VERSION "Version"

NS_ :

BS_:

BU_: ADC RLR SOC Tester

BO_ 530 RLR_Obj_17: 32 RLR
 SG_ SGU17_Msg_CheckSum : 7|8@0+ (1,0) [0|255] ""  ADC
 SG_ SGU17_Msg_AliveCounter : 11|4@0+ (1,0) [0|14] ""  ADC
 SG_ SGU17_BlockCounter : 15|4@0+ (1,0) [0|15] ""  ADC
 SG_ SGU17_Object_ID : 23|8@0+ (1,0) [0|255] ""  ADC
 SG_ SGU17_Object_wExist : 28|5@0+ (0.03125,0) [0|0.96875] ""  ADC
 SG_ SGU17_Object_Type : 31|3@0+ (1,0) [0|7] ""  ADC
 SG_ SGU17_Object_Motion_Pattern : 34|3@0+ (1,0) [0|7] ""  ADC
 SG_ SGU17_Object_wObstacle : 39|5@0+ (0.03125,0) [0|0.96875] ""  ADC
 SG_ SGU17_Object_dx : 43|12@0+ (0.0625,-128) [-128|127.9375] "m"  ADC
 SG_ SGU17_Object_dy : 59|12@0+ (0.125,-128) [-128|127.875] "m"  ADC
 SG_ SGU17_Object_DistLong_rms : 79|16@0+ (0.001953125,0) [0|127.998046875] "m"  ADC
 SG_ SGU17_Obj_DistLat_rms : 95|16@0+ (0.001953125,0) [0|127.998046875] "m"  ADC
 SG_ SGU17_Object_vx : 107|12@0+ (0.0625,-128) [-128|127.9375] "m/s"  ADC
 SG_ SGU17_Object_vy : 123|12@0+ (0.0625,-128) [-128|127.9375] "m/s"  ADC
 SG_ SGU17_Obj_VrelLong_rms : 143|16@0+ (0.001953125,0) [0|127.998046875] "m/s"  ADC
 SG_ SGU17_Obj_Vrelat_rms : 159|16@0+ (0.001953125,0) [0|127.998046875] "m/s"  ADC
 SG_ SGU17_Object_ax : 170|11@0+ (0.03125,-16) [-16|15.96875] "m/s^2"  ADC
 SG_ SGU17_Object_ay : 191|11@0+ (0.03125,-16) [-16|15.96875] "m/s^2"  ADC
 SG_ SGU17_Object_DetStatus : 173|3@0+ (1,0) [0|7] ""  ADC
 SG_ SGU17_LifeCycles_OBJ : 196|8@0+ (1,0) [0|255] ""  ADC
 SG_ SGU17_ObjRCS_17 : 204|10@0+ (0.125,-50) [-50|70] "dBm2"  ADC
 SG_ SGU17_Object_dx_Rear : 209|12@0+ (0.0625,-128) [-128|127.9375] "m"  ADC
 SG_ SGU17_Object_dy_Rear : 229|12@0+ (0.125,-128) [-128|127.875] "m"  ADC

BO_ 531 RLR_Obj_18: 32 RLR
 SG_ SGU18_Msg_CheckSum : 7|8@0+ (1,0) [0|255] ""  ADC
 SG_ SGU18_Msg_AliveCounter : 11|4@0+ (1,0) [0|14] ""  ADC
 SG_ SGU18_BlockCounter : 15|4@0+ (1,0) [0|15] ""  ADC
 SG_ SGU18_Object_ID : 23|8@0+ (1,0) [0|255] ""  ADC
 SG_ SGU18_Object_wExist : 28|5@0+ (0.03125,0) [0|0.96875] ""  ADC
 SG_ SGU18_Object_Type : 31|3@0+ (1,0) [0|7] ""  ADC
 SG_ SGU18_Object_Motion_Pattern : 34|3@0+ (1,0) [0|7] ""  ADC
 SG_ SGU18_Object_wObstacle : 39|5@0+ (0.03125,0) [0|0.96875] ""  ADC
 SG_ SGU18_Object_dx : 43|12@0+ (0.0625,-128) [-128|127.9375] "m"  ADC
 SG_ SGU18_Object_dy : 59|12@0+ (0.125,-128) [-128|127.875] "m"  ADC
 SG_ SGU18_Object_DistLong_rms : 79|16@0+ (0.001953125,0) [0|127.998046875] "m"  ADC
 SG_ SGU18_Obj_DistLat_rms : 95|16@0+ (0.001953125,0) [0|127.998046875] "m"  ADC
 SG_ SGU18_Object_vx : 107|12@0+ (0.0625,-128) [-128|127.9375] "m/s"  ADC
 SG_ SGU18_Object_vy : 123|12@0+ (0.0625,-128) [-128|127.9375] "m/s"  ADC
 SG_ SGU18_Obj_VrelLong_rms : 143|16@0+ (0.001953125,0) [0|127.998046875] "m/s"  ADC
 SG_ SGU18_Obj_Vrelat_rms : 159|16@0+ (0.001953125,0) [0|127.998046875] "m/s"  ADC
 SG_ SGU18_Object_ax : 170|11@0+ (0.03125,-16) [-16|15.96875] "m/s^2"  ADC
 SG_ SGU18_Object_ay : 191|11@0+ (0.03125,-16) [-16|15.96875] "m/s^2"  ADC
 SG_ SGU18_Object_DetStatus : 173|3@0+ (1,0) [0|7] ""  ADC
 SG_ SGU18_LifeCycles_OBJ : 196|8@0+ (1,0) [0|255] ""  ADC
 SG_ SGU18_ObjRCS_18 : 204|10@0+ (0.125,-50) [-50|70] "dBm2"  ADC
 SG_ SGU18_Object_dx_Rear : 209|12@0+ (0.0625,-128) [-128|127.9375] "m"  ADC
 SG_ SGU18_Object_dy_Rear : 229|12@0+ (0.125,-128) [-128|127.875] "m"  ADC

BO_ 532 RLR_Obj_19: 32 RLR
 SG_ SGU19_Msg_CheckSum : 7|8@0+ (1,0) [0|255] ""  ADC
 SG_ SGU19_Msg_AliveCounter : 11|4@0+ (1,0) [0|14] ""  ADC
 SG_ SGU19_BlockCounter : 15|4@0+ (1,0) [0|15] ""  ADC
 SG_ SGU19_Object_ID : 23|8@0+ (1,0) [0|255] ""  ADC
 SG_ SGU19_Object_wExist : 28|5@0+ (0.03125,0) [0|0.96875] ""  ADC
 SG_ SGU19_Object_Type : 31|3@0+ (1,0) [0|7] ""  ADC
 SG_ SGU19_Object_Motion_Pattern : 34|3@0+ (1,0) [0|7] ""  ADC
 SG_ SGU19_Object_wObstacle : 39|5@0+ (0.03125,0) [0|0.96875] ""  ADC
 SG_ SGU19_Object_dx : 43|12@0+ (0.0625,-128) [-128|127.9375] "m"  ADC
 SG_ SGU19_Object_dy : 59|12@0+ (0.125,-128) [-128|127.875] "m"  ADC
 SG_ SGU19_Object_DistLong_rms : 79|16@0+ (0.001953125,0) [0|127.998046875] "m"  ADC
 SG_ SGU19_Obj_DistLat_rms : 95|16@0+ (0.001953125,0) [0|127.998046875] "m"  ADC
 SG_ SGU19_Object_vx : 107|12@0+ (0.0625,-128) [-128|127.9375] "m/s"  ADC
 SG_ SGU19_Object_vy : 123|12@0+ (0.0625,-128) [-128|127.9375] "m/s"  ADC
 SG_ SGU19_Obj_VrelLong_rms : 143|16@0+ (0.001953125,0) [0|127.998046875] "m/s"  ADC
 SG_ SGU19_Obj_Vrelat_rms : 159|16@0+ (0.001953125,0) [0|127.998046875] "m/s"  ADC
 SG_ SGU19_Object_ax : 170|11@0+ (0.03125,-16) [-16|15.96875] "m/s^2"  ADC
 SG_ SGU19_Object_ay : 191|11@0+ (0.03125,-16) [-16|15.96875] "m/s^2"  ADC
 SG_ SGU19_Object_DetStatus : 173|3@0+ (1,0) [0|7] ""  ADC
 SG_ SGU19_LifeCycles_OBJ : 196|8@0+ (1,0) [0|255] ""  ADC
 SG_ SGU19_ObjRCS_19 : 204|10@0+ (0.125,-50) [-50|70] "dBm2"  ADC
 SG_ SGU19_Object_dx_Rear : 209|12@0+ (0.0625,-128) [-128|127.9375] "m"  ADC
 SG_ SGU19_Object_dy_Rear : 229|12@0+ (0.125,-128) [-128|127.875] "m"  ADC

BO_ 533 RLR_Obj_20: 32 RLR
 SG_ SGU20_Msg_CheckSum : 7|8@0+ (1,0) [0|255] ""  ADC
 SG_ SGU20_Msg_AliveCounter : 11|4@0+ (1,0) [0|14] ""  ADC
 SG_ SGU20_BlockCounter : 15|4@0+ (1,0) [0|15] ""  ADC
 SG_ SGU20_Object_ID : 23|8@0+ (1,0) [0|255] ""  ADC
 SG_ SGU20_Object_wExist : 28|5@0+ (0.03125,0) [0|0.96875] ""  ADC
 SG_ SGU20_Object_Type : 31|3@0+ (1,0) [0|7] ""  ADC
 SG_ SGU20_Object_Motion_Pattern : 34|3@0+ (1,0) [0|7] ""  ADC
 SG_ SGU20_Object_wObstacle : 39|5@0+ (0.03125,0) [0|0.96875] ""  ADC
 SG_ SGU20_Object_dx : 43|12@0+ (0.0625,-128) [-128|127.9375] "m"  ADC
 SG_ SGU20_Object_dy : 59|12@0+ (0.125,-128) [-128|127.875] "m"  ADC
 SG_ SGU20_Object_DistLong_rms : 79|16@0+ (0.001953125,0) [0|127.998046875] "m"  ADC
 SG_ SGU20_Obj_DistLat_rms : 95|16@0+ (0.001953125,0) [0|127.998046875] "m"  ADC
 SG_ SGU20_Object_vx : 107|12@0+ (0.0625,-128) [-128|127.9375] "m/s"  ADC
 SG_ SGU20_Object_vy : 123|12@0+ (0.0625,-128) [-128|127.9375] "m/s"  ADC
 SG_ SGU20_Obj_VrelLong_rms : 143|16@0+ (0.001953125,0) [0|127.998046875] "m/s"  ADC
 SG_ SGU20_Obj_Vrelat_rms : 159|16@0+ (0.001953125,0) [0|127.998046875] "m/s"  ADC
 SG_ SGU20_Object_ax : 170|11@0+ (0.03125,-16) [-16|15.96875] "m/s^2"  ADC
 SG_ SGU20_Object_ay : 191|11@0+ (0.03125,-16) [-16|15.96875] "m/s^2"  ADC
 SG_ SGU20_Object_DetStatus : 173|3@0+ (1,0) [0|7] ""  ADC
 SG_ SGU20_LifeCycles_OBJ : 196|8@0+ (1,0) [0|255] ""  ADC
 SG_ SGU20_ObjRCS_20 : 204|10@0+ (0.125,-50) [-50|70] "dBm2"  ADC
 SG_ SGU20_Object_dx_Rear : 209|12@0+ (0.0625,-128) [-128|127.9375] "m"  ADC
 SG_ SGU20_Object_dy_Rear : 229|12@0+ (0.125,-128) [-128|127.875] "m"  ADC

BO_ 534 RLR_Obj_21: 32 RLR
 SG_ SGU21_Msg_CheckSum : 7|8@0+ (1,0) [0|255] ""  ADC
 SG_ SGU21_Msg_AliveCounter : 11|4@0+ (1,0) [0|14] ""  ADC
 SG_ SGU21_BlockCounter : 15|4@0+ (1,0) [0|15] ""  ADC
 SG_ SGU21_Object_ID : 23|8@0+ (1,0) [0|255] ""  ADC
 SG_ SGU21_Object_wExist : 28|5@0+ (0.03125,0) [0|0.96875] ""  ADC
 SG_ SGU21_Object_Type : 31|3@0+ (1,0) [0|7] ""  ADC
 SG_ SGU21_Object_Motion_Pattern : 34|3@0+ (1,0) [0|7] ""  ADC
 SG_ SGU21_Object_wObstacle : 39|5@0+ (0.03125,0) [0|0.96875] ""  ADC
 SG_ SGU21_Object_dx : 43|12@0+ (0.0625,-128) [-128|127.9375] "m"  ADC
 SG_ SGU21_Object_dy : 59|12@0+ (0.125,-128) [-128|127.875] "m"  ADC
 SG_ SGU21_Object_DistLong_rms : 79|16@0+ (0.001953125,0) [0|127.998046875] "m"  ADC
 SG_ SGU21_Obj_DistLat_rms : 95|16@0+ (0.001953125,0) [0|127.998046875] "m"  ADC
 SG_ SGU21_Object_vx : 107|12@0+ (0.0625,-128) [-128|127.9375] "m/s"  ADC
 SG_ SGU21_Object_vy : 123|12@0+ (0.0625,-128) [-128|127.9375] "m/s"  ADC
 SG_ SGU21_Obj_VrelLong_rms : 143|16@0+ (0.001953125,0) [0|127.998046875] "m/s"  ADC
 SG_ SGU21_Obj_Vrelat_rms : 159|16@0+ (0.001953125,0) [0|127.998046875] "m/s"  ADC
 SG_ SGU21_Object_ax : 170|11@0+ (0.03125,-16) [-16|15.96875] "m/s^2"  ADC
 SG_ SGU21_Object_ay : 191|11@0+ (0.03125,-16) [-16|15.96875] "m/s^2"  ADC
 SG_ SGU21_Object_DetStatus : 173|3@0+ (1,0) [0|7] ""  ADC
 SG_ SGU21_LifeCycles_OBJ : 196|8@0+ (1,0) [0|255] ""  ADC
 SG_ SGU21_ObjRCS_21 : 204|10@0+ (0.125,-50) [-50|70] "dBm2"  ADC
 SG_ SGU21_Object_dx_Rear : 209|12@0+ (0.0625,-128) [-128|127.9375] "m"  ADC
 SG_ SGU21_Object_dy_Rear : 229|12@0+ (0.125,-128) [-128|127.875] "m"  ADC

BO_ 535 RLR_Obj_22: 32 RLR
 SG_ SGU22_Msg_CheckSum : 7|8@0+ (1,0) [0|255] ""  ADC
 SG_ SGU22_Msg_AliveCounter : 11|4@0+ (1,0) [0|14] ""  ADC
 SG_ SGU22_BlockCounter : 15|4@0+ (1,0) [0|15] ""  ADC
 SG_ SGU22_Object_ID : 23|8@0+ (1,0) [0|255] ""  ADC
 SG_ SGU22_Object_wExist : 28|5@0+ (0.03125,0) [0|0.96875] ""  ADC
 SG_ SGU22_Object_Type : 31|3@0+ (1,0) [0|7] ""  ADC
 SG_ SGU22_Object_Motion_Pattern : 34|3@0+ (1,0) [0|7] ""  ADC
 SG_ SGU22_Object_wObstacle : 39|5@0+ (0.03125,0) [0|0.96875] ""  ADC
 SG_ SGU22_Object_dx : 43|12@0+ (0.0625,-128) [-128|127.9375] "m"  ADC
 SG_ SGU22_Object_dy : 59|12@0+ (0.125,-128) [-128|127.875] "m"  ADC
 SG_ SGU22_Object_DistLong_rms : 79|16@0+ (0.001953125,0) [0|127.998046875] "m"  ADC
 SG_ SGU22_Obj_DistLat_rms : 95|16@0+ (0.001953125,0) [0|127.998046875] "m"  ADC
 SG_ SGU22_Object_vx : 107|12@0+ (0.0625,-128) [-128|127.9375] "m/s"  ADC
 SG_ SGU22_Object_vy : 123|12@0+ (0.0625,-128) [-128|127.9375] "m/s"  ADC
 SG_ SGU22_Obj_VrelLong_rms : 143|16@0+ (0.001953125,0) [0|127.998046875] "m/s"  ADC
 SG_ SGU22_Obj_Vrelat_rms : 159|16@0+ (0.001953125,0) [0|127.998046875] "m/s"  ADC
 SG_ SGU22_Object_ax : 170|11@0+ (0.03125,-16) [-16|15.96875] "m/s^2"  ADC
 SG_ SGU22_Object_ay : 191|11@0+ (0.03125,-16) [-16|15.96875] "m/s^2"  ADC
 SG_ SGU22_Object_DetStatus : 173|3@0+ (1,0) [0|7] ""  ADC
 SG_ SGU22_LifeCycles_OBJ : 196|8@0+ (1,0) [0|255] ""  ADC
 SG_ SGU22_ObjRCS_22 : 204|10@0+ (0.125,-50) [-50|70] "dBm2"  ADC
 SG_ SGU22_Object_dx_Rear : 209|12@0+ (0.0625,-128) [-128|127.9375] "m"  ADC
 SG_ SGU22_Object_dy_Rear : 229|12@0+ (0.125,-128) [-128|127.875] "m"  ADC

BO_ 536 RLR_Obj_23: 32 RLR
 SG_ SGU23_Msg_CheckSum : 7|8@0+ (1,0) [0|255] ""  ADC
 SG_ SGU23_Msg_AliveCounter : 11|4@0+ (1,0) [0|14] ""  ADC
 SG_ SGU23_BlockCounter : 15|4@0+ (1,0) [0|15] ""  ADC
 SG_ SGU23_Object_ID : 23|8@0+ (1,0) [0|255] ""  ADC
 SG_ SGU23_Object_wExist : 28|5@0+ (0.03125,0) [0|0.96875] ""  ADC
 SG_ SGU23_Object_Type : 31|3@0+ (1,0) [0|7] ""  ADC
 SG_ SGU23_Object_Motion_Pattern : 34|3@0+ (1,0) [0|7] ""  ADC
 SG_ SGU23_Object_wObstacle : 39|5@0+ (0.03125,0) [0|0.96875] ""  ADC
 SG_ SGU23_Object_dx : 43|12@0+ (0.0625,-128) [-128|127.9375] "m"  ADC
 SG_ SGU23_Object_dy : 59|12@0+ (0.125,-128) [-128|127.875] "m"  ADC
 SG_ SGU23_Object_DistLong_rms : 79|16@0+ (0.001953125,0) [0|127.998046875] "m"  ADC
 SG_ SGU23_Obj_DistLat_rms : 95|16@0+ (0.001953125,0) [0|127.998046875] "m"  ADC
 SG_ SGU23_Object_vx : 107|12@0+ (0.0625,-128) [-128|127.9375] "m/s"  ADC
 SG_ SGU23_Object_vy : 123|12@0+ (0.0625,-128) [-128|127.9375] "m/s"  ADC
 SG_ SGU23_Obj_VrelLong_rms : 143|16@0+ (0.001953125,0) [0|127.998046875] "m/s"  ADC
 SG_ SGU23_Obj_Vrelat_rms : 159|16@0+ (0.001953125,0) [0|127.998046875] "m/s"  ADC
 SG_ SGU23_Object_ax : 170|11@0+ (0.03125,-16) [-16|15.96875] "m/s^2"  ADC
 SG_ SGU23_Object_ay : 191|11@0+ (0.03125,-16) [-16|15.96875] "m/s^2"  ADC
 SG_ SGU23_Object_DetStatus : 173|3@0+ (1,0) [0|7] ""  ADC
 SG_ SGU23_LifeCycles_OBJ : 196|8@0+ (1,0) [0|255] ""  ADC
 SG_ SGU23_ObjRCS_23 : 204|10@0+ (0.125,-50) [-50|70] "dBm2"  ADC
 SG_ SGU23_Object_dx_Rear : 209|12@0+ (0.0625,-128) [-128|127.9375] "m"  ADC
 SG_ SGU23_Object_dy_Rear : 229|12@0+ (0.125,-128) [-128|127.875] "m"  ADC

BO_ 537 RLR_Obj_24: 32 RLR
 SG_ SGU24_Msg_CheckSum : 7|8@0+ (1,0) [0|255] ""  ADC
 SG_ SGU24_Msg_AliveCounter : 11|4@0+ (1,0) [0|14] ""  ADC
 SG_ SGU24_BlockCounter : 15|4@0+ (1,0) [0|15] ""  ADC
 SG_ SGU24_Object_ID : 23|8@0+ (1,0) [0|255] ""  ADC
 SG_ SGU24_Object_wExist : 28|5@0+ (0.03125,0) [0|0.96875] ""  ADC
 SG_ SGU24_Object_Type : 31|3@0+ (1,0) [0|7] ""  ADC
 SG_ SGU24_Object_Motion_Pattern : 34|3@0+ (1,0) [0|7] ""  ADC
 SG_ SGU24_Object_wObstacle : 39|5@0+ (0.03125,0) [0|0.96875] ""  ADC
 SG_ SGU24_Object_dx : 43|12@0+ (0.0625,-128) [-128|127.9375] "m"  ADC
 SG_ SGU24_Object_dy : 59|12@0+ (0.125,-128) [-128|127.875] "m"  ADC
 SG_ SGU24_Object_DistLong_rms : 79|16@0+ (0.001953125,0) [0|127.998046875] "m"  ADC
 SG_ SGU24_Obj_DistLat_rms : 95|16@0+ (0.001953125,0) [0|127.998046875] "m"  ADC
 SG_ SGU24_Object_vx : 107|12@0+ (0.0625,-128) [-128|127.9375] "m/s"  ADC
 SG_ SGU24_Object_vy : 123|12@0+ (0.0625,-128) [-128|127.9375] "m/s"  ADC
 SG_ SGU24_Obj_VrelLong_rms : 143|16@0+ (0.001953125,0) [0|127.998046875] "m/s"  ADC
 SG_ SGU24_Obj_Vrelat_rms : 159|16@0+ (0.001953125,0) [0|127.998046875] "m/s"  ADC
 SG_ SGU24_Object_ax : 170|11@0+ (0.03125,-16) [-16|15.96875] "m/s^2"  ADC
 SG_ SGU24_Object_ay : 191|11@0+ (0.03125,-16) [-16|15.96875] "m/s^2"  ADC
 SG_ SGU24_Object_DetStatus : 173|3@0+ (1,0) [0|7] ""  ADC
 SG_ SGU24_LifeCycles_OBJ : 196|8@0+ (1,0) [0|255] ""  ADC
 SG_ SGU24_ObjRCS_24 : 204|10@0+ (0.125,-50) [-50|70] "dBm2"  ADC
 SG_ SGU24_Object_dx_Rear : 209|12@0+ (0.0625,-128) [-128|127.9375] "m"  ADC
 SG_ SGU24_Object_dy_Rear : 229|12@0+ (0.125,-128) [-128|127.875] "m"  ADC

BO_ 538 RLR_Obj_25: 32 RLR
 SG_ SGU25_Msg_CheckSum : 7|8@0+ (1,0) [0|255] ""  ADC
 SG_ SGU25_Msg_AliveCounter : 11|4@0+ (1,0) [0|14] ""  ADC
 SG_ SGU25_BlockCounter : 15|4@0+ (1,0) [0|15] ""  ADC
 SG_ SGU25_Object_ID : 23|8@0+ (1,0) [0|255] ""  ADC
 SG_ SGU25_Object_wExist : 28|5@0+ (0.03125,0) [0|0.96875] ""  ADC
 SG_ SGU25_Object_Type : 31|3@0+ (1,0) [0|7] ""  ADC
 SG_ SGU25_Object_Motion_Pattern : 34|3@0+ (1,0) [0|7] ""  ADC
 SG_ SGU25_Object_wObstacle : 39|5@0+ (0.03125,0) [0|0.96875] ""  ADC
 SG_ SGU25_Object_dx : 43|12@0+ (0.0625,-128) [-128|127.9375] "m"  ADC
 SG_ SGU25_Object_dy : 59|12@0+ (0.125,-128) [-128|127.875] "m"  ADC
 SG_ SGU25_Object_DistLong_rms : 79|16@0+ (0.001953125,0) [0|127.998046875] "m"  ADC
 SG_ SGU25_Obj_DistLat_rms : 95|16@0+ (0.001953125,0) [0|127.998046875] "m"  ADC
 SG_ SGU25_Object_vx : 107|12@0+ (0.0625,-128) [-128|127.9375] "m/s"  ADC
 SG_ SGU25_Object_vy : 123|12@0+ (0.0625,-128) [-128|127.9375] "m/s"  ADC
 SG_ SGU25_Obj_VrelLong_rms : 143|16@0+ (0.001953125,0) [0|127.998046875] "m/s"  ADC
 SG_ SGU25_Obj_Vrelat_rms : 159|16@0+ (0.001953125,0) [0|127.998046875] "m/s"  ADC
 SG_ SGU25_Object_ax : 170|11@0+ (0.03125,-16) [-16|15.96875] "m/s^2"  ADC
 SG_ SGU25_Object_ay : 191|11@0+ (0.03125,-16) [-16|15.96875] "m/s^2"  ADC
 SG_ SGU25_Object_DetStatus : 173|3@0+ (1,0) [0|7] ""  ADC
 SG_ SGU25_LifeCycles_OBJ : 196|8@0+ (1,0) [0|255] ""  ADC
 SG_ SGU25_ObjRCS_25 : 204|10@0+ (0.125,-50) [-50|70] "dBm2"  ADC
 SG_ SGU25_Object_dx_Rear : 209|12@0+ (0.0625,-128) [-128|127.9375] "m"  ADC
 SG_ SGU25_Object_dy_Rear : 229|12@0+ (0.125,-128) [-128|127.875] "m"  ADC

BO_ 539 RLR_Obj_26: 32 RLR
 SG_ SGU26_Msg_CheckSum : 7|8@0+ (1,0) [0|255] ""  ADC
 SG_ SGU26_Msg_AliveCounter : 11|4@0+ (1,0) [0|14] ""  ADC
 SG_ SGU26_BlockCounter : 15|4@0+ (1,0) [0|15] ""  ADC
 SG_ SGU26_Object_ID : 23|8@0+ (1,0) [0|255] ""  ADC
 SG_ SGU26_Object_wExist : 28|5@0+ (0.03125,0) [0|0.96875] ""  ADC
 SG_ SGU26_Object_Type : 31|3@0+ (1,0) [0|7] ""  ADC
 SG_ SGU26_Object_Motion_Pattern : 34|3@0+ (1,0) [0|7] ""  ADC
 SG_ SGU26_Object_wObstacle : 39|5@0+ (0.03125,0) [0|0.96875] ""  ADC
 SG_ SGU26_Object_dx : 43|12@0+ (0.0625,-128) [-128|127.9375] "m"  ADC
 SG_ SGU26_Object_dy : 59|12@0+ (0.125,-128) [-128|127.875] "m"  ADC
 SG_ SGU26_Object_DistLong_rms : 79|16@0+ (0.001953125,0) [0|127.998046875] "m"  ADC
 SG_ SGU26_Obj_DistLat_rms : 95|16@0+ (0.001953125,0) [0|127.998046875] "m"  ADC
 SG_ SGU26_Object_vx : 107|12@0+ (0.0625,-128) [-128|127.9375] "m/s"  ADC
 SG_ SGU26_Object_vy : 123|12@0+ (0.0625,-128) [-128|127.9375] "m/s"  ADC
 SG_ SGU26_Obj_VrelLong_rms : 143|16@0+ (0.001953125,0) [0|127.998046875] "m/s"  ADC
 SG_ SGU26_Obj_Vrelat_rms : 159|16@0+ (0.001953125,0) [0|127.998046875] "m/s"  ADC
 SG_ SGU26_Object_ax : 170|11@0+ (0.03125,-16) [-16|15.96875] "m/s^2"  ADC
 SG_ SGU26_Object_ay : 191|11@0+ (0.03125,-16) [-16|15.96875] "m/s^2"  ADC
 SG_ SGU26_Object_DetStatus : 173|3@0+ (1,0) [0|7] ""  ADC
 SG_ SGU26_LifeCycles_OBJ : 196|8@0+ (1,0) [0|255] ""  ADC
 SG_ SGU26_ObjRCS_26 : 204|10@0+ (0.125,-50) [-50|70] "dBm2"  ADC
 SG_ SGU26_Object_dx_Rear : 209|12@0+ (0.0625,-128) [-128|127.9375] "m"  ADC
 SG_ SGU26_Object_dy_Rear : 229|12@0+ (0.125,-128) [-128|127.875] "m"  ADC

BO_ 540 RLR_Obj_27: 32 RLR
 SG_ SGU27_Msg_CheckSum : 7|8@0+ (1,0) [0|255] ""  ADC
 SG_ SGU27_Msg_AliveCounter : 11|4@0+ (1,0) [0|14] ""  ADC
 SG_ SGU27_BlockCounter : 15|4@0+ (1,0) [0|15] ""  ADC
 SG_ SGU27_Object_ID : 23|8@0+ (1,0) [0|255] ""  ADC
 SG_ SGU27_Object_wExist : 28|5@0+ (0.03125,0) [0|0.96875] ""  ADC
 SG_ SGU27_Object_Type : 31|3@0+ (1,0) [0|7] ""  ADC
 SG_ SGU27_Object_Motion_Pattern : 34|3@0+ (1,0) [0|7] ""  ADC
 SG_ SGU27_Object_wObstacle : 39|5@0+ (0.03125,0) [0|0.96875] ""  ADC
 SG_ SGU27_Object_dx : 43|12@0+ (0.0625,-128) [-128|127.9375] "m"  ADC
 SG_ SGU27_Object_dy : 59|12@0+ (0.125,-128) [-128|127.875] "m"  ADC
 SG_ SGU27_Object_DistLong_rms : 79|16@0+ (0.001953125,0) [0|127.998046875] "m"  ADC
 SG_ SGU27_Obj_DistLat_rms : 95|16@0+ (0.001953125,0) [0|127.998046875] "m"  ADC
 SG_ SGU27_Object_vx : 107|12@0+ (0.0625,-128) [-128|127.9375] "m/s"  ADC
 SG_ SGU27_Object_vy : 123|12@0+ (0.0625,-128) [-128|127.9375] "m/s"  ADC
 SG_ SGU27_Obj_VrelLong_rms : 143|16@0+ (0.001953125,0) [0|127.998046875] "m/s"  ADC
 SG_ SGU27_Obj_Vrelat_rms : 159|16@0+ (0.001953125,0) [0|127.998046875] "m/s"  ADC
 SG_ SGU27_Object_ax : 170|11@0+ (0.03125,-16) [-16|15.96875] "m/s^2"  ADC
 SG_ SGU27_Object_ay : 191|11@0+ (0.03125,-16) [-16|15.96875] "m/s^2"  ADC
 SG_ SGU27_Object_DetStatus : 173|3@0+ (1,0) [0|7] ""  ADC
 SG_ SGU27_LifeCycles_OBJ : 196|8@0+ (1,0) [0|255] ""  ADC
 SG_ SGU27_ObjRCS_27 : 204|10@0+ (0.125,-50) [-50|70] "dBm2"  ADC
 SG_ SGU27_Object_dx_Rear : 209|12@0+ (0.0625,-128) [-128|127.9375] "m"  ADC
 SG_ SGU27_Object_dy_Rear : 229|12@0+ (0.125,-128) [-128|127.875] "m"  ADC

BO_ 541 RLR_Obj_28: 32 RLR
 SG_ SGU28_Msg_CheckSum : 7|8@0+ (1,0) [0|255] ""  ADC
 SG_ SGU28_Msg_AliveCounter : 11|4@0+ (1,0) [0|14] ""  ADC
 SG_ SGU28_BlockCounter : 15|4@0+ (1,0) [0|15] ""  ADC
 SG_ SGU28_Object_ID : 23|8@0+ (1,0) [0|255] ""  ADC
 SG_ SGU28_Object_wExist : 28|5@0+ (0.03125,0) [0|0.96875] ""  ADC
 SG_ SGU28_Object_Type : 31|3@0+ (1,0) [0|7] ""  ADC
 SG_ SGU28_Object_Motion_Pattern : 34|3@0+ (1,0) [0|7] ""  ADC
 SG_ SGU28_Object_wObstacle : 39|5@0+ (0.03125,0) [0|0.96875] ""  ADC
 SG_ SGU28_Object_dx : 43|12@0+ (0.0625,-128) [-128|127.9375] "m"  ADC
 SG_ SGU28_Object_dy : 59|12@0+ (0.125,-128) [-128|127.875] "m"  ADC
 SG_ SGU28_Object_DistLong_rms : 79|16@0+ (0.001953125,0) [0|127.998046875] "m"  ADC
 SG_ SGU28_Obj_DistLat_rms : 95|16@0+ (0.001953125,0) [0|127.998046875] "m"  ADC
 SG_ SGU28_Object_vx : 107|12@0+ (0.0625,-128) [-128|127.9375] "m/s"  ADC
 SG_ SGU28_Object_vy : 123|12@0+ (0.0625,-128) [-128|127.9375] "m/s"  ADC
 SG_ SGU28_Obj_VrelLong_rms : 143|16@0+ (0.001953125,0) [0|127.998046875] "m/s"  ADC
 SG_ SGU28_Obj_Vrelat_rms : 159|16@0+ (0.001953125,0) [0|127.998046875] "m/s"  ADC
 SG_ SGU28_Object_ax : 170|11@0+ (0.03125,-16) [-16|15.96875] "m/s^2"  ADC
 SG_ SGU28_Object_ay : 191|11@0+ (0.03125,-16) [-16|15.96875] "m/s^2"  ADC
 SG_ SGU28_Object_DetStatus : 173|3@0+ (1,0) [0|7] ""  ADC
 SG_ SGU28_LifeCycles_OBJ : 196|8@0+ (1,0) [0|255] ""  ADC
 SG_ SGU28_ObjRCS_28 : 204|10@0+ (0.125,-50) [-50|70] "dBm2"  ADC
 SG_ SGU28_Object_dx_Rear : 209|12@0+ (0.0625,-128) [-128|127.9375] "m"  ADC
 SG_ SGU28_Object_dy_Rear : 229|12@0+ (0.125,-128) [-128|127.875] "m"  ADC

BO_ 542 RLR_Obj_29: 32 RLR
 SG_ SGU29_Msg_CheckSum : 7|8@0+ (1,0) [0|255] ""  ADC
 SG_ SGU29_Msg_AliveCounter : 11|4@0+ (1,0) [0|14] ""  ADC
 SG_ SGU29_BlockCounter : 15|4@0+ (1,0) [0|15] ""  ADC
 SG_ SGU29_Object_ID : 23|8@0+ (1,0) [0|255] ""  ADC
 SG_ SGU29_Object_wExist : 28|5@0+ (0.03125,0) [0|0.96875] ""  ADC
 SG_ SGU29_Object_Type : 31|3@0+ (1,0) [0|7] ""  ADC
 SG_ SGU29_Object_Motion_Pattern : 34|3@0+ (1,0) [0|7] ""  ADC
 SG_ SGU29_Object_wObstacle : 39|5@0+ (0.03125,0) [0|0.96875] ""  ADC
 SG_ SGU29_Object_dx : 43|12@0+ (0.0625,-128) [-128|127.9375] "m"  ADC
 SG_ SGU29_Object_dy : 59|12@0+ (0.125,-128) [-128|127.875] "m"  ADC
 SG_ SGU29_Object_DistLong_rms : 79|16@0+ (0.001953125,0) [0|127.998046875] "m"  ADC
 SG_ SGU29_Obj_DistLat_rms : 95|16@0+ (0.001953125,0) [0|127.998046875] "m"  ADC
 SG_ SGU29_Object_vx : 107|12@0+ (0.0625,-128) [-128|127.9375] "m/s"  ADC
 SG_ SGU29_Object_vy : 123|12@0+ (0.0625,-128) [-128|127.9375] "m/s"  ADC
 SG_ SGU29_Obj_VrelLong_rms : 143|16@0+ (0.001953125,0) [0|127.998046875] "m/s"  ADC
 SG_ SGU29_Obj_Vrelat_rms : 159|16@0+ (0.001953125,0) [0|127.998046875] "m/s"  ADC
 SG_ SGU29_Object_ax : 170|11@0+ (0.03125,-16) [-16|15.96875] "m/s^2"  ADC
 SG_ SGU29_Object_ay : 191|11@0+ (0.03125,-16) [-16|15.96875] "m/s^2"  ADC
 SG_ SGU29_Object_DetStatus : 173|3@0+ (1,0) [0|7] ""  ADC
 SG_ SGU29_LifeCycles_OBJ : 196|8@0+ (1,0) [0|255] ""  ADC
 SG_ SGU29_ObjRCS_29 : 204|10@0+ (0.125,-50) [-50|70] "dBm2"  ADC
 SG_ SGU29_Object_dx_Rear : 209|12@0+ (0.0625,-128) [-128|127.9375] "m"  ADC
 SG_ SGU29_Object_dy_Rear : 229|12@0+ (0.125,-128) [-128|127.875] "m"  ADC

BO_ 543 RLR_Obj_30: 32 RLR
 SG_ SGU30_Msg_CheckSum : 7|8@0+ (1,0) [0|255] ""  ADC
 SG_ SGU30_Msg_AliveCounter : 11|4@0+ (1,0) [0|14] ""  ADC
 SG_ SGU30_BlockCounter : 15|4@0+ (1,0) [0|15] ""  ADC
 SG_ SGU30_Object_ID : 23|8@0+ (1,0) [0|255] ""  ADC
 SG_ SGU30_Object_wExist : 28|5@0+ (0.03125,0) [0|0.96875] ""  ADC
 SG_ SGU30_Object_Type : 31|3@0+ (1,0) [0|7] ""  ADC
 SG_ SGU30_Object_Motion_Pattern : 34|3@0+ (1,0) [0|7] ""  ADC
 SG_ SGU30_Object_wObstacle : 39|5@0+ (0.03125,0) [0|0.96875] ""  ADC
 SG_ SGU30_Object_dx : 43|12@0+ (0.0625,-128) [-128|127.9375] "m"  ADC
 SG_ SGU30_Object_dy : 59|12@0+ (0.125,-128) [-128|127.875] "m"  ADC
 SG_ SGU30_Object_DistLong_rms : 79|16@0+ (0.001953125,0) [0|127.998046875] "m"  ADC
 SG_ SGU30_Obj_DistLat_rms : 95|16@0+ (0.001953125,0) [0|127.998046875] "m"  ADC
 SG_ SGU30_Object_vx : 107|12@0+ (0.0625,-128) [-128|127.9375] "m/s"  ADC
 SG_ SGU30_Object_vy : 123|12@0+ (0.0625,-128) [-128|127.9375] "m/s"  ADC
 SG_ SGU30_Obj_VrelLong_rms : 143|16@0+ (0.001953125,0) [0|127.998046875] "m/s"  ADC
 SG_ SGU30_Obj_Vrelat_rms : 159|16@0+ (0.001953125,0) [0|127.998046875] "m/s"  ADC
 SG_ SGU30_Object_ax : 170|11@0+ (0.03125,-16) [-16|15.96875] "m/s^2"  ADC
 SG_ SGU30_Object_ay : 191|11@0+ (0.03125,-16) [-16|15.96875] "m/s^2"  ADC
 SG_ SGU30_Object_DetStatus : 173|3@0+ (1,0) [0|7] ""  ADC
 SG_ SGU30_LifeCycles_OBJ : 196|8@0+ (1,0) [0|255] ""  ADC
 SG_ SGU30_ObjRCS_30 : 204|10@0+ (0.125,-50) [-50|70] "dBm2"  ADC
 SG_ SGU30_Object_dx_Rear : 209|12@0+ (0.0625,-128) [-128|127.9375] "m"  ADC
 SG_ SGU30_Object_dy_Rear : 229|12@0+ (0.125,-128) [-128|127.875] "m"  ADC

BO_ 544 RLR_Obj_31: 32 RLR
 SG_ SGU31_Msg_CheckSum : 7|8@0+ (1,0) [0|255] ""  ADC
 SG_ SGU31_Msg_AliveCounter : 11|4@0+ (1,0) [0|14] ""  ADC
 SG_ SGU31_BlockCounter : 15|4@0+ (1,0) [0|15] ""  ADC
 SG_ SGU31_Object_ID : 23|8@0+ (1,0) [0|255] ""  ADC
 SG_ SGU31_Object_wExist : 28|5@0+ (0.03125,0) [0|0.96875] ""  ADC
 SG_ SGU31_Object_Type : 31|3@0+ (1,0) [0|7] ""  ADC
 SG_ SGU31_Object_Motion_Pattern : 34|3@0+ (1,0) [0|7] ""  ADC
 SG_ SGU31_Object_wObstacle : 39|5@0+ (0.03125,0) [0|0.96875] ""  ADC
 SG_ SGU31_Object_dx : 43|12@0+ (0.0625,-128) [-128|127.9375] "m"  ADC
 SG_ SGU31_Object_dy : 59|12@0+ (0.125,-128) [-128|127.875] "m"  ADC
 SG_ SGU31_Object_DistLong_rms : 79|16@0+ (0.001953125,0) [0|127.998046875] "m"  ADC
 SG_ SGU31_Obj_DistLat_rms : 95|16@0+ (0.001953125,0) [0|127.998046875] "m"  ADC
 SG_ SGU31_Object_vx : 107|12@0+ (0.0625,-128) [-128|127.9375] "m/s"  ADC
 SG_ SGU31_Object_vy : 123|12@0+ (0.0625,-128) [-128|127.9375] "m/s"  ADC
 SG_ SGU31_Obj_VrelLong_rms : 143|16@0+ (0.001953125,0) [0|127.998046875] "m/s"  ADC
 SG_ SGU31_Obj_Vrelat_rms : 159|16@0+ (0.001953125,0) [0|127.998046875] "m/s"  ADC
 SG_ SGU31_Object_ax : 170|11@0+ (0.03125,-16) [-16|15.96875] "m/s^2"  ADC
 SG_ SGU31_Object_ay : 191|11@0+ (0.03125,-16) [-16|15.96875] "m/s^2"  ADC
 SG_ SGU31_Object_DetStatus : 173|3@0+ (1,0) [0|7] ""  ADC
 SG_ SGU31_LifeCycles_OBJ : 196|8@0+ (1,0) [0|255] ""  ADC
 SG_ SGU31_ObjRCS_31 : 204|10@0+ (0.125,-50) [-50|70] "dBm2"  ADC
 SG_ SGU31_Object_dx_Rear : 209|12@0+ (0.0625,-128) [-128|127.9375] "m"  ADC
 SG_ SGU31_Object_dy_Rear : 229|12@0+ (0.125,-128) [-128|127.875] "m"  ADC

BO_ 545 RLR_Obj_32: 32 RLR
 SG_ SGU32_Msg_CheckSum : 7|8@0+ (1,0) [0|255] ""  ADC
 SG_ SGU32_Msg_AliveCounter : 11|4@0+ (1,0) [0|14] ""  ADC
 SG_ SGU32_BlockCounter : 15|4@0+ (1,0) [0|15] ""  ADC
 SG_ SGU32_Object_ID : 23|8@0+ (1,0) [0|255] ""  ADC
 SG_ SGU32_Object_wExist : 28|5@0+ (0.03125,0) [0|0.96875] ""  ADC
 SG_ SGU32_Object_Type : 31|3@0+ (1,0) [0|7] ""  ADC
 SG_ SGU32_Object_Motion_Pattern : 34|3@0+ (1,0) [0|7] ""  ADC
 SG_ SGU32_Object_wObstacle : 39|5@0+ (0.03125,0) [0|0.96875] ""  ADC
 SG_ SGU32_Object_dx : 43|12@0+ (0.0625,-128) [-128|127.9375] "m"  ADC
 SG_ SGU32_Object_dy : 59|12@0+ (0.125,-128) [-128|127.875] "m"  ADC
 SG_ SGU32_Object_DistLong_rms : 79|16@0+ (0.001953125,0) [0|127.998046875] "m"  ADC
 SG_ SGU32_Obj_DistLat_rms : 95|16@0+ (0.001953125,0) [0|127.998046875] "m"  ADC
 SG_ SGU32_Object_vx : 107|12@0+ (0.0625,-128) [-128|127.9375] "m/s"  ADC
 SG_ SGU32_Object_vy : 123|12@0+ (0.0625,-128) [-128|127.9375] "m/s"  ADC
 SG_ SGU32_Obj_VrelLong_rms : 143|16@0+ (0.001953125,0) [0|127.998046875] "m/s"  ADC
 SG_ SGU32_Obj_Vrelat_rms : 159|16@0+ (0.001953125,0) [0|127.998046875] "m/s"  ADC
 SG_ SGU32_Object_ax : 170|11@0+ (0.03125,-16) [-16|15.96875] "m/s^2"  ADC
 SG_ SGU32_Object_ay : 191|11@0+ (0.03125,-16) [-16|15.96875] "m/s^2"  ADC
 SG_ SGU32_Object_DetStatus : 173|3@0+ (1,0) [0|7] ""  ADC
 SG_ SGU32_LifeCycles_OBJ : 196|8@0+ (1,0) [0|255] ""  ADC
 SG_ SGU32_ObjRCS_32 : 204|10@0+ (0.125,-50) [-50|70] "dBm2"  ADC
 SG_ SGU32_Object_dx_Rear : 209|12@0+ (0.0625,-128) [-128|127.9375] "m"  ADC
 SG_ SGU32_Object_dy_Rear : 229|12@0+ (0.125,-128) [-128|127.875] "m"  ADC

BO_ 546 RLR_RadarInfo: 32 RLR
 SG_ RLR_RadarInfor_Checksum : 7|8@0+ (1,0) [0|255] ""  ADC
 SG_ RLR_RadarInfor_AliveCounter : 11|4@0+ (1,0) [0|14] ""  ADC
 SG_ mountAngleIndicator_az : 31|9@0+ (0.05,-12.8) [-12.8|12.75] "degree"  ADC
 SG_ mountAngleCurrent_az : 38|9@0+ (0.05,-12.8) [-12.8|12.75] "degree"  ADC
 SG_ mountAngleIndicator_el : 45|9@0+ (0.05,-12.8) [-12.8|12.75] "degree"  ADC
 SG_ mountAngleCurrent_el : 52|9@0+ (0.05,-12.8) [-12.8|12.75] "degree"  ADC
 SG_ malStablePosAz : 59|9@0+ (0.05,-12.8) [-12.8|12.75] "degree"  ADC
 SG_ malStablePosEl : 66|9@0+ (0.05,-12.8) [-12.8|12.75] "degree"  ADC
 SG_ AngleEMEIndicatorAz : 73|9@0+ (0.05,-12.8) [-12.8|12.75] "degree"  ADC
 SG_ AngleEMEIndicatorEl : 95|9@0+ (0.05,-12.8) [-12.8|12.75] "degree"  ADC
 SG_ FilteredPhiSpread : 102|11@0+ (0.1,-102.4) [-102.4|102.3] "m"  ADC
 SG_ highSpreadIndicator_el : 107|9@0+ (0.05,-12.8) [-12.8|12.75] "degree"  ADC
 SG_ highSpreadIndicator_az : 114|9@0+ (0.05,-12.8) [-12.8|12.75] "degree"  ADC
 SG_ elOutOfSpecCause : 129|2@0+ (1,0) [0|3] ""  ADC
 SG_ azOutOfSpecCause : 131|2@0+ (1,0) [0|3] ""  ADC
 SG_ Fault_MAL_HOR_ABS_EVENT : 132|1@0+ (1,0) [0|1] ""  ADC
 SG_ Fault_MAL_HOR_REL_EVENT : 133|1@0+ (1,0) [0|1] ""  ADC
 SG_ Fault_MAL_VER_ABS_EVENT : 134|1@0+ (1,0) [0|1] ""  ADC
 SG_ Fault_MAL_VER_REL_EVENT : 135|1@0+ (1,0) [0|1] ""  ADC
 SG_ azOutOfProfileCause : 143|8@0+ (1,0) [0|255] ""  ADC
 SG_ elOutOfProfileCause : 151|8@0+ (1,0) [0|255] ""  ADC
 SG_ RLR_SW_Baseline : 155|4@0+ (1,0) [0|15] ""  ADC
 SG_ RLR_SW_ReleaseType : 159|4@0+ (1,0) [0|15] ""  ADC
 SG_ RLR_SW_MajorVersion : 163|4@0+ (1,0) [0|15] ""  ADC
 SG_ RLR_SW_MinorVersion : 167|4@0+ (1,0) [0|15] ""  ADC
 SG_ RLR_SDA_CalibrationSts : 175|8@0+ (1,0) [0|255] ""  ADC
 SG_ RLR_EOL_CalibrationSts : 183|8@0+ (1,0) [0|255] ""  ADC
 SG_ RLR_Blindness_FaultSts : 192|1@0+ (1,0) [0|1] ""  ADC
 SG_ RLR_ModulationSts : 193|1@0+ (1,0) [0|1] ""  ADC
 SG_ RLR_Misalignment_FaultSts : 194|1@0+ (1,0) [0|1] ""  ADC
 SG_ RLR_Radar_FaultSts : 207|8@0+ (1,0) [0|31] ""  ADC
 SG_ RLR_DTC_VBAT_HIGH : 208|1@0+ (1,0) [0|1] ""  ADC
 SG_ RLR_DTC_VBAT_LOW : 209|1@0+ (1,0) [0|1] ""  ADC
 SG_ RLR_DTC_HARDWARE_FAILURE : 210|1@0+ (1,0) [0|1] ""  ADC
 SG_ RLR_DTC_RADAR_OVER_TEMPERATURE : 211|1@0+ (1,0) [0|1] ""  ADC
 SG_ RLR_DTC_CORNER_RADAR_BLIND : 212|1@0+ (1,0) [0|1] ""  ADC
 SG_ RLR_DTC_CORNER_RADAR_MISALIGNED : 213|1@0+ (1,0) [0|1] ""  ADC
 SG_ RLR_DTC_DACORE_OOS : 214|1@0+ (1,0) [0|1] ""  ADC
 SG_ RLR_DTC_DSP_FAILURE : 215|1@0+ (1,0) [0|1] ""  ADC
 SG_ RLR_DTC_VARIANT_SELECTION_NOT_DONE : 216|1@0+ (1,0) [0|1] ""  ADC
 SG_ RLR_DTC_RADAR_SIDE_MISMATCH : 217|1@0+ (1,0) [0|1] ""  ADC
 SG_ RLR_DTC_ALIGNMENT_NOT_DONE : 218|1@0+ (1,0) [0|1] ""  ADC
 SG_ RLR_DTC_PUBLIC_CAN_BUSOFF : 219|1@0+ (1,0) [0|1] ""  ADC
 SG_ RLR_DTC_LOST_COMM_EPS : 222|1@0+ (1,0) [0|1] ""  ADC
 SG_ RLR_DTC_INVALID_DATA_EPS : 223|1@0+ (1,0) [0|1] ""  ADC
 SG_ RLR_DTC_LOST_COMM_BCS : 224|1@0+ (1,0) [0|1] ""  ADC
 SG_ RLR_DTC_INVALID_DATA_BCS : 225|1@0+ (1,0) [0|1] ""  ADC
 SG_ RLR_DTC_LOST_COMM_SOC : 230|1@0+ (1,0) [0|1] ""  ADC
 SG_ RLR_DTC_INVALID_DATA_SOC : 231|1@0+ (1,0) [0|1] ""  ADC
 SG_ RLR_DTC_SOC_Time_SYNC_FAIL : 232|1@0+ (1,0) [0|1] ""  ADC

BO_ 616 ADC_SOC_Time: 64 ADC
 SG_ UMM_UsageModeSt : 26|3@0+ (1,0) [0|7] ""  RLR
 SG_ VMM_OTAModeSt : 167|2@0+ (1,0) [0|3] ""  RLR
 SG_ Time_Year : 343|8@0+ (1,2000) [2000|2255] "y"  RLR
 SG_ Time_Month : 351|4@0+ (1,0) [1|12] "m"  RLR
 SG_ Time_Day : 347|5@0+ (1,0) [1|31] "d"  RLR
 SG_ Time_Hour : 358|5@0+ (1,0) [0|23] "h"  RLR
 SG_ Time_Min : 353|6@0+ (1,0) [0|59] "min"  RLR
 SG_ Time_Sec : 363|6@0+ (1,0) [0|59] "s"  RLR

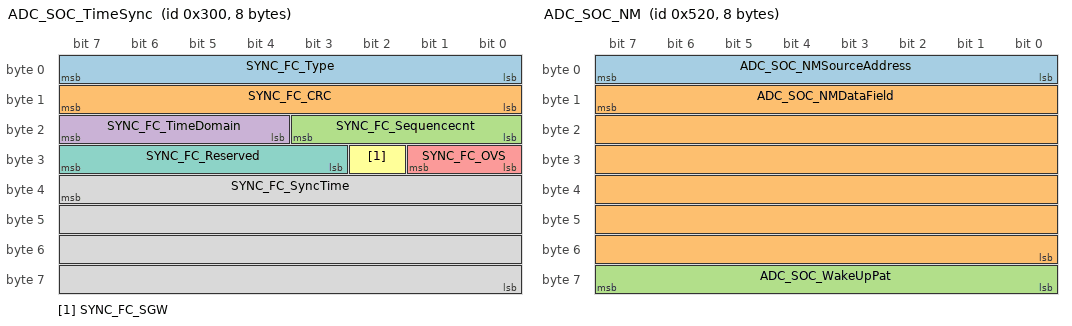
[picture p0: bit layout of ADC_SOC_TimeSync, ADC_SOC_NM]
BO_ 768 ADC_SOC_TimeSync: 8 ADC
 SG_ SYNC_FC_Type : 7|8@0+ (1,0) [0|255] ""  RLR
 SG_ SYNC_FC_CRC : 15|8@0+ (1,0) [0|255] ""  RLR
 SG_ SYNC_FC_Sequencecnt : 19|4@0+ (1,0) [0|15] ""  RLR
 SG_ SYNC_FC_TimeDomain : 23|4@0+ (1,0) [0|15] ""  RLR
 SG_ SYNC_FC_OVS : 25|2@0+ (1,0) [0|3] ""  RLR
 SG_ SYNC_FC_SGW : 26|1@0+ (1,0) [0|1] ""  RLR
 SG_ SYNC_FC_Reserved : 31|5@0+ (1,0) [0|31] ""  RLR
 SG_ SYNC_FC_SyncTime : 39|32@0+ (1,0) [0|4294967295] ""  RLR

BO_ 1234 RLR_DiagCode: 64 RLR
    SG_ RLR_DTCCode : 7|512@0+ (1,0) [0|0] "" ADC

BO_ 1312 ADC_SOC_NM: 8 ADC
 SG_ ADC_SOC_NMSourceAddress : 7|8@0+ (1,0) [0|255] ""  RLR
 SG_ ADC_SOC_NMDataField : 15|48@0+ (1,0) [0|65535] ""  RLR
 SG_ ADC_SOC_WakeUpPat : 63|8@0+ (1,0) [0|255] ""  RLR

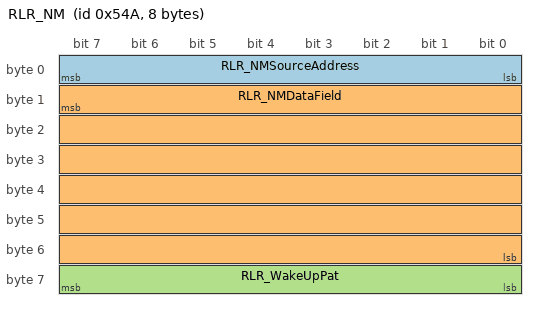
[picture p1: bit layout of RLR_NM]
BO_ 1354 RLR_NM: 8 RLR
 SG_ RLR_NMSourceAddress : 7|8@0+ (1,0) [0|255] ""  ADC
 SG_ RLR_NMDataField : 15|48@0+ (1,0) [0|65535] ""  ADC
 SG_ RLR_WakeUpPat : 63|8@0+ (1,0) [0|255] ""  ADC

BO_ 1866 RLR_Phys_Diag_Rx: 64 ADC
 SG_ RLR_Diag_Request : 7|512@0+ (1,0) [0|0] "" Vector__XXX

BO_ 1994 RLR_Diag_Tx: 64 RLR
 SG_ RLR_Diag_Response : 7|512@0+ (1,0) [0|0] "" ADC

BO_ 2015 Func_Diag_Rx: 64 ADC
 SG_ Func_Diag_Request : 7|512@0+ (1,0) [0|0] "" Vector__XXX

CM_ SG_ 530 SGU17_Msg_CheckSum "E2E Profile Variant 1A CRC";
CM_ SG_ 530 SGU17_Msg_AliveCounter "E2E Profile Variant 1A Counter";
CM_ SG_ 530 SGU17_BlockCounter "Block counter for every messages";
CM_ SG_ 530 SGU17_Object_ID "ID is an identifier number that allows for tracking of persistent objects over time";
CM_ SG_ 530 SGU17_Object_wExist "Existence probability of the object";
CM_ SG_ 530 SGU17_Object_Type "To indicate the estimated type of Object";
CM_ SG_ 530 SGU17_Object_Motion_Pattern "Motion type of object";
CM_ SG_ 530 SGU17_Object_wObstacle "The probability of an object being an obstacle";
CM_ SG_ 530 SGU17_Object_dx "Position of target object in x-direction [m]";
CM_ SG_ 530 SGU17_Object_dy "Position of target object in y-direction [m]";
CM_ SG_ 530 SGU17_Object_DistLong_rms "Standard deviation of longitudinal distance";
CM_ SG_ 530 SGU17_Obj_DistLat_rms "Standard deviation of lateral distance";
CM_ SG_ 530 SGU17_Object_vx "Relative target object velocity in x-direction [m/s]";
CM_ SG_ 530 SGU17_Object_vy "Relative target object velocity in y-direction [m/s]";
CM_ SG_ 530 SGU17_Obj_VrelLong_rms "Standard deviation of longitudinal relative velocity";
CM_ SG_ 530 SGU17_Obj_Vrelat_rms "Standard deviation of lateral relative velocity";
CM_ SG_ 530 SGU17_Object_ax "Relative target object acceleration in x-direction, in the vehicle coordinatesystem";
CM_ SG_ 530 SGU17_Object_ay "Relative target object acceleration in y-direction, in the vehicle coordinate system";
CM_ SG_ 530 SGU17_Object_DetStatus "Detection Staus Of Object";
CM_ SG_ 530 SGU17_LifeCycles_OBJ "-";
CM_ SG_ 530 SGU17_ObjRCS_17 "Radar Cross Section (RCS) estimation";
CM_ SG_ 530 SGU17_Object_dx_Rear "Position of target object in x-direction [m]";
CM_ SG_ 530 SGU17_Object_dy_Rear "Position of target object in y-direction [m]";
CM_ SG_ 531 SGU18_Msg_CheckSum "E2E Profile Variant 1A CRC";
CM_ SG_ 531 SGU18_Msg_AliveCounter "E2E Profile Variant 1A Counter";
CM_ SG_ 531 SGU18_BlockCounter "Block counter for every messages";
CM_ SG_ 531 SGU18_Object_ID "ID is an identifier number that allows for tracking of persistent objects over time";
CM_ SG_ 531 SGU18_Object_wExist "Existence probability of the object";
CM_ SG_ 531 SGU18_Object_Type "To indicate the estimated type of Object";
CM_ SG_ 531 SGU18_Object_Motion_Pattern "Motion type of object";
CM_ SG_ 531 SGU18_Object_wObstacle "The probability of an object being an obstacle";
CM_ SG_ 531 SGU18_Object_dx "Position of target object in x-direction [m]";
CM_ SG_ 531 SGU18_Object_dy "Position of target object in y-direction [m]";
CM_ SG_ 531 SGU18_Object_DistLong_rms "Standard deviation of longitudinal distance";
CM_ SG_ 531 SGU18_Obj_DistLat_rms "Standard deviation of lateral distance";
CM_ SG_ 531 SGU18_Object_vx "Relative target object velocity in x-direction [m/s]";
CM_ SG_ 531 SGU18_Object_vy "Relative target object velocity in y-direction [m/s]";
CM_ SG_ 531 SGU18_Obj_VrelLong_rms "Standard deviation of longitudinal relative velocity";
CM_ SG_ 531 SGU18_Obj_Vrelat_rms "Standard deviation of lateral relative velocity";
CM_ SG_ 531 SGU18_Object_ax "Relative target object acceleration in x-direction, in the vehicle coordinatesystem";
CM_ SG_ 531 SGU18_Object_ay "Relative target object acceleration in y-direction, in the vehicle coordinate system";
CM_ SG_ 531 SGU18_Object_DetStatus "Detection Staus Of Object";
CM_ SG_ 531 SGU18_LifeCycles_OBJ "-";
CM_ SG_ 531 SGU18_ObjRCS_18 "Radar Cross Section (RCS) estimation";
CM_ SG_ 531 SGU18_Object_dx_Rear "Position of target object in x-direction [m]";
CM_ SG_ 531 SGU18_Object_dy_Rear "Position of target object in y-direction [m]";
CM_ SG_ 532 SGU19_Msg_CheckSum "E2E Profile Variant 1A CRC";
CM_ SG_ 532 SGU19_Msg_AliveCounter "E2E Profile Variant 1A Counter";
CM_ SG_ 532 SGU19_BlockCounter "Block counter for every messages";
CM_ SG_ 532 SGU19_Object_ID "ID is an identifier number that allows for tracking of persistent objects over time";
CM_ SG_ 532 SGU19_Object_wExist "Existence probability of the object";
CM_ SG_ 532 SGU19_Object_Type "To indicate the estimated type of Object";
CM_ SG_ 532 SGU19_Object_Motion_Pattern "Motion type of object";
CM_ SG_ 532 SGU19_Object_wObstacle "The probability of an object being an obstacle";
CM_ SG_ 532 SGU19_Object_dx "Position of target object in x-direction [m]";
CM_ SG_ 532 SGU19_Object_dy "Position of target object in y-direction [m]";
CM_ SG_ 532 SGU19_Object_DistLong_rms "Standard deviation of longitudinal distance";
CM_ SG_ 532 SGU19_Obj_DistLat_rms "Standard deviation of lateral distance";
CM_ SG_ 532 SGU19_Object_vx "Relative target object velocity in x-direction [m/s]";
CM_ SG_ 532 SGU19_Object_vy "Relative target object velocity in y-direction [m/s]";
CM_ SG_ 532 SGU19_Obj_VrelLong_rms "Standard deviation of longitudinal relative velocity";
CM_ SG_ 532 SGU19_Obj_Vrelat_rms "Standard deviation of lateral relative velocity";
CM_ SG_ 532 SGU19_Object_ax "Relative target object acceleration in x-direction, in the vehicle coordinatesystem";
CM_ SG_ 532 SGU19_Object_ay "Relative target object acceleration in y-direction, in the vehicle coordinate system";
CM_ SG_ 532 SGU19_Object_DetStatus "Detection Staus Of Object";
CM_ SG_ 532 SGU19_LifeCycles_OBJ "-";
CM_ SG_ 532 SGU19_ObjRCS_19 "Radar Cross Section (RCS) estimation";
CM_ SG_ 532 SGU19_Object_dx_Rear "Position of target object in x-direction [m]";
CM_ SG_ 532 SGU19_Object_dy_Rear "Position of target object in y-direction [m]";
CM_ SG_ 533 SGU20_Msg_CheckSum "E2E Profile Variant 1A CRC";
CM_ SG_ 533 SGU20_Msg_AliveCounter "E2E Profile Variant 1A Counter";
CM_ SG_ 533 SGU20_BlockCounter "Block counter for every messages";
CM_ SG_ 533 SGU20_Object_ID "ID is an identifier number that allows for tracking of persistent objects over time";
CM_ SG_ 533 SGU20_Object_wExist "Existence probability of the object";
CM_ SG_ 533 SGU20_Object_Type "To indicate the estimated type of Object";
CM_ SG_ 533 SGU20_Object_Motion_Pattern "Motion type of object";
CM_ SG_ 533 SGU20_Object_wObstacle "The probability of an object being an obstacle";
CM_ SG_ 533 SGU20_Object_dx "Position of target object in x-direction [m]";
CM_ SG_ 533 SGU20_Object_dy "Position of target object in y-direction [m]";
CM_ SG_ 533 SGU20_Object_DistLong_rms "Standard deviation of longitudinal distance";
CM_ SG_ 533 SGU20_Obj_DistLat_rms "Standard deviation of lateral distance";
CM_ SG_ 533 SGU20_Object_vx "Relative target object velocity in x-direction [m/s]";
CM_ SG_ 533 SGU20_Object_vy "Relative target object velocity in y-direction [m/s]";
CM_ SG_ 533 SGU20_Obj_VrelLong_rms "Standard deviation of longitudinal relative velocity";
CM_ SG_ 533 SGU20_Obj_Vrelat_rms "Standard deviation of lateral relative velocity";
CM_ SG_ 533 SGU20_Object_ax "Relative target object acceleration in x-direction, in the vehicle coordinatesystem";
CM_ SG_ 533 SGU20_Object_ay "Relative target object acceleration in y-direction, in the vehicle coordinate system";
CM_ SG_ 533 SGU20_Object_DetStatus "Detection Staus Of Object";
CM_ SG_ 533 SGU20_LifeCycles_OBJ "-";
CM_ SG_ 533 SGU20_ObjRCS_20 "Radar Cross Section (RCS) estimation";
CM_ SG_ 533 SGU20_Object_dx_Rear "Position of target object in x-direction [m]";
CM_ SG_ 533 SGU20_Object_dy_Rear "Position of target object in y-direction [m]";
CM_ SG_ 534 SGU21_Msg_CheckSum "E2E Profile Variant 1A CRC";
CM_ SG_ 534 SGU21_Msg_AliveCounter "E2E Profile Variant 1A Counter";
CM_ SG_ 534 SGU21_BlockCounter "Block counter for every messages";
CM_ SG_ 534 SGU21_Object_ID "ID is an identifier number that allows for tracking of persistent objects over time";
CM_ SG_ 534 SGU21_Object_wExist "Existence probability of the object";
CM_ SG_ 534 SGU21_Object_Type "To indicate the estimated type of Object";
CM_ SG_ 534 SGU21_Object_Motion_Pattern "Motion type of object";
CM_ SG_ 534 SGU21_Object_wObstacle "The probability of an object being an obstacle";
CM_ SG_ 534 SGU21_Object_dx "Position of target object in x-direction [m]";
CM_ SG_ 534 SGU21_Object_dy "Position of target object in y-direction [m]";
CM_ SG_ 534 SGU21_Object_DistLong_rms "Standard deviation of longitudinal distance";
CM_ SG_ 534 SGU21_Obj_DistLat_rms "Standard deviation of lateral distance";
CM_ SG_ 534 SGU21_Object_vx "Relative target object velocity in x-direction [m/s]";
CM_ SG_ 534 SGU21_Object_vy "Relative target object velocity in y-direction [m/s]";
CM_ SG_ 534 SGU21_Obj_VrelLong_rms "Standard deviation of longitudinal relative velocity";
CM_ SG_ 534 SGU21_Obj_Vrelat_rms "Standard deviation of lateral relative velocity";
CM_ SG_ 534 SGU21_Object_ax "Relative target object acceleration in x-direction, in the vehicle coordinatesystem";
CM_ SG_ 534 SGU21_Object_ay "Relative target object acceleration in y-direction, in the vehicle coordinate system";
CM_ SG_ 534 SGU21_Object_DetStatus "Detection Staus Of Object";
CM_ SG_ 534 SGU21_LifeCycles_OBJ "-";
CM_ SG_ 534 SGU21_ObjRCS_21 "Radar Cross Section (RCS) estimation";
CM_ SG_ 534 SGU21_Object_dx_Rear "Position of target object in x-direction [m]";
CM_ SG_ 534 SGU21_Object_dy_Rear "Position of target object in y-direction [m]";
CM_ SG_ 535 SGU22_Msg_CheckSum "E2E Profile Variant 1A CRC";
CM_ SG_ 535 SGU22_Msg_AliveCounter "E2E Profile Variant 1A Counter";
CM_ SG_ 535 SGU22_BlockCounter "Block counter for every messages";
CM_ SG_ 535 SGU22_Object_ID "ID is an identifier number that allows for tracking of persistent objects over time";
CM_ SG_ 535 SGU22_Object_wExist "Existence probability of the object";
CM_ SG_ 535 SGU22_Object_Type "To indicate the estimated type of Object";
CM_ SG_ 535 SGU22_Object_Motion_Pattern "Motion type of object";
CM_ SG_ 535 SGU22_Object_wObstacle "The probability of an object being an obstacle";
CM_ SG_ 535 SGU22_Object_dx "Position of target object in x-direction [m]";
CM_ SG_ 535 SGU22_Object_dy "Position of target object in y-direction [m]";
CM_ SG_ 535 SGU22_Object_DistLong_rms "Standard deviation of longitudinal distance";
CM_ SG_ 535 SGU22_Obj_DistLat_rms "Standard deviation of lateral distance";
CM_ SG_ 535 SGU22_Object_vx "Relative target object velocity in x-direction [m/s]";
CM_ SG_ 535 SGU22_Object_vy "Relative target object velocity in y-direction [m/s]";
CM_ SG_ 535 SGU22_Obj_VrelLong_rms "Standard deviation of longitudinal relative velocity";
CM_ SG_ 535 SGU22_Obj_Vrelat_rms "Standard deviation of lateral relative velocity";
CM_ SG_ 535 SGU22_Object_ax "Relative target object acceleration in x-direction, in the vehicle coordinatesystem";
CM_ SG_ 535 SGU22_Object_ay "Relative target object acceleration in y-direction, in the vehicle coordinate system";
CM_ SG_ 535 SGU22_Object_DetStatus "Detection Staus Of Object";
CM_ SG_ 535 SGU22_LifeCycles_OBJ "-";
CM_ SG_ 535 SGU22_ObjRCS_22 "Radar Cross Section (RCS) estimation";
CM_ SG_ 535 SGU22_Object_dx_Rear "Position of target object in x-direction [m]";
CM_ SG_ 535 SGU22_Object_dy_Rear "Position of target object in y-direction [m]";
CM_ SG_ 536 SGU23_Msg_CheckSum "E2E Profile Variant 1A CRC";
CM_ SG_ 536 SGU23_Msg_AliveCounter "E2E Profile Variant 1A Counter";
CM_ SG_ 536 SGU23_BlockCounter "Block counter for every messages";
CM_ SG_ 536 SGU23_Object_ID "ID is an identifier number that allows for tracking of persistent objects over time";
CM_ SG_ 536 SGU23_Object_wExist "Existence probability of the object";
CM_ SG_ 536 SGU23_Object_Type "To indicate the estimated type of Object";
CM_ SG_ 536 SGU23_Object_Motion_Pattern "Motion type of object";
CM_ SG_ 536 SGU23_Object_wObstacle "The probability of an object being an obstacle";
CM_ SG_ 536 SGU23_Object_dx "Position of target object in x-direction [m]";
CM_ SG_ 536 SGU23_Object_dy "Position of target object in y-direction [m]";
CM_ SG_ 536 SGU23_Object_DistLong_rms "Standard deviation of longitudinal distance";
CM_ SG_ 536 SGU23_Obj_DistLat_rms "Standard deviation of lateral distance";
CM_ SG_ 536 SGU23_Object_vx "Relative target object velocity in x-direction [m/s]";
CM_ SG_ 536 SGU23_Object_vy "Relative target object velocity in y-direction [m/s]";
CM_ SG_ 536 SGU23_Obj_VrelLong_rms "Standard deviation of longitudinal relative velocity";
CM_ SG_ 536 SGU23_Obj_Vrelat_rms "Standard deviation of lateral relative velocity";
CM_ SG_ 536 SGU23_Object_ax "Relative target object acceleration in x-direction, in the vehicle coordinatesystem";
CM_ SG_ 536 SGU23_Object_ay "Relative target object acceleration in y-direction, in the vehicle coordinate system";
CM_ SG_ 536 SGU23_Object_DetStatus "Detection Staus Of Object";
CM_ SG_ 536 SGU23_LifeCycles_OBJ "-";
CM_ SG_ 536 SGU23_ObjRCS_23 "Radar Cross Section (RCS) estimation";
CM_ SG_ 536 SGU23_Object_dx_Rear "Position of target object in x-direction [m]";
CM_ SG_ 536 SGU23_Object_dy_Rear "Position of target object in y-direction [m]";
CM_ SG_ 537 SGU24_Msg_CheckSum "E2E Profile Variant 1A CRC";
CM_ SG_ 537 SGU24_Msg_AliveCounter "E2E Profile Variant 1A Counter";
CM_ SG_ 537 SGU24_BlockCounter "Block counter for every messages";
CM_ SG_ 537 SGU24_Object_ID "ID is an identifier number that allows for tracking of persistent objects over time";
CM_ SG_ 537 SGU24_Object_wExist "Existence probability of the object";
CM_ SG_ 537 SGU24_Object_Type "To indicate the estimated type of Object";
CM_ SG_ 537 SGU24_Object_Motion_Pattern "Motion type of object";
CM_ SG_ 537 SGU24_Object_wObstacle "The probability of an object being an obstacle";
CM_ SG_ 537 SGU24_Object_dx "Position of target object in x-direction [m]";
CM_ SG_ 537 SGU24_Object_dy "Position of target object in y-direction [m]";
CM_ SG_ 537 SGU24_Object_DistLong_rms "Standard deviation of longitudinal distance";
CM_ SG_ 537 SGU24_Obj_DistLat_rms "Standard deviation of lateral distance";
CM_ SG_ 537 SGU24_Object_vx "Relative target object velocity in x-direction [m/s]";
CM_ SG_ 537 SGU24_Object_vy "Relative target object velocity in y-direction [m/s]";
CM_ SG_ 537 SGU24_Obj_VrelLong_rms "Standard deviation of longitudinal relative velocity";
CM_ SG_ 537 SGU24_Obj_Vrelat_rms "Standard deviation of lateral relative velocity";
CM_ SG_ 537 SGU24_Object_ax "Relative target object acceleration in x-direction, in the vehicle coordinatesystem";
CM_ SG_ 537 SGU24_Object_ay "Relative target object acceleration in y-direction, in the vehicle coordinate system";
CM_ SG_ 537 SGU24_Object_DetStatus "Detection Staus Of Object";
CM_ SG_ 537 SGU24_LifeCycles_OBJ "-";
CM_ SG_ 537 SGU24_ObjRCS_24 "Radar Cross Section (RCS) estimation";
CM_ SG_ 537 SGU24_Object_dx_Rear "Position of target object in x-direction [m]";
CM_ SG_ 537 SGU24_Object_dy_Rear "Position of target object in y-direction [m]";
CM_ SG_ 538 SGU25_Msg_CheckSum "E2E Profile Variant 1A CRC";
CM_ SG_ 538 SGU25_Msg_AliveCounter "E2E Profile Variant 1A Counter";
CM_ SG_ 538 SGU25_BlockCounter "Block counter for every messages";
CM_ SG_ 538 SGU25_Object_ID "ID is an identifier number that allows for tracking of persistent objects over time";
CM_ SG_ 538 SGU25_Object_wExist "Existence probability of the object";
CM_ SG_ 538 SGU25_Object_Type "To indicate the estimated type of Object";
CM_ SG_ 538 SGU25_Object_Motion_Pattern "Motion type of object";
CM_ SG_ 538 SGU25_Object_wObstacle "The probability of an object being an obstacle";
CM_ SG_ 538 SGU25_Object_dx "Position of target object in x-direction [m]";
CM_ SG_ 538 SGU25_Object_dy "Position of target object in y-direction [m]";
CM_ SG_ 538 SGU25_Object_DistLong_rms "Standard deviation of longitudinal distance";
CM_ SG_ 538 SGU25_Obj_DistLat_rms "Standard deviation of lateral distance";
CM_ SG_ 538 SGU25_Object_vx "Relative target object velocity in x-direction [m/s]";
CM_ SG_ 538 SGU25_Object_vy "Relative target object velocity in y-direction [m/s]";
CM_ SG_ 538 SGU25_Obj_VrelLong_rms "Standard deviation of longitudinal relative velocity";
CM_ SG_ 538 SGU25_Obj_Vrelat_rms "Standard deviation of lateral relative velocity";
CM_ SG_ 538 SGU25_Object_ax "Relative target object acceleration in x-direction, in the vehicle coordinatesystem";
CM_ SG_ 538 SGU25_Object_ay "Relative target object acceleration in y-direction, in the vehicle coordinate system";
CM_ SG_ 538 SGU25_Object_DetStatus "Detection Staus Of Object";
CM_ SG_ 538 SGU25_LifeCycles_OBJ "-";
CM_ SG_ 538 SGU25_ObjRCS_25 "Radar Cross Section (RCS) estimation";
CM_ SG_ 538 SGU25_Object_dx_Rear "Position of target object in x-direction [m]";
CM_ SG_ 538 SGU25_Object_dy_Rear "Position of target object in y-direction [m]";
CM_ SG_ 539 SGU26_Msg_CheckSum "E2E Profile Variant 1A CRC";
CM_ SG_ 539 SGU26_Msg_AliveCounter "E2E Profile Variant 1A Counter";
CM_ SG_ 539 SGU26_BlockCounter "Block counter for every messages";
CM_ SG_ 539 SGU26_Object_ID "ID is an identifier number that allows for tracking of persistent objects over time";
CM_ SG_ 539 SGU26_Object_wExist "Existence probability of the object";
CM_ SG_ 539 SGU26_Object_Type "To indicate the estimated type of Object";
CM_ SG_ 539 SGU26_Object_Motion_Pattern "Motion type of object";
CM_ SG_ 539 SGU26_Object_wObstacle "The probability of an object being an obstacle";
CM_ SG_ 539 SGU26_Object_dx "Position of target object in x-direction [m]";
CM_ SG_ 539 SGU26_Object_dy "Position of target object in y-direction [m]";
CM_ SG_ 539 SGU26_Object_DistLong_rms "Standard deviation of longitudinal distance";
CM_ SG_ 539 SGU26_Obj_DistLat_rms "Standard deviation of lateral distance";
CM_ SG_ 539 SGU26_Object_vx "Relative target object velocity in x-direction [m/s]";
CM_ SG_ 539 SGU26_Object_vy "Relative target object velocity in y-direction [m/s]";
CM_ SG_ 539 SGU26_Obj_VrelLong_rms "Standard deviation of longitudinal relative velocity";
CM_ SG_ 539 SGU26_Obj_Vrelat_rms "Standard deviation of lateral relative velocity";
CM_ SG_ 539 SGU26_Object_ax "Relative target object acceleration in x-direction, in the vehicle coordinatesystem";
CM_ SG_ 539 SGU26_Object_ay "Relative target object acceleration in y-direction, in the vehicle coordinate system";
CM_ SG_ 539 SGU26_Object_DetStatus "Detection Staus Of Object";
CM_ SG_ 539 SGU26_LifeCycles_OBJ "-";
CM_ SG_ 539 SGU26_ObjRCS_26 "Radar Cross Section (RCS) estimation";
CM_ SG_ 539 SGU26_Object_dx_Rear "Position of target object in x-direction [m]";
CM_ SG_ 539 SGU26_Object_dy_Rear "Position of target object in y-direction [m]";
CM_ SG_ 540 SGU27_Msg_CheckSum "E2E Profile Variant 1A CRC";
CM_ SG_ 540 SGU27_Msg_AliveCounter "E2E Profile Variant 1A Counter";
CM_ SG_ 540 SGU27_BlockCounter "Block counter for every messages";
CM_ SG_ 540 SGU27_Object_ID "ID is an identifier number that allows for tracking of persistent objects over time";
CM_ SG_ 540 SGU27_Object_wExist "Existence probability of the object";
CM_ SG_ 540 SGU27_Object_Type "To indicate the estimated type of Object";
CM_ SG_ 540 SGU27_Object_Motion_Pattern "Motion type of object";
CM_ SG_ 540 SGU27_Object_wObstacle "The probability of an object being an obstacle";
CM_ SG_ 540 SGU27_Object_dx "Position of target object in x-direction [m]";
CM_ SG_ 540 SGU27_Object_dy "Position of target object in y-direction [m]";
CM_ SG_ 540 SGU27_Object_DistLong_rms "Standard deviation of longitudinal distance";
CM_ SG_ 540 SGU27_Obj_DistLat_rms "Standard deviation of lateral distance";
CM_ SG_ 540 SGU27_Object_vx "Relative target object velocity in x-direction [m/s]";
CM_ SG_ 540 SGU27_Object_vy "Relative target object velocity in y-direction [m/s]";
CM_ SG_ 540 SGU27_Obj_VrelLong_rms "Standard deviation of longitudinal relative velocity";
CM_ SG_ 540 SGU27_Obj_Vrelat_rms "Standard deviation of lateral relative velocity";
CM_ SG_ 540 SGU27_Object_ax "Relative target object acceleration in x-direction, in the vehicle coordinatesystem";
CM_ SG_ 540 SGU27_Object_ay "Relative target object acceleration in y-direction, in the vehicle coordinate system";
CM_ SG_ 540 SGU27_Object_DetStatus "Detection Staus Of Object";
CM_ SG_ 540 SGU27_LifeCycles_OBJ "-";
CM_ SG_ 540 SGU27_ObjRCS_27 "Radar Cross Section (RCS) estimation";
CM_ SG_ 540 SGU27_Object_dx_Rear "Position of target object in x-direction [m]";
CM_ SG_ 540 SGU27_Object_dy_Rear "Position of target object in y-direction [m]";
CM_ SG_ 541 SGU28_Msg_CheckSum "E2E Profile Variant 1A CRC";
CM_ SG_ 541 SGU28_Msg_AliveCounter "E2E Profile Variant 1A Counter";
CM_ SG_ 541 SGU28_BlockCounter "Block counter for every messages";
CM_ SG_ 541 SGU28_Object_ID "ID is an identifier number that allows for tracking of persistent objects over time";
CM_ SG_ 541 SGU28_Object_wExist "Existence probability of the object";
CM_ SG_ 541 SGU28_Object_Type "To indicate the estimated type of Object";
CM_ SG_ 541 SGU28_Object_Motion_Pattern "Motion type of object";
CM_ SG_ 541 SGU28_Object_wObstacle "The probability of an object being an obstacle";
CM_ SG_ 541 SGU28_Object_dx "Position of target object in x-direction [m]";
CM_ SG_ 541 SGU28_Object_dy "Position of target object in y-direction [m]";
CM_ SG_ 541 SGU28_Object_DistLong_rms "Standard deviation of longitudinal distance";
CM_ SG_ 541 SGU28_Obj_DistLat_rms "Standard deviation of lateral distance";
CM_ SG_ 541 SGU28_Object_vx "Relative target object velocity in x-direction [m/s]";
CM_ SG_ 541 SGU28_Object_vy "Relative target object velocity in y-direction [m/s]";
CM_ SG_ 541 SGU28_Obj_VrelLong_rms "Standard deviation of longitudinal relative velocity";
CM_ SG_ 541 SGU28_Obj_Vrelat_rms "Standard deviation of lateral relative velocity";
CM_ SG_ 541 SGU28_Object_ax "Relative target object acceleration in x-direction, in the vehicle coordinatesystem";
CM_ SG_ 541 SGU28_Object_ay "Relative target object acceleration in y-direction, in the vehicle coordinate system";
CM_ SG_ 541 SGU28_Object_DetStatus "Detection Staus Of Object";
CM_ SG_ 541 SGU28_LifeCycles_OBJ "-";
CM_ SG_ 541 SGU28_ObjRCS_28 "Radar Cross Section (RCS) estimation";
CM_ SG_ 541 SGU28_Object_dx_Rear "Position of target object in x-direction [m]";
CM_ SG_ 541 SGU28_Object_dy_Rear "Position of target object in y-direction [m]";
CM_ SG_ 542 SGU29_Msg_CheckSum "E2E Profile Variant 1A CRC";
CM_ SG_ 542 SGU29_Msg_AliveCounter "E2E Profile Variant 1A Counter";
CM_ SG_ 542 SGU29_BlockCounter "Block counter for every messages";
CM_ SG_ 542 SGU29_Object_ID "ID is an identifier number that allows for tracking of persistent objects over time";
CM_ SG_ 542 SGU29_Object_wExist "Existence probability of the object";
CM_ SG_ 542 SGU29_Object_Type "To indicate the estimated type of Object";
CM_ SG_ 542 SGU29_Object_Motion_Pattern "Motion type of object";
CM_ SG_ 542 SGU29_Object_wObstacle "The probability of an object being an obstacle";
CM_ SG_ 542 SGU29_Object_dx "Position of target object in x-direction [m]";
CM_ SG_ 542 SGU29_Object_dy "Position of target object in y-direction [m]";
CM_ SG_ 542 SGU29_Object_DistLong_rms "Standard deviation of longitudinal distance";
CM_ SG_ 542 SGU29_Obj_DistLat_rms "Standard deviation of lateral distance";
CM_ SG_ 542 SGU29_Object_vx "Relative target object velocity in x-direction [m/s]";
CM_ SG_ 542 SGU29_Object_vy "Relative target object velocity in y-direction [m/s]";
CM_ SG_ 542 SGU29_Obj_VrelLong_rms "Standard deviation of longitudinal relative velocity";
CM_ SG_ 542 SGU29_Obj_Vrelat_rms "Standard deviation of lateral relative velocity";
CM_ SG_ 542 SGU29_Object_ax "Relative target object acceleration in x-direction, in the vehicle coordinatesystem";
CM_ SG_ 542 SGU29_Object_ay "Relative target object acceleration in y-direction, in the vehicle coordinate system";
CM_ SG_ 542 SGU29_Object_DetStatus "Detection Staus Of Object";
CM_ SG_ 542 SGU29_LifeCycles_OBJ "-";
CM_ SG_ 542 SGU29_ObjRCS_29 "Radar Cross Section (RCS) estimation";
CM_ SG_ 542 SGU29_Object_dx_Rear "Position of target object in x-direction [m]";
CM_ SG_ 542 SGU29_Object_dy_Rear "Position of target object in y-direction [m]";
CM_ SG_ 543 SGU30_Msg_CheckSum "E2E Profile Variant 1A CRC";
CM_ SG_ 543 SGU30_Msg_AliveCounter "E2E Profile Variant 1A Counter";
CM_ SG_ 543 SGU30_BlockCounter "Block counter for every messages";
CM_ SG_ 543 SGU30_Object_ID "ID is an identifier number that allows for tracking of persistent objects over time";
CM_ SG_ 543 SGU30_Object_wExist "Existence probability of the object";
CM_ SG_ 543 SGU30_Object_Type "To indicate the estimated type of Object";
CM_ SG_ 543 SGU30_Object_Motion_Pattern "Motion type of object";
CM_ SG_ 543 SGU30_Object_wObstacle "The probability of an object being an obstacle";
CM_ SG_ 543 SGU30_Object_dx "Position of target object in x-direction [m]";
CM_ SG_ 543 SGU30_Object_dy "Position of target object in y-direction [m]";
CM_ SG_ 543 SGU30_Object_DistLong_rms "Standard deviation of longitudinal distance";
CM_ SG_ 543 SGU30_Obj_DistLat_rms "Standard deviation of lateral distance";
CM_ SG_ 543 SGU30_Object_vx "Relative target object velocity in x-direction [m/s]";
CM_ SG_ 543 SGU30_Object_vy "Relative target object velocity in y-direction [m/s]";
CM_ SG_ 543 SGU30_Obj_VrelLong_rms "Standard deviation of longitudinal relative velocity";
CM_ SG_ 543 SGU30_Obj_Vrelat_rms "Standard deviation of lateral relative velocity";
CM_ SG_ 543 SGU30_Object_ax "Relative target object acceleration in x-direction, in the vehicle coordinatesystem";
CM_ SG_ 543 SGU30_Object_ay "Relative target object acceleration in y-direction, in the vehicle coordinate system";
CM_ SG_ 543 SGU30_Object_DetStatus "Detection Staus Of Object";
CM_ SG_ 543 SGU30_LifeCycles_OBJ "-";
CM_ SG_ 543 SGU30_ObjRCS_30 "Radar Cross Section (RCS) estimation";
CM_ SG_ 543 SGU30_Object_dx_Rear "Position of target object in x-direction [m]";
CM_ SG_ 543 SGU30_Object_dy_Rear "Position of target object in y-direction [m]";
CM_ SG_ 544 SGU31_Msg_CheckSum "E2E Profile Variant 1A CRC";
CM_ SG_ 544 SGU31_Msg_AliveCounter "E2E Profile Variant 1A Counter";
CM_ SG_ 544 SGU31_BlockCounter "Block counter for every messages";
CM_ SG_ 544 SGU31_Object_ID "ID is an identifier number that allows for tracking of persistent objects over time";
CM_ SG_ 544 SGU31_Object_wExist "Existence probability of the object";
CM_ SG_ 544 SGU31_Object_Type "To indicate the estimated type of Object";
CM_ SG_ 544 SGU31_Object_Motion_Pattern "Motion type of object";
CM_ SG_ 544 SGU31_Object_wObstacle "The probability of an object being an obstacle";
CM_ SG_ 544 SGU31_Object_dx "Position of target object in x-direction [m]";
CM_ SG_ 544 SGU31_Object_dy "Position of target object in y-direction [m]";
CM_ SG_ 544 SGU31_Object_DistLong_rms "Standard deviation of longitudinal distance";
CM_ SG_ 544 SGU31_Obj_DistLat_rms "Standard deviation of lateral distance";
CM_ SG_ 544 SGU31_Object_vx "Relative target object velocity in x-direction [m/s]";
CM_ SG_ 544 SGU31_Object_vy "Relative target object velocity in y-direction [m/s]";
CM_ SG_ 544 SGU31_Obj_VrelLong_rms "Standard deviation of longitudinal relative velocity";
CM_ SG_ 544 SGU31_Obj_Vrelat_rms "Standard deviation of lateral relative velocity";
CM_ SG_ 544 SGU31_Object_ax "Relative target object acceleration in x-direction, in the vehicle coordinatesystem";
CM_ SG_ 544 SGU31_Object_ay "Relative target object acceleration in y-direction, in the vehicle coordinate system";
CM_ SG_ 544 SGU31_Object_DetStatus "Detection Staus Of Object";
CM_ SG_ 544 SGU31_LifeCycles_OBJ "-";
CM_ SG_ 544 SGU31_ObjRCS_31 "Radar Cross Section (RCS) estimation";
CM_ SG_ 544 SGU31_Object_dx_Rear "Position of target object in x-direction [m]";
CM_ SG_ 544 SGU31_Object_dy_Rear "Position of target object in y-direction [m]";
CM_ SG_ 545 SGU32_Msg_CheckSum "E2E Profile Variant 1A CRC";
CM_ SG_ 545 SGU32_Msg_AliveCounter "E2E Profile Variant 1A Counter";
CM_ SG_ 545 SGU32_BlockCounter "Block counter for every messages";
CM_ SG_ 545 SGU32_Object_ID "ID is an identifier number that allows for tracking of persistent objects over time";
CM_ SG_ 545 SGU32_Object_wExist "Existence probability of the object";
CM_ SG_ 545 SGU32_Object_Type "To indicate the estimated type of Object";
CM_ SG_ 545 SGU32_Object_Motion_Pattern "Motion type of object";
CM_ SG_ 545 SGU32_Object_wObstacle "The probability of an object being an obstacle";
CM_ SG_ 545 SGU32_Object_dx "Position of target object in x-direction [m]";
CM_ SG_ 545 SGU32_Object_dy "Position of target object in y-direction [m]";
CM_ SG_ 545 SGU32_Object_DistLong_rms "Standard deviation of longitudinal distance";
CM_ SG_ 545 SGU32_Obj_DistLat_rms "Standard deviation of lateral distance";
CM_ SG_ 545 SGU32_Object_vx "Relative target object velocity in x-direction [m/s]";
CM_ SG_ 545 SGU32_Object_vy "Relative target object velocity in y-direction [m/s]";
CM_ SG_ 545 SGU32_Obj_VrelLong_rms "Standard deviation of longitudinal relative velocity";
CM_ SG_ 545 SGU32_Obj_Vrelat_rms "Standard deviation of lateral relative velocity";
CM_ SG_ 545 SGU32_Object_ax "Relative target object acceleration in x-direction, in the vehicle coordinatesystem";
CM_ SG_ 545 SGU32_Object_ay "Relative target object acceleration in y-direction, in the vehicle coordinate system";
CM_ SG_ 545 SGU32_Object_DetStatus "Detection Staus Of Object";
CM_ SG_ 545 SGU32_LifeCycles_OBJ "-";
CM_ SG_ 545 SGU32_ObjRCS_32 "Radar Cross Section (RCS) estimation";
CM_ SG_ 545 SGU32_Object_dx_Rear "Position of target object in x-direction [m]";
CM_ SG_ 545 SGU32_Object_dy_Rear "Position of target object in y-direction [m]";
CM_ SG_ 546 RLR_RadarInfor_Checksum "E2E Profile Variant 1A CRC";
CM_ SG_ 546 RLR_RadarInfor_AliveCounter "E2E Profile Variant 1A Counter";
CM_ SG_ 546 mountAngleIndicator_az "mountAngleIndicator_az";
CM_ SG_ 546 mountAngleCurrent_az "mountAngleCurrent_az";
CM_ SG_ 546 mountAngleIndicator_el "mountAngleIndicator_el";
CM_ SG_ 546 mountAngleCurrent_el "mountAngleCurrent_el";
CM_ SG_ 546 malStablePosAz "malStablePosAz";
CM_ SG_ 546 malStablePosEl "malStablePosEl";
CM_ SG_ 546 AngleEMEIndicatorAz "AngleEMEIndicatorAz";
CM_ SG_ 546 AngleEMEIndicatorEl "AngleEMEIndicatorEl";
CM_ SG_ 546 FilteredPhiSpread "FilteredPhiSpread";
CM_ SG_ 546 highSpreadIndicator_el "highSpreadIndicator_el";
CM_ SG_ 546 highSpreadIndicator_az "highSpreadIndicator_az";
CM_ SG_ 546 elOutOfSpecCause "elOutOfSpecCause";
CM_ SG_ 546 azOutOfSpecCause "azOutOfSpecCause";
CM_ SG_ 546 Fault_MAL_HOR_ABS_EVENT "Fault_MAL_HOR_ABS_EVENT";
CM_ SG_ 546 Fault_MAL_HOR_REL_EVENT "Fault_MAL_HOR_REL_EVENT";
CM_ SG_ 546 Fault_MAL_VER_ABS_EVENT "Fault_MAL_VER_ABS_EVENT";
CM_ SG_ 546 Fault_MAL_VER_REL_EVENT "Fault_MAL_VER_REL_EVENT";
CM_ SG_ 546 azOutOfProfileCause "azOutOfProfileCause";
CM_ SG_ 546 elOutOfProfileCause "elOutOfProfileCause";
CM_ SG_ 546 RLR_SW_Baseline "Baseline of SWExample:BL09 V1.2,FR_SW_Baseline_Can03 = 9";
CM_ SG_ 546 RLR_SW_ReleaseType "ReleaseType of SWExample:BL09 V1.2,FR_SW_ReleaseType_Can03 = 0";
CM_ SG_ 546 RLR_SW_MajorVersion "Major Version of SWExample: V1.2, FR_SW_MajorVersion_Can03 = 1";
CM_ SG_ 546 RLR_SW_MinorVersion "Minor Version of SWExample:BL09 V1.2, FR_SW_MinorVersion_Can03 = 2";
CM_ SG_ 546 RLR_SDA_CalibrationSts "SDA Calibration Status";
CM_ SG_ 546 RLR_EOL_CalibrationSts "EOL Calibration Status";
CM_ SG_ 546 RLR_Blindness_FaultSts "Blindness Fault Status";
CM_ SG_ 546 RLR_ModulationSts "Modulation Status";
CM_ SG_ 546 RLR_Misalignment_FaultSts "Misalignment Fault Status";
CM_ SG_ 546 RLR_Radar_FaultSts "Radar Fault Status";
CM_ SG_ 546 RLR_DTC_VBAT_HIGH "DTC_VBAT_HIGH";
CM_ SG_ 546 RLR_DTC_VBAT_LOW "DTC_VBAT_LOW";
CM_ SG_ 546 RLR_DTC_HARDWARE_FAILURE "DTC_HARDWARE_FAILURE";
CM_ SG_ 546 RLR_DTC_RADAR_OVER_TEMPERATURE "DTC_RADAR_OVER_TEMPERATURE";
CM_ SG_ 546 RLR_DTC_CORNER_RADAR_BLIND "DTC_CORNER_RADAR_BLIND";
CM_ SG_ 546 RLR_DTC_CORNER_RADAR_MISALIGNED "DTC_CORNER_RADAR_MISALIGNED";
CM_ SG_ 546 RLR_DTC_DACORE_OOS "DTC_DACORE_OOS";
CM_ SG_ 546 RLR_DTC_DSP_FAILURE "DTC_DSP_FAILURE";
CM_ SG_ 546 RLR_DTC_VARIANT_SELECTION_NOT_DONE "DTC_VARIANT_SELECTION_NOT_DONE";
CM_ SG_ 546 RLR_DTC_RADAR_SIDE_MISMATCH "DTC_RADAR_SIDE_MISMATCH";
CM_ SG_ 546 RLR_DTC_ALIGNMENT_NOT_DONE "DTC_ALIGNMENT_NOT_DONE";
CM_ SG_ 546 RLR_DTC_PUBLIC_CAN_BUSOFF "DTC_PUBLIC_CAN_BUSOFF";
CM_ SG_ 546 RLR_DTC_LOST_COMM_EPS "DTC_LOST_COMM_EPS";
CM_ SG_ 546 RLR_DTC_INVALID_DATA_EPS "DTC_INVALID_DATA_EPS";
CM_ SG_ 546 RLR_DTC_LOST_COMM_BCS "DTC_LOST_COMM_BCS";
CM_ SG_ 546 RLR_DTC_INVALID_DATA_BCS "DTC_INVALID_DATA_BCS";
CM_ SG_ 546 RLR_DTC_LOST_COMM_SOC "DTC_LOST_COMM_SOC";
CM_ SG_ 546 RLR_DTC_INVALID_DATA_SOC "DTC_INVALID_DATA_SOC";
CM_ SG_ 546 RLR_DTC_SOC_Time_SYNC_FAIL "DTC_SOC_Time_SYNC_FAIL";
CM_ SG_ 1994 RLR_Diag_Response "RLR diagnostic response";
CM_ SG_ 1354 RLR_NMSourceAddress "NM source address ";
CM_ SG_ 1354 RLR_NMDataField "NM data field ";
CM_ SG_ 1354 RLR_WakeUpPat "Wake-up pattern wake-up ";
CM_ SG_ 768 SYNC_FC_Type "Type=0x20:TsyncType=0x28:Tsync FUP";
CM_ SG_ 768 SYNC_FC_CRC "CRC";
CM_ SG_ 768 SYNC_FC_Sequencecnt "Sequence counter";
CM_ SG_ 768 SYNC_FC_TimeDomain "Time Domain";
CM_ SG_ 768 SYNC_FC_OVS "In FUP PDUOVS=Overflow of seconds";
CM_ SG_ 768 SYNC_FC_SGW "In FUP PDUSyncToGTM=0SyncToSubDomain=1";
CM_ SG_ 768 SYNC_FC_Reserved "In FUP PDUReserved default=0";
CM_ SG_ 768 SYNC_FC_SyncTime "Tsync:SyncTimeSec=32bit LSB of the 48 bits seconds part timeTsync FUP:Sync TimeNSec=32 bit value in nanosconds";
CM_ SG_ 1312 ADC_SOC_NMSourceAddress "NM source address ";
CM_ SG_ 1312 ADC_SOC_NMDataField "NM data field ";
CM_ SG_ 1312 ADC_SOC_WakeUpPat "Wake-up pattern wake-up ";
CM_ SG_ 616 UMM_UsageModeSt "Usage mode state";
CM_ SG_ 616 VMM_OTAModeSt "OTA Mode state";
CM_ SG_ 616 Time_Year "Year number";
CM_ SG_ 616 Time_Month "Month number";
CM_ SG_ 616 Time_Day "Day number";
CM_ SG_ 616 Time_Hour "Hour number";
CM_ SG_ 616 Time_Min "Minute number";
CM_ SG_ 616 Time_Sec "Second number";
CM_ SG_ 2015 Func_Diag_Request "Diagnostic functional request";
CM_ SG_ 1866 RLR_Diag_Request "Diagnostic physical request";
BA_DEF_ BO_  "GenMsgCycleTime" INT 0 65535;
BA_DEF_ BO_  "GenMsgCycleTimeFast" INT 0 65535;
BA_DEF_ BO_  "GenMsgILSupport" ENUM  "No","Yes";
BA_DEF_ BO_  "GenMsgSendType" ENUM  "Cyclic","Event","CE","NotUsed","NotUsed","NotUsed","NotUsed","NotUsed","NoMsgSendType","IfActive","IfActiveWithRepetition","CyclicAndSpontanX";
BA_DEF_ BO_  "MsgType" ENUM  "Normal","NM","Diag","vector_leerstring";
BA_DEF_ BO_  "NmAsrMessage" ENUM  "No","Yes";
BA_DEF_ BO_  "VFrameFormat" ENUM  "StandardCAN","ExtendedCAN","reserved","reserved","reserved","reserved","reserved","reserved","reserved","reserved","reserved","reserved","reserved","reserved","StandardCAN_FD","ExtendedCAN_FD";
BA_DEF_ SG_  "GenSigInactiveValue" INT 0 2147483647;
BA_DEF_ SG_  "GenSigSendType" ENUM  "Cyclic","OnWrite","OnWriteWithRepetition","OnChange","OnChangeWithRepetition","IfActive","IfActiveWithRepetition","NoSigSendType","CyclicAndSpontanX","NotUsed","Event","CE";
BA_DEF_ SG_  "GenSigStartValue" INT 0 2147483647;
BA_DEF_ SG_  "Internal_type" ENUM  "*","UB","UW","UL","SB","SW","SL";
BA_DEF_ SG_  "IsCrcSignal" ENUM  "No","Yes";
BA_DEF_ SG_  "IsMonitor" ENUM  "*","Monitor";
BA_DEF_ SG_  "Remark" STRING ;
BA_DEF_ SG_  "SigInvalidSetFlag" ENUM  "*","Yes";
BA_DEF_ SG_  "UnitConversionFactor" FLOAT -100 100;
BA_DEF_ BO_  "CANFD_BRS" ENUM  "0","1";
BA_DEF_ SG_  "EventCommandSignal" ENUM  "No","Yes";
BA_DEF_ SG_  "GatewayedSignals" ENUM  "No","Yes";
BA_DEF_ SG_  "GenSigInvalidValue" HEX 0 0;
BA_DEF_ SG_  "GenSigTimeoutValue" HEX 0 0;
BA_DEF_DEF_  "GenMsgCycleTime" 0;
BA_DEF_DEF_  "GenMsgCycleTimeFast" 0;
BA_DEF_DEF_  "GenMsgILSupport" "Yes";
BA_DEF_DEF_  "GenMsgSendType" "Cyclic";
BA_DEF_DEF_  "GenSigInactiveValue" 0;
BA_DEF_DEF_  "GenSigSendType" "Cyclic";
BA_DEF_DEF_  "GenSigStartValue" 0;
BA_DEF_DEF_  "Internal_type" "*";
BA_DEF_DEF_  "IsCrcSignal" "No";
BA_DEF_DEF_  "IsMonitor" "*";
BA_DEF_DEF_  "MsgType" "";
BA_DEF_DEF_  "NmAsrMessage" "No";
BA_DEF_DEF_  "Remark" "";
BA_DEF_DEF_  "SigInvalidSetFlag" "*";
BA_DEF_DEF_  "UnitConversionFactor" 1;
BA_DEF_DEF_  "VFrameFormat" "StandardCAN";
BA_ "CANFD_BRS" BO_ 1312 1;
BA_ "CANFD_BRS" BO_ 1354 1;
BA_ "CANFD_BRS" BO_ 1866 1;
BA_ "CANFD_BRS" BO_ 1994 1;
BA_ "CANFD_BRS" BO_ 2015 1;
BA_ "CANFD_BRS" BO_ 530 1;
BA_ "CANFD_BRS" BO_ 531 1;
BA_ "CANFD_BRS" BO_ 532 1;
BA_ "CANFD_BRS" BO_ 533 1;
BA_ "CANFD_BRS" BO_ 534 1;
BA_ "CANFD_BRS" BO_ 535 1;
BA_ "CANFD_BRS" BO_ 536 1;
BA_ "CANFD_BRS" BO_ 537 1;
BA_ "CANFD_BRS" BO_ 538 1;
BA_ "CANFD_BRS" BO_ 539 1;
BA_ "CANFD_BRS" BO_ 540 1;
BA_ "CANFD_BRS" BO_ 541 1;
BA_ "CANFD_BRS" BO_ 542 1;
BA_ "CANFD_BRS" BO_ 543 1;
BA_ "CANFD_BRS" BO_ 544 1;
BA_ "CANFD_BRS" BO_ 545 1;
BA_ "CANFD_BRS" BO_ 546 1;
BA_ "CANFD_BRS" BO_ 616 1;
BA_ "CANFD_BRS" BO_ 768 1;
BA_ "GenMsgCycleTime" BO_ 1312 200;
BA_ "GenMsgCycleTime" BO_ 1354 200;
BA_ "GenMsgCycleTime" BO_ 546 50;
BA_ "GenMsgCycleTime" BO_ 616 20;
BA_ "GenMsgCycleTime" BO_ 768 500;
BA_ "GenMsgILSupport" BO_ 1234 0;
BA_ "GenMsgILSupport" BO_ 1354 0;
BA_ "GenMsgILSupport" BO_ 1866 0;
BA_ "GenMsgILSupport" BO_ 1994 0;
BA_ "GenMsgILSupport" BO_ 2015 0;
BA_ "GenMsgILSupport" BO_ 768 0;
BA_ "GenMsgSendType" BO_ 1234 8;
BA_ "GenMsgSendType" BO_ 1866 1;
BA_ "GenMsgSendType" BO_ 1994 1;
BA_ "GenMsgSendType" BO_ 2015 1;
BA_ "GenMsgSendType" BO_ 530 1;
BA_ "GenMsgSendType" BO_ 531 1;
BA_ "GenMsgSendType" BO_ 532 1;
BA_ "GenMsgSendType" BO_ 533 1;
BA_ "GenMsgSendType" BO_ 534 1;
BA_ "GenMsgSendType" BO_ 535 1;
BA_ "GenMsgSendType" BO_ 536 1;
BA_ "GenMsgSendType" BO_ 537 1;
BA_ "GenMsgSendType" BO_ 538 1;
BA_ "GenMsgSendType" BO_ 539 1;
BA_ "GenMsgSendType" BO_ 540 1;
BA_ "GenMsgSendType" BO_ 541 1;
BA_ "GenMsgSendType" BO_ 542 1;
BA_ "GenMsgSendType" BO_ 543 1;
BA_ "GenMsgSendType" BO_ 544 1;
BA_ "GenMsgSendType" BO_ 545 1;
BA_ "MsgType" BO_ 1234 0;
BA_ "MsgType" BO_ 1312 0;
BA_ "MsgType" BO_ 1354 0;
BA_ "MsgType" BO_ 1866 0;
BA_ "MsgType" BO_ 1994 0;
BA_ "MsgType" BO_ 2015 0;
BA_ "MsgType" BO_ 530 0;
BA_ "MsgType" BO_ 531 0;
BA_ "MsgType" BO_ 532 0;
BA_ "MsgType" BO_ 533 0;
BA_ "MsgType" BO_ 534 0;
BA_ "MsgType" BO_ 535 0;
BA_ "MsgType" BO_ 536 0;
BA_ "MsgType" BO_ 537 0;
BA_ "MsgType" BO_ 538 0;
BA_ "MsgType" BO_ 539 0;
BA_ "MsgType" BO_ 540 0;
BA_ "MsgType" BO_ 541 0;
BA_ "MsgType" BO_ 542 0;
BA_ "MsgType" BO_ 543 0;
BA_ "MsgType" BO_ 544 0;
BA_ "MsgType" BO_ 545 0;
BA_ "MsgType" BO_ 546 0;
BA_ "MsgType" BO_ 616 0;
BA_ "MsgType" BO_ 768 0;
BA_ "NmAsrMessage" BO_ 1312 1;
BA_ "NmAsrMessage" BO_ 1354 1;
BA_ "EventCommandSignal" SG_ 1312 ADC_SOC_NMDataField 0;
BA_ "GatewayedSignals" SG_ 1312 ADC_SOC_NMDataField 0;
BA_ "GenSigInvalidValue" SG_ 1312 ADC_SOC_NMDataField 0;
BA_ "GenSigSendType" SG_ 1312 ADC_SOC_NMDataField 1;
BA_ "GenSigTimeoutValue" SG_ 1312 ADC_SOC_NMDataField 0;
BA_ "EventCommandSignal" SG_ 1312 ADC_SOC_NMSourceAddress 0;
BA_ "GatewayedSignals" SG_ 1312 ADC_SOC_NMSourceAddress 0;
BA_ "GenSigInvalidValue" SG_ 1312 ADC_SOC_NMSourceAddress 0;
BA_ "GenSigSendType" SG_ 1312 ADC_SOC_NMSourceAddress 1;
BA_ "GenSigStartValue" SG_ 1312 ADC_SOC_NMSourceAddress 32;
BA_ "GenSigTimeoutValue" SG_ 1312 ADC_SOC_NMSourceAddress 0;
BA_ "EventCommandSignal" SG_ 1312 ADC_SOC_WakeUpPat 0;
BA_ "GatewayedSignals" SG_ 1312 ADC_SOC_WakeUpPat 0;
BA_ "GenSigInvalidValue" SG_ 1312 ADC_SOC_WakeUpPat 0;
BA_ "GenSigSendType" SG_ 1312 ADC_SOC_WakeUpPat 1;
BA_ "GenSigStartValue" SG_ 1312 ADC_SOC_WakeUpPat 76;
BA_ "GenSigTimeoutValue" SG_ 1312 ADC_SOC_WakeUpPat 0;
BA_ "EventCommandSignal" SG_ 1354 RLR_NMDataField 0;
BA_ "GatewayedSignals" SG_ 1354 RLR_NMDataField 0;
BA_ "GenSigInvalidValue" SG_ 1354 RLR_NMDataField 0;
BA_ "GenSigTimeoutValue" SG_ 1354 RLR_NMDataField 0;
BA_ "EventCommandSignal" SG_ 1354 RLR_NMSourceAddress 0;
BA_ "GatewayedSignals" SG_ 1354 RLR_NMSourceAddress 0;
BA_ "GenSigInvalidValue" SG_ 1354 RLR_NMSourceAddress 0;
BA_ "GenSigStartValue" SG_ 1354 RLR_NMSourceAddress 74;
BA_ "GenSigTimeoutValue" SG_ 1354 RLR_NMSourceAddress 0;
BA_ "EventCommandSignal" SG_ 1354 RLR_WakeUpPat 0;
BA_ "GatewayedSignals" SG_ 1354 RLR_WakeUpPat 0;
BA_ "GenSigInvalidValue" SG_ 1354 RLR_WakeUpPat 0;
BA_ "GenSigStartValue" SG_ 1354 RLR_WakeUpPat 76;
BA_ "GenSigTimeoutValue" SG_ 1354 RLR_WakeUpPat 0;
BA_ "EventCommandSignal" SG_ 1866 RLR_Diag_Request 0;
BA_ "GatewayedSignals" SG_ 1866 RLR_Diag_Request 0;
BA_ "GenSigInvalidValue" SG_ 1866 RLR_Diag_Request 0;
BA_ "GenSigSendType" SG_ 1866 RLR_Diag_Request 1;
BA_ "GenSigTimeoutValue" SG_ 1866 RLR_Diag_Request 0;
BA_ "EventCommandSignal" SG_ 1994 RLR_Diag_Response 0;
BA_ "GatewayedSignals" SG_ 1994 RLR_Diag_Response 0;
BA_ "GenSigInvalidValue" SG_ 1994 RLR_Diag_Response 0;
BA_ "GenSigSendType" SG_ 1994 RLR_Diag_Response 1;
BA_ "GenSigTimeoutValue" SG_ 1994 RLR_Diag_Response 0;
BA_ "EventCommandSignal" SG_ 2015 Func_Diag_Request 0;
BA_ "GatewayedSignals" SG_ 2015 Func_Diag_Request 0;
BA_ "GenSigInvalidValue" SG_ 2015 Func_Diag_Request 0;
BA_ "GenSigSendType" SG_ 2015 Func_Diag_Request 1;
BA_ "GenSigTimeoutValue" SG_ 2015 Func_Diag_Request 0;
BA_ "EventCommandSignal" SG_ 530 SGU17_BlockCounter 0;
BA_ "GatewayedSignals" SG_ 530 SGU17_BlockCounter 0;
BA_ "GenSigInvalidValue" SG_ 530 SGU17_BlockCounter 0;
BA_ "GenSigTimeoutValue" SG_ 530 SGU17_BlockCounter 0;
BA_ "EventCommandSignal" SG_ 530 SGU17_LifeCycles_OBJ 0;
BA_ "GatewayedSignals" SG_ 530 SGU17_LifeCycles_OBJ 0;
BA_ "GenSigInvalidValue" SG_ 530 SGU17_LifeCycles_OBJ 0;
BA_ "GenSigTimeoutValue" SG_ 530 SGU17_LifeCycles_OBJ 0;
BA_ "EventCommandSignal" SG_ 530 SGU17_Msg_AliveCounter 0;
BA_ "GatewayedSignals" SG_ 530 SGU17_Msg_AliveCounter 0;
BA_ "GenSigInvalidValue" SG_ 530 SGU17_Msg_AliveCounter 0;
BA_ "GenSigTimeoutValue" SG_ 530 SGU17_Msg_AliveCounter 0;
BA_ "EventCommandSignal" SG_ 530 SGU17_Msg_CheckSum 0;
BA_ "GatewayedSignals" SG_ 530 SGU17_Msg_CheckSum 0;
BA_ "GenSigInvalidValue" SG_ 530 SGU17_Msg_CheckSum 0;
BA_ "GenSigTimeoutValue" SG_ 530 SGU17_Msg_CheckSum 0;
BA_ "IsCrcSignal" SG_ 530 SGU17_Msg_CheckSum 1;
BA_ "EventCommandSignal" SG_ 530 SGU17_ObjRCS_17 0;
BA_ "GatewayedSignals" SG_ 530 SGU17_ObjRCS_17 0;
BA_ "GenSigInvalidValue" SG_ 530 SGU17_ObjRCS_17 0;
BA_ "GenSigTimeoutValue" SG_ 530 SGU17_ObjRCS_17 0;
BA_ "EventCommandSignal" SG_ 530 SGU17_Obj_DistLat_rms 0;
BA_ "GatewayedSignals" SG_ 530 SGU17_Obj_DistLat_rms 0;
BA_ "GenSigInvalidValue" SG_ 530 SGU17_Obj_DistLat_rms 0;
BA_ "GenSigTimeoutValue" SG_ 530 SGU17_Obj_DistLat_rms 0;
BA_ "EventCommandSignal" SG_ 530 SGU17_Obj_VrelLong_rms 0;
BA_ "GatewayedSignals" SG_ 530 SGU17_Obj_VrelLong_rms 0;
BA_ "GenSigInvalidValue" SG_ 530 SGU17_Obj_VrelLong_rms 0;
BA_ "GenSigTimeoutValue" SG_ 530 SGU17_Obj_VrelLong_rms 0;
BA_ "EventCommandSignal" SG_ 530 SGU17_Obj_Vrelat_rms 0;
BA_ "GatewayedSignals" SG_ 530 SGU17_Obj_Vrelat_rms 0;
BA_ "GenSigInvalidValue" SG_ 530 SGU17_Obj_Vrelat_rms 0;
BA_ "GenSigTimeoutValue" SG_ 530 SGU17_Obj_Vrelat_rms 0;
BA_ "EventCommandSignal" SG_ 530 SGU17_Object_DetStatus 0;
BA_ "GatewayedSignals" SG_ 530 SGU17_Object_DetStatus 0;
BA_ "GenSigInvalidValue" SG_ 530 SGU17_Object_DetStatus 0;
BA_ "GenSigTimeoutValue" SG_ 530 SGU17_Object_DetStatus 0;
BA_ "EventCommandSignal" SG_ 530 SGU17_Object_DistLong_rms 0;
BA_ "GatewayedSignals" SG_ 530 SGU17_Object_DistLong_rms 0;
BA_ "GenSigInvalidValue" SG_ 530 SGU17_Object_DistLong_rms 0;
BA_ "GenSigTimeoutValue" SG_ 530 SGU17_Object_DistLong_rms 0;
BA_ "EventCommandSignal" SG_ 530 SGU17_Object_ID 0;
BA_ "GatewayedSignals" SG_ 530 SGU17_Object_ID 0;
BA_ "GenSigInvalidValue" SG_ 530 SGU17_Object_ID 0;
BA_ "GenSigTimeoutValue" SG_ 530 SGU17_Object_ID 0;
BA_ "EventCommandSignal" SG_ 530 SGU17_Object_Motion_Pattern 0;
BA_ "GatewayedSignals" SG_ 530 SGU17_Object_Motion_Pattern 0;
BA_ "GenSigInvalidValue" SG_ 530 SGU17_Object_Motion_Pattern 0;
BA_ "GenSigTimeoutValue" SG_ 530 SGU17_Object_Motion_Pattern 0;
BA_ "EventCommandSignal" SG_ 530 SGU17_Object_Type 0;
BA_ "GatewayedSignals" SG_ 530 SGU17_Object_Type 0;
BA_ "GenSigInvalidValue" SG_ 530 SGU17_Object_Type 0;
BA_ "GenSigTimeoutValue" SG_ 530 SGU17_Object_Type 0;
BA_ "EventCommandSignal" SG_ 530 SGU17_Object_ax 0;
BA_ "GatewayedSignals" SG_ 530 SGU17_Object_ax 0;
BA_ "GenSigInvalidValue" SG_ 530 SGU17_Object_ax 0;
BA_ "GenSigTimeoutValue" SG_ 530 SGU17_Object_ax 0;
BA_ "EventCommandSignal" SG_ 530 SGU17_Object_ay 0;
BA_ "GatewayedSignals" SG_ 530 SGU17_Object_ay 0;
BA_ "GenSigInvalidValue" SG_ 530 SGU17_Object_ay 0;
BA_ "GenSigTimeoutValue" SG_ 530 SGU17_Object_ay 0;
BA_ "EventCommandSignal" SG_ 530 SGU17_Object_dx 0;
BA_ "GatewayedSignals" SG_ 530 SGU17_Object_dx 0;
BA_ "GenSigInvalidValue" SG_ 530 SGU17_Object_dx 0;
BA_ "GenSigTimeoutValue" SG_ 530 SGU17_Object_dx 0;
BA_ "EventCommandSignal" SG_ 530 SGU17_Object_dx_Rear 0;
BA_ "GatewayedSignals" SG_ 530 SGU17_Object_dx_Rear 0;
BA_ "GenSigInvalidValue" SG_ 530 SGU17_Object_dx_Rear 0;
BA_ "GenSigTimeoutValue" SG_ 530 SGU17_Object_dx_Rear 0;
BA_ "EventCommandSignal" SG_ 530 SGU17_Object_dy 0;
BA_ "GatewayedSignals" SG_ 530 SGU17_Object_dy 0;
BA_ "GenSigInvalidValue" SG_ 530 SGU17_Object_dy 0;
BA_ "GenSigTimeoutValue" SG_ 530 SGU17_Object_dy 0;
BA_ "EventCommandSignal" SG_ 530 SGU17_Object_dy_Rear 0;
BA_ "GatewayedSignals" SG_ 530 SGU17_Object_dy_Rear 0;
BA_ "GenSigInvalidValue" SG_ 530 SGU17_Object_dy_Rear 0;
BA_ "GenSigTimeoutValue" SG_ 530 SGU17_Object_dy_Rear 0;
BA_ "EventCommandSignal" SG_ 530 SGU17_Object_vx 0;
BA_ "GatewayedSignals" SG_ 530 SGU17_Object_vx 0;
BA_ "GenSigInvalidValue" SG_ 530 SGU17_Object_vx 0;
BA_ "GenSigTimeoutValue" SG_ 530 SGU17_Object_vx 0;
BA_ "EventCommandSignal" SG_ 530 SGU17_Object_vy 0;
BA_ "GatewayedSignals" SG_ 530 SGU17_Object_vy 0;
BA_ "GenSigInvalidValue" SG_ 530 SGU17_Object_vy 0;
BA_ "GenSigTimeoutValue" SG_ 530 SGU17_Object_vy 0;
BA_ "EventCommandSignal" SG_ 530 SGU17_Object_wExist 0;
BA_ "GatewayedSignals" SG_ 530 SGU17_Object_wExist 0;
BA_ "GenSigInvalidValue" SG_ 530 SGU17_Object_wExist 0;
BA_ "GenSigTimeoutValue" SG_ 530 SGU17_Object_wExist 0;
BA_ "EventCommandSignal" SG_ 530 SGU17_Object_wObstacle 0;
BA_ "GatewayedSignals" SG_ 530 SGU17_Object_wObstacle 0;
BA_ "GenSigInvalidValue" SG_ 530 SGU17_Object_wObstacle 0;
BA_ "GenSigTimeoutValue" SG_ 530 SGU17_Object_wObstacle 0;
BA_ "EventCommandSignal" SG_ 531 SGU18_BlockCounter 0;
BA_ "GatewayedSignals" SG_ 531 SGU18_BlockCounter 0;
BA_ "GenSigInvalidValue" SG_ 531 SGU18_BlockCounter 0;
BA_ "GenSigTimeoutValue" SG_ 531 SGU18_BlockCounter 0;
BA_ "EventCommandSignal" SG_ 531 SGU18_LifeCycles_OBJ 0;
BA_ "GatewayedSignals" SG_ 531 SGU18_LifeCycles_OBJ 0;
BA_ "GenSigInvalidValue" SG_ 531 SGU18_LifeCycles_OBJ 0;
BA_ "GenSigTimeoutValue" SG_ 531 SGU18_LifeCycles_OBJ 0;
BA_ "EventCommandSignal" SG_ 531 SGU18_Msg_AliveCounter 0;
BA_ "GatewayedSignals" SG_ 531 SGU18_Msg_AliveCounter 0;
BA_ "GenSigInvalidValue" SG_ 531 SGU18_Msg_AliveCounter 0;
BA_ "GenSigTimeoutValue" SG_ 531 SGU18_Msg_AliveCounter 0;
BA_ "EventCommandSignal" SG_ 531 SGU18_Msg_CheckSum 0;
BA_ "GatewayedSignals" SG_ 531 SGU18_Msg_CheckSum 0;
BA_ "GenSigInvalidValue" SG_ 531 SGU18_Msg_CheckSum 0;
BA_ "GenSigTimeoutValue" SG_ 531 SGU18_Msg_CheckSum 0;
BA_ "IsCrcSignal" SG_ 531 SGU18_Msg_CheckSum 1;
BA_ "EventCommandSignal" SG_ 531 SGU18_ObjRCS_18 0;
BA_ "GatewayedSignals" SG_ 531 SGU18_ObjRCS_18 0;
BA_ "GenSigInvalidValue" SG_ 531 SGU18_ObjRCS_18 0;
BA_ "GenSigTimeoutValue" SG_ 531 SGU18_ObjRCS_18 0;
BA_ "EventCommandSignal" SG_ 531 SGU18_Obj_DistLat_rms 0;
BA_ "GatewayedSignals" SG_ 531 SGU18_Obj_DistLat_rms 0;
BA_ "GenSigInvalidValue" SG_ 531 SGU18_Obj_DistLat_rms 0;
BA_ "GenSigTimeoutValue" SG_ 531 SGU18_Obj_DistLat_rms 0;
BA_ "EventCommandSignal" SG_ 531 SGU18_Obj_VrelLong_rms 0;
BA_ "GatewayedSignals" SG_ 531 SGU18_Obj_VrelLong_rms 0;
BA_ "GenSigInvalidValue" SG_ 531 SGU18_Obj_VrelLong_rms 0;
BA_ "GenSigTimeoutValue" SG_ 531 SGU18_Obj_VrelLong_rms 0;
BA_ "EventCommandSignal" SG_ 531 SGU18_Obj_Vrelat_rms 0;
BA_ "GatewayedSignals" SG_ 531 SGU18_Obj_Vrelat_rms 0;
BA_ "GenSigInvalidValue" SG_ 531 SGU18_Obj_Vrelat_rms 0;
BA_ "GenSigTimeoutValue" SG_ 531 SGU18_Obj_Vrelat_rms 0;
BA_ "EventCommandSignal" SG_ 531 SGU18_Object_DetStatus 0;
BA_ "GatewayedSignals" SG_ 531 SGU18_Object_DetStatus 0;
BA_ "GenSigInvalidValue" SG_ 531 SGU18_Object_DetStatus 0;
BA_ "GenSigTimeoutValue" SG_ 531 SGU18_Object_DetStatus 0;
BA_ "EventCommandSignal" SG_ 531 SGU18_Object_DistLong_rms 0;
BA_ "GatewayedSignals" SG_ 531 SGU18_Object_DistLong_rms 0;
BA_ "GenSigInvalidValue" SG_ 531 SGU18_Object_DistLong_rms 0;
BA_ "GenSigTimeoutValue" SG_ 531 SGU18_Object_DistLong_rms 0;
BA_ "EventCommandSignal" SG_ 531 SGU18_Object_ID 0;
BA_ "GatewayedSignals" SG_ 531 SGU18_Object_ID 0;
BA_ "GenSigInvalidValue" SG_ 531 SGU18_Object_ID 0;
BA_ "GenSigTimeoutValue" SG_ 531 SGU18_Object_ID 0;
BA_ "EventCommandSignal" SG_ 531 SGU18_Object_Motion_Pattern 0;
BA_ "GatewayedSignals" SG_ 531 SGU18_Object_Motion_Pattern 0;
BA_ "GenSigInvalidValue" SG_ 531 SGU18_Object_Motion_Pattern 0;
BA_ "GenSigTimeoutValue" SG_ 531 SGU18_Object_Motion_Pattern 0;
BA_ "EventCommandSignal" SG_ 531 SGU18_Object_Type 0;
BA_ "GatewayedSignals" SG_ 531 SGU18_Object_Type 0;
BA_ "GenSigInvalidValue" SG_ 531 SGU18_Object_Type 0;
BA_ "GenSigTimeoutValue" SG_ 531 SGU18_Object_Type 0;
BA_ "EventCommandSignal" SG_ 531 SGU18_Object_ax 0;
BA_ "GatewayedSignals" SG_ 531 SGU18_Object_ax 0;
BA_ "GenSigInvalidValue" SG_ 531 SGU18_Object_ax 0;
BA_ "GenSigTimeoutValue" SG_ 531 SGU18_Object_ax 0;
BA_ "EventCommandSignal" SG_ 531 SGU18_Object_ay 0;
BA_ "GatewayedSignals" SG_ 531 SGU18_Object_ay 0;
BA_ "GenSigInvalidValue" SG_ 531 SGU18_Object_ay 0;
BA_ "GenSigTimeoutValue" SG_ 531 SGU18_Object_ay 0;
BA_ "EventCommandSignal" SG_ 531 SGU18_Object_dx 0;
BA_ "GatewayedSignals" SG_ 531 SGU18_Object_dx 0;
BA_ "GenSigInvalidValue" SG_ 531 SGU18_Object_dx 0;
BA_ "GenSigTimeoutValue" SG_ 531 SGU18_Object_dx 0;
BA_ "EventCommandSignal" SG_ 531 SGU18_Object_dx_Rear 0;
BA_ "GatewayedSignals" SG_ 531 SGU18_Object_dx_Rear 0;
BA_ "GenSigInvalidValue" SG_ 531 SGU18_Object_dx_Rear 0;
BA_ "GenSigTimeoutValue" SG_ 531 SGU18_Object_dx_Rear 0;
BA_ "EventCommandSignal" SG_ 531 SGU18_Object_dy 0;
BA_ "GatewayedSignals" SG_ 531 SGU18_Object_dy 0;
BA_ "GenSigInvalidValue" SG_ 531 SGU18_Object_dy 0;
BA_ "GenSigTimeoutValue" SG_ 531 SGU18_Object_dy 0;
BA_ "EventCommandSignal" SG_ 531 SGU18_Object_dy_Rear 0;
BA_ "GatewayedSignals" SG_ 531 SGU18_Object_dy_Rear 0;
BA_ "GenSigInvalidValue" SG_ 531 SGU18_Object_dy_Rear 0;
BA_ "GenSigTimeoutValue" SG_ 531 SGU18_Object_dy_Rear 0;
BA_ "EventCommandSignal" SG_ 531 SGU18_Object_vx 0;
BA_ "GatewayedSignals" SG_ 531 SGU18_Object_vx 0;
BA_ "GenSigInvalidValue" SG_ 531 SGU18_Object_vx 0;
BA_ "GenSigTimeoutValue" SG_ 531 SGU18_Object_vx 0;
BA_ "EventCommandSignal" SG_ 531 SGU18_Object_vy 0;
BA_ "GatewayedSignals" SG_ 531 SGU18_Object_vy 0;
BA_ "GenSigInvalidValue" SG_ 531 SGU18_Object_vy 0;
BA_ "GenSigTimeoutValue" SG_ 531 SGU18_Object_vy 0;
BA_ "EventCommandSignal" SG_ 531 SGU18_Object_wExist 0;
BA_ "GatewayedSignals" SG_ 531 SGU18_Object_wExist 0;
BA_ "GenSigInvalidValue" SG_ 531 SGU18_Object_wExist 0;
BA_ "GenSigTimeoutValue" SG_ 531 SGU18_Object_wExist 0;
BA_ "EventCommandSignal" SG_ 531 SGU18_Object_wObstacle 0;
BA_ "GatewayedSignals" SG_ 531 SGU18_Object_wObstacle 0;
BA_ "GenSigInvalidValue" SG_ 531 SGU18_Object_wObstacle 0;
BA_ "GenSigTimeoutValue" SG_ 531 SGU18_Object_wObstacle 0;
BA_ "EventCommandSignal" SG_ 532 SGU19_BlockCounter 0;
BA_ "GatewayedSignals" SG_ 532 SGU19_BlockCounter 0;
BA_ "GenSigInvalidValue" SG_ 532 SGU19_BlockCounter 0;
BA_ "GenSigTimeoutValue" SG_ 532 SGU19_BlockCounter 0;
BA_ "EventCommandSignal" SG_ 532 SGU19_LifeCycles_OBJ 0;
BA_ "GatewayedSignals" SG_ 532 SGU19_LifeCycles_OBJ 0;
BA_ "GenSigInvalidValue" SG_ 532 SGU19_LifeCycles_OBJ 0;
BA_ "GenSigTimeoutValue" SG_ 532 SGU19_LifeCycles_OBJ 0;
BA_ "EventCommandSignal" SG_ 532 SGU19_Msg_AliveCounter 0;
BA_ "GatewayedSignals" SG_ 532 SGU19_Msg_AliveCounter 0;
BA_ "GenSigInvalidValue" SG_ 532 SGU19_Msg_AliveCounter 0;
BA_ "GenSigTimeoutValue" SG_ 532 SGU19_Msg_AliveCounter 0;
BA_ "EventCommandSignal" SG_ 532 SGU19_Msg_CheckSum 0;
BA_ "GatewayedSignals" SG_ 532 SGU19_Msg_CheckSum 0;
BA_ "GenSigInvalidValue" SG_ 532 SGU19_Msg_CheckSum 0;
BA_ "GenSigTimeoutValue" SG_ 532 SGU19_Msg_CheckSum 0;
BA_ "IsCrcSignal" SG_ 532 SGU19_Msg_CheckSum 1;
BA_ "EventCommandSignal" SG_ 532 SGU19_ObjRCS_19 0;
BA_ "GatewayedSignals" SG_ 532 SGU19_ObjRCS_19 0;
BA_ "GenSigInvalidValue" SG_ 532 SGU19_ObjRCS_19 0;
BA_ "GenSigTimeoutValue" SG_ 532 SGU19_ObjRCS_19 0;
BA_ "EventCommandSignal" SG_ 532 SGU19_Obj_DistLat_rms 0;
BA_ "GatewayedSignals" SG_ 532 SGU19_Obj_DistLat_rms 0;
BA_ "GenSigInvalidValue" SG_ 532 SGU19_Obj_DistLat_rms 0;
BA_ "GenSigTimeoutValue" SG_ 532 SGU19_Obj_DistLat_rms 0;
BA_ "EventCommandSignal" SG_ 532 SGU19_Obj_VrelLong_rms 0;
BA_ "GatewayedSignals" SG_ 532 SGU19_Obj_VrelLong_rms 0;
BA_ "GenSigInvalidValue" SG_ 532 SGU19_Obj_VrelLong_rms 0;
BA_ "GenSigTimeoutValue" SG_ 532 SGU19_Obj_VrelLong_rms 0;
BA_ "EventCommandSignal" SG_ 532 SGU19_Obj_Vrelat_rms 0;
BA_ "GatewayedSignals" SG_ 532 SGU19_Obj_Vrelat_rms 0;
BA_ "GenSigInvalidValue" SG_ 532 SGU19_Obj_Vrelat_rms 0;
BA_ "GenSigTimeoutValue" SG_ 532 SGU19_Obj_Vrelat_rms 0;
BA_ "EventCommandSignal" SG_ 532 SGU19_Object_DetStatus 0;
BA_ "GatewayedSignals" SG_ 532 SGU19_Object_DetStatus 0;
BA_ "GenSigInvalidValue" SG_ 532 SGU19_Object_DetStatus 0;
BA_ "GenSigTimeoutValue" SG_ 532 SGU19_Object_DetStatus 0;
BA_ "EventCommandSignal" SG_ 532 SGU19_Object_DistLong_rms 0;
BA_ "GatewayedSignals" SG_ 532 SGU19_Object_DistLong_rms 0;
BA_ "GenSigInvalidValue" SG_ 532 SGU19_Object_DistLong_rms 0;
BA_ "GenSigTimeoutValue" SG_ 532 SGU19_Object_DistLong_rms 0;
BA_ "EventCommandSignal" SG_ 532 SGU19_Object_ID 0;
BA_ "GatewayedSignals" SG_ 532 SGU19_Object_ID 0;
BA_ "GenSigInvalidValue" SG_ 532 SGU19_Object_ID 0;
BA_ "GenSigTimeoutValue" SG_ 532 SGU19_Object_ID 0;
BA_ "EventCommandSignal" SG_ 532 SGU19_Object_Motion_Pattern 0;
BA_ "GatewayedSignals" SG_ 532 SGU19_Object_Motion_Pattern 0;
BA_ "GenSigInvalidValue" SG_ 532 SGU19_Object_Motion_Pattern 0;
BA_ "GenSigTimeoutValue" SG_ 532 SGU19_Object_Motion_Pattern 0;
BA_ "EventCommandSignal" SG_ 532 SGU19_Object_Type 0;
BA_ "GatewayedSignals" SG_ 532 SGU19_Object_Type 0;
BA_ "GenSigInvalidValue" SG_ 532 SGU19_Object_Type 0;
BA_ "GenSigTimeoutValue" SG_ 532 SGU19_Object_Type 0;
BA_ "EventCommandSignal" SG_ 532 SGU19_Object_ax 0;
BA_ "GatewayedSignals" SG_ 532 SGU19_Object_ax 0;
BA_ "GenSigInvalidValue" SG_ 532 SGU19_Object_ax 0;
BA_ "GenSigTimeoutValue" SG_ 532 SGU19_Object_ax 0;
BA_ "EventCommandSignal" SG_ 532 SGU19_Object_ay 0;
BA_ "GatewayedSignals" SG_ 532 SGU19_Object_ay 0;
BA_ "GenSigInvalidValue" SG_ 532 SGU19_Object_ay 0;
BA_ "GenSigTimeoutValue" SG_ 532 SGU19_Object_ay 0;
BA_ "EventCommandSignal" SG_ 532 SGU19_Object_dx 0;
BA_ "GatewayedSignals" SG_ 532 SGU19_Object_dx 0;
BA_ "GenSigInvalidValue" SG_ 532 SGU19_Object_dx 0;
BA_ "GenSigTimeoutValue" SG_ 532 SGU19_Object_dx 0;
BA_ "EventCommandSignal" SG_ 532 SGU19_Object_dx_Rear 0;
BA_ "GatewayedSignals" SG_ 532 SGU19_Object_dx_Rear 0;
BA_ "GenSigInvalidValue" SG_ 532 SGU19_Object_dx_Rear 0;
BA_ "GenSigTimeoutValue" SG_ 532 SGU19_Object_dx_Rear 0;
BA_ "EventCommandSignal" SG_ 532 SGU19_Object_dy 0;
BA_ "GatewayedSignals" SG_ 532 SGU19_Object_dy 0;
BA_ "GenSigInvalidValue" SG_ 532 SGU19_Object_dy 0;
BA_ "GenSigTimeoutValue" SG_ 532 SGU19_Object_dy 0;
BA_ "EventCommandSignal" SG_ 532 SGU19_Object_dy_Rear 0;
BA_ "GatewayedSignals" SG_ 532 SGU19_Object_dy_Rear 0;
BA_ "GenSigInvalidValue" SG_ 532 SGU19_Object_dy_Rear 0;
BA_ "GenSigTimeoutValue" SG_ 532 SGU19_Object_dy_Rear 0;
BA_ "EventCommandSignal" SG_ 532 SGU19_Object_vx 0;
BA_ "GatewayedSignals" SG_ 532 SGU19_Object_vx 0;
BA_ "GenSigInvalidValue" SG_ 532 SGU19_Object_vx 0;
BA_ "GenSigTimeoutValue" SG_ 532 SGU19_Object_vx 0;
BA_ "EventCommandSignal" SG_ 532 SGU19_Object_vy 0;
BA_ "GatewayedSignals" SG_ 532 SGU19_Object_vy 0;
BA_ "GenSigInvalidValue" SG_ 532 SGU19_Object_vy 0;
BA_ "GenSigTimeoutValue" SG_ 532 SGU19_Object_vy 0;
BA_ "EventCommandSignal" SG_ 532 SGU19_Object_wExist 0;
BA_ "GatewayedSignals" SG_ 532 SGU19_Object_wExist 0;
BA_ "GenSigInvalidValue" SG_ 532 SGU19_Object_wExist 0;
BA_ "GenSigTimeoutValue" SG_ 532 SGU19_Object_wExist 0;
BA_ "EventCommandSignal" SG_ 532 SGU19_Object_wObstacle 0;
BA_ "GatewayedSignals" SG_ 532 SGU19_Object_wObstacle 0;
BA_ "GenSigInvalidValue" SG_ 532 SGU19_Object_wObstacle 0;
BA_ "GenSigTimeoutValue" SG_ 532 SGU19_Object_wObstacle 0;
BA_ "EventCommandSignal" SG_ 533 SGU20_BlockCounter 0;
BA_ "GatewayedSignals" SG_ 533 SGU20_BlockCounter 0;
BA_ "GenSigInvalidValue" SG_ 533 SGU20_BlockCounter 0;
BA_ "GenSigTimeoutValue" SG_ 533 SGU20_BlockCounter 0;
BA_ "EventCommandSignal" SG_ 533 SGU20_LifeCycles_OBJ 0;
BA_ "GatewayedSignals" SG_ 533 SGU20_LifeCycles_OBJ 0;
BA_ "GenSigInvalidValue" SG_ 533 SGU20_LifeCycles_OBJ 0;
BA_ "GenSigTimeoutValue" SG_ 533 SGU20_LifeCycles_OBJ 0;
BA_ "EventCommandSignal" SG_ 533 SGU20_Msg_AliveCounter 0;
BA_ "GatewayedSignals" SG_ 533 SGU20_Msg_AliveCounter 0;
BA_ "GenSigInvalidValue" SG_ 533 SGU20_Msg_AliveCounter 0;
BA_ "GenSigTimeoutValue" SG_ 533 SGU20_Msg_AliveCounter 0;
BA_ "EventCommandSignal" SG_ 533 SGU20_Msg_CheckSum 0;
BA_ "GatewayedSignals" SG_ 533 SGU20_Msg_CheckSum 0;
BA_ "GenSigInvalidValue" SG_ 533 SGU20_Msg_CheckSum 0;
BA_ "GenSigTimeoutValue" SG_ 533 SGU20_Msg_CheckSum 0;
BA_ "IsCrcSignal" SG_ 533 SGU20_Msg_CheckSum 1;
BA_ "EventCommandSignal" SG_ 533 SGU20_ObjRCS_20 0;
BA_ "GatewayedSignals" SG_ 533 SGU20_ObjRCS_20 0;
BA_ "GenSigInvalidValue" SG_ 533 SGU20_ObjRCS_20 0;
BA_ "GenSigTimeoutValue" SG_ 533 SGU20_ObjRCS_20 0;
BA_ "EventCommandSignal" SG_ 533 SGU20_Obj_DistLat_rms 0;
BA_ "GatewayedSignals" SG_ 533 SGU20_Obj_DistLat_rms 0;
BA_ "GenSigInvalidValue" SG_ 533 SGU20_Obj_DistLat_rms 0;
BA_ "GenSigTimeoutValue" SG_ 533 SGU20_Obj_DistLat_rms 0;
BA_ "EventCommandSignal" SG_ 533 SGU20_Obj_VrelLong_rms 0;
BA_ "GatewayedSignals" SG_ 533 SGU20_Obj_VrelLong_rms 0;
BA_ "GenSigInvalidValue" SG_ 533 SGU20_Obj_VrelLong_rms 0;
BA_ "GenSigTimeoutValue" SG_ 533 SGU20_Obj_VrelLong_rms 0;
BA_ "EventCommandSignal" SG_ 533 SGU20_Obj_Vrelat_rms 0;
BA_ "GatewayedSignals" SG_ 533 SGU20_Obj_Vrelat_rms 0;
BA_ "GenSigInvalidValue" SG_ 533 SGU20_Obj_Vrelat_rms 0;
BA_ "GenSigTimeoutValue" SG_ 533 SGU20_Obj_Vrelat_rms 0;
BA_ "EventCommandSignal" SG_ 533 SGU20_Object_DetStatus 0;
BA_ "GatewayedSignals" SG_ 533 SGU20_Object_DetStatus 0;
BA_ "GenSigInvalidValue" SG_ 533 SGU20_Object_DetStatus 0;
BA_ "GenSigTimeoutValue" SG_ 533 SGU20_Object_DetStatus 0;
BA_ "EventCommandSignal" SG_ 533 SGU20_Object_DistLong_rms 0;
BA_ "GatewayedSignals" SG_ 533 SGU20_Object_DistLong_rms 0;
BA_ "GenSigInvalidValue" SG_ 533 SGU20_Object_DistLong_rms 0;
BA_ "GenSigTimeoutValue" SG_ 533 SGU20_Object_DistLong_rms 0;
BA_ "EventCommandSignal" SG_ 533 SGU20_Object_ID 0;
BA_ "GatewayedSignals" SG_ 533 SGU20_Object_ID 0;
BA_ "GenSigInvalidValue" SG_ 533 SGU20_Object_ID 0;
BA_ "GenSigTimeoutValue" SG_ 533 SGU20_Object_ID 0;
BA_ "EventCommandSignal" SG_ 533 SGU20_Object_Motion_Pattern 0;
BA_ "GatewayedSignals" SG_ 533 SGU20_Object_Motion_Pattern 0;
BA_ "GenSigInvalidValue" SG_ 533 SGU20_Object_Motion_Pattern 0;
BA_ "GenSigTimeoutValue" SG_ 533 SGU20_Object_Motion_Pattern 0;
BA_ "EventCommandSignal" SG_ 533 SGU20_Object_Type 0;
BA_ "GatewayedSignals" SG_ 533 SGU20_Object_Type 0;
BA_ "GenSigInvalidValue" SG_ 533 SGU20_Object_Type 0;
BA_ "GenSigTimeoutValue" SG_ 533 SGU20_Object_Type 0;
BA_ "EventCommandSignal" SG_ 533 SGU20_Object_ax 0;
BA_ "GatewayedSignals" SG_ 533 SGU20_Object_ax 0;
BA_ "GenSigInvalidValue" SG_ 533 SGU20_Object_ax 0;
BA_ "GenSigTimeoutValue" SG_ 533 SGU20_Object_ax 0;
BA_ "EventCommandSignal" SG_ 533 SGU20_Object_ay 0;
BA_ "GatewayedSignals" SG_ 533 SGU20_Object_ay 0;
BA_ "GenSigInvalidValue" SG_ 533 SGU20_Object_ay 0;
BA_ "GenSigTimeoutValue" SG_ 533 SGU20_Object_ay 0;
BA_ "EventCommandSignal" SG_ 533 SGU20_Object_dx 0;
BA_ "GatewayedSignals" SG_ 533 SGU20_Object_dx 0;
BA_ "GenSigInvalidValue" SG_ 533 SGU20_Object_dx 0;
BA_ "GenSigTimeoutValue" SG_ 533 SGU20_Object_dx 0;
BA_ "EventCommandSignal" SG_ 533 SGU20_Object_dx_Rear 0;
BA_ "GatewayedSignals" SG_ 533 SGU20_Object_dx_Rear 0;
BA_ "GenSigInvalidValue" SG_ 533 SGU20_Object_dx_Rear 0;
BA_ "GenSigTimeoutValue" SG_ 533 SGU20_Object_dx_Rear 0;
BA_ "EventCommandSignal" SG_ 533 SGU20_Object_dy 0;
BA_ "GatewayedSignals" SG_ 533 SGU20_Object_dy 0;
BA_ "GenSigInvalidValue" SG_ 533 SGU20_Object_dy 0;
BA_ "GenSigTimeoutValue" SG_ 533 SGU20_Object_dy 0;
BA_ "EventCommandSignal" SG_ 533 SGU20_Object_dy_Rear 0;
BA_ "GatewayedSignals" SG_ 533 SGU20_Object_dy_Rear 0;
BA_ "GenSigInvalidValue" SG_ 533 SGU20_Object_dy_Rear 0;
BA_ "GenSigTimeoutValue" SG_ 533 SGU20_Object_dy_Rear 0;
BA_ "EventCommandSignal" SG_ 533 SGU20_Object_vx 0;
BA_ "GatewayedSignals" SG_ 533 SGU20_Object_vx 0;
BA_ "GenSigInvalidValue" SG_ 533 SGU20_Object_vx 0;
BA_ "GenSigTimeoutValue" SG_ 533 SGU20_Object_vx 0;
BA_ "EventCommandSignal" SG_ 533 SGU20_Object_vy 0;
BA_ "GatewayedSignals" SG_ 533 SGU20_Object_vy 0;
BA_ "GenSigInvalidValue" SG_ 533 SGU20_Object_vy 0;
BA_ "GenSigTimeoutValue" SG_ 533 SGU20_Object_vy 0;
BA_ "EventCommandSignal" SG_ 533 SGU20_Object_wExist 0;
BA_ "GatewayedSignals" SG_ 533 SGU20_Object_wExist 0;
BA_ "GenSigInvalidValue" SG_ 533 SGU20_Object_wExist 0;
BA_ "GenSigTimeoutValue" SG_ 533 SGU20_Object_wExist 0;
BA_ "EventCommandSignal" SG_ 533 SGU20_Object_wObstacle 0;
BA_ "GatewayedSignals" SG_ 533 SGU20_Object_wObstacle 0;
BA_ "GenSigInvalidValue" SG_ 533 SGU20_Object_wObstacle 0;
BA_ "GenSigTimeoutValue" SG_ 533 SGU20_Object_wObstacle 0;
BA_ "EventCommandSignal" SG_ 534 SGU21_BlockCounter 0;
BA_ "GatewayedSignals" SG_ 534 SGU21_BlockCounter 0;
BA_ "GenSigInvalidValue" SG_ 534 SGU21_BlockCounter 0;
BA_ "GenSigTimeoutValue" SG_ 534 SGU21_BlockCounter 0;
BA_ "EventCommandSignal" SG_ 534 SGU21_LifeCycles_OBJ 0;
BA_ "GatewayedSignals" SG_ 534 SGU21_LifeCycles_OBJ 0;
BA_ "GenSigInvalidValue" SG_ 534 SGU21_LifeCycles_OBJ 0;
BA_ "GenSigTimeoutValue" SG_ 534 SGU21_LifeCycles_OBJ 0;
BA_ "EventCommandSignal" SG_ 534 SGU21_Msg_AliveCounter 0;
BA_ "GatewayedSignals" SG_ 534 SGU21_Msg_AliveCounter 0;
BA_ "GenSigInvalidValue" SG_ 534 SGU21_Msg_AliveCounter 0;
BA_ "GenSigTimeoutValue" SG_ 534 SGU21_Msg_AliveCounter 0;
BA_ "EventCommandSignal" SG_ 534 SGU21_Msg_CheckSum 0;
BA_ "GatewayedSignals" SG_ 534 SGU21_Msg_CheckSum 0;
BA_ "GenSigInvalidValue" SG_ 534 SGU21_Msg_CheckSum 0;
BA_ "GenSigTimeoutValue" SG_ 534 SGU21_Msg_CheckSum 0;
BA_ "IsCrcSignal" SG_ 534 SGU21_Msg_CheckSum 1;
BA_ "EventCommandSignal" SG_ 534 SGU21_ObjRCS_21 0;
BA_ "GatewayedSignals" SG_ 534 SGU21_ObjRCS_21 0;
BA_ "GenSigInvalidValue" SG_ 534 SGU21_ObjRCS_21 0;
BA_ "GenSigTimeoutValue" SG_ 534 SGU21_ObjRCS_21 0;
BA_ "EventCommandSignal" SG_ 534 SGU21_Obj_DistLat_rms 0;
BA_ "GatewayedSignals" SG_ 534 SGU21_Obj_DistLat_rms 0;
BA_ "GenSigInvalidValue" SG_ 534 SGU21_Obj_DistLat_rms 0;
BA_ "GenSigTimeoutValue" SG_ 534 SGU21_Obj_DistLat_rms 0;
BA_ "EventCommandSignal" SG_ 534 SGU21_Obj_VrelLong_rms 0;
BA_ "GatewayedSignals" SG_ 534 SGU21_Obj_VrelLong_rms 0;
BA_ "GenSigInvalidValue" SG_ 534 SGU21_Obj_VrelLong_rms 0;
BA_ "GenSigTimeoutValue" SG_ 534 SGU21_Obj_VrelLong_rms 0;
BA_ "EventCommandSignal" SG_ 534 SGU21_Obj_Vrelat_rms 0;
BA_ "GatewayedSignals" SG_ 534 SGU21_Obj_Vrelat_rms 0;
BA_ "GenSigInvalidValue" SG_ 534 SGU21_Obj_Vrelat_rms 0;
BA_ "GenSigTimeoutValue" SG_ 534 SGU21_Obj_Vrelat_rms 0;
BA_ "EventCommandSignal" SG_ 534 SGU21_Object_DetStatus 0;
BA_ "GatewayedSignals" SG_ 534 SGU21_Object_DetStatus 0;
BA_ "GenSigInvalidValue" SG_ 534 SGU21_Object_DetStatus 0;
BA_ "GenSigTimeoutValue" SG_ 534 SGU21_Object_DetStatus 0;
BA_ "EventCommandSignal" SG_ 534 SGU21_Object_DistLong_rms 0;
BA_ "GatewayedSignals" SG_ 534 SGU21_Object_DistLong_rms 0;
BA_ "GenSigInvalidValue" SG_ 534 SGU21_Object_DistLong_rms 0;
BA_ "GenSigTimeoutValue" SG_ 534 SGU21_Object_DistLong_rms 0;
BA_ "EventCommandSignal" SG_ 534 SGU21_Object_ID 0;
BA_ "GatewayedSignals" SG_ 534 SGU21_Object_ID 0;
BA_ "GenSigInvalidValue" SG_ 534 SGU21_Object_ID 0;
BA_ "GenSigTimeoutValue" SG_ 534 SGU21_Object_ID 0;
BA_ "EventCommandSignal" SG_ 534 SGU21_Object_Motion_Pattern 0;
BA_ "GatewayedSignals" SG_ 534 SGU21_Object_Motion_Pattern 0;
BA_ "GenSigInvalidValue" SG_ 534 SGU21_Object_Motion_Pattern 0;
BA_ "GenSigTimeoutValue" SG_ 534 SGU21_Object_Motion_Pattern 0;
BA_ "EventCommandSignal" SG_ 534 SGU21_Object_Type 0;
BA_ "GatewayedSignals" SG_ 534 SGU21_Object_Type 0;
BA_ "GenSigInvalidValue" SG_ 534 SGU21_Object_Type 0;
BA_ "GenSigTimeoutValue" SG_ 534 SGU21_Object_Type 0;
BA_ "EventCommandSignal" SG_ 534 SGU21_Object_ax 0;
BA_ "GatewayedSignals" SG_ 534 SGU21_Object_ax 0;
BA_ "GenSigInvalidValue" SG_ 534 SGU21_Object_ax 0;
BA_ "GenSigTimeoutValue" SG_ 534 SGU21_Object_ax 0;
BA_ "EventCommandSignal" SG_ 534 SGU21_Object_ay 0;
BA_ "GatewayedSignals" SG_ 534 SGU21_Object_ay 0;
BA_ "GenSigInvalidValue" SG_ 534 SGU21_Object_ay 0;
BA_ "GenSigTimeoutValue" SG_ 534 SGU21_Object_ay 0;
BA_ "EventCommandSignal" SG_ 534 SGU21_Object_dx 0;
BA_ "GatewayedSignals" SG_ 534 SGU21_Object_dx 0;
BA_ "GenSigInvalidValue" SG_ 534 SGU21_Object_dx 0;
BA_ "GenSigTimeoutValue" SG_ 534 SGU21_Object_dx 0;
BA_ "EventCommandSignal" SG_ 534 SGU21_Object_dx_Rear 0;
BA_ "GatewayedSignals" SG_ 534 SGU21_Object_dx_Rear 0;
BA_ "GenSigInvalidValue" SG_ 534 SGU21_Object_dx_Rear 0;
BA_ "GenSigTimeoutValue" SG_ 534 SGU21_Object_dx_Rear 0;
BA_ "EventCommandSignal" SG_ 534 SGU21_Object_dy 0;
BA_ "GatewayedSignals" SG_ 534 SGU21_Object_dy 0;
BA_ "GenSigInvalidValue" SG_ 534 SGU21_Object_dy 0;
BA_ "GenSigTimeoutValue" SG_ 534 SGU21_Object_dy 0;
BA_ "EventCommandSignal" SG_ 534 SGU21_Object_dy_Rear 0;
BA_ "GatewayedSignals" SG_ 534 SGU21_Object_dy_Rear 0;
BA_ "GenSigInvalidValue" SG_ 534 SGU21_Object_dy_Rear 0;
BA_ "GenSigTimeoutValue" SG_ 534 SGU21_Object_dy_Rear 0;
BA_ "EventCommandSignal" SG_ 534 SGU21_Object_vx 0;
BA_ "GatewayedSignals" SG_ 534 SGU21_Object_vx 0;
BA_ "GenSigInvalidValue" SG_ 534 SGU21_Object_vx 0;
BA_ "GenSigTimeoutValue" SG_ 534 SGU21_Object_vx 0;
BA_ "EventCommandSignal" SG_ 534 SGU21_Object_vy 0;
BA_ "GatewayedSignals" SG_ 534 SGU21_Object_vy 0;
BA_ "GenSigInvalidValue" SG_ 534 SGU21_Object_vy 0;
BA_ "GenSigTimeoutValue" SG_ 534 SGU21_Object_vy 0;
BA_ "EventCommandSignal" SG_ 534 SGU21_Object_wExist 0;
BA_ "GatewayedSignals" SG_ 534 SGU21_Object_wExist 0;
BA_ "GenSigInvalidValue" SG_ 534 SGU21_Object_wExist 0;
BA_ "GenSigTimeoutValue" SG_ 534 SGU21_Object_wExist 0;
BA_ "EventCommandSignal" SG_ 534 SGU21_Object_wObstacle 0;
BA_ "GatewayedSignals" SG_ 534 SGU21_Object_wObstacle 0;
BA_ "GenSigInvalidValue" SG_ 534 SGU21_Object_wObstacle 0;
BA_ "GenSigTimeoutValue" SG_ 534 SGU21_Object_wObstacle 0;
BA_ "EventCommandSignal" SG_ 535 SGU22_BlockCounter 0;
BA_ "GatewayedSignals" SG_ 535 SGU22_BlockCounter 0;
BA_ "GenSigInvalidValue" SG_ 535 SGU22_BlockCounter 0;
BA_ "GenSigTimeoutValue" SG_ 535 SGU22_BlockCounter 0;
BA_ "EventCommandSignal" SG_ 535 SGU22_LifeCycles_OBJ 0;
BA_ "GatewayedSignals" SG_ 535 SGU22_LifeCycles_OBJ 0;
BA_ "GenSigInvalidValue" SG_ 535 SGU22_LifeCycles_OBJ 0;
BA_ "GenSigTimeoutValue" SG_ 535 SGU22_LifeCycles_OBJ 0;
BA_ "EventCommandSignal" SG_ 535 SGU22_Msg_AliveCounter 0;
BA_ "GatewayedSignals" SG_ 535 SGU22_Msg_AliveCounter 0;
BA_ "GenSigInvalidValue" SG_ 535 SGU22_Msg_AliveCounter 0;
BA_ "GenSigTimeoutValue" SG_ 535 SGU22_Msg_AliveCounter 0;
BA_ "EventCommandSignal" SG_ 535 SGU22_Msg_CheckSum 0;
BA_ "GatewayedSignals" SG_ 535 SGU22_Msg_CheckSum 0;
BA_ "GenSigInvalidValue" SG_ 535 SGU22_Msg_CheckSum 0;
BA_ "GenSigTimeoutValue" SG_ 535 SGU22_Msg_CheckSum 0;
BA_ "IsCrcSignal" SG_ 535 SGU22_Msg_CheckSum 1;
BA_ "EventCommandSignal" SG_ 535 SGU22_ObjRCS_22 0;
BA_ "GatewayedSignals" SG_ 535 SGU22_ObjRCS_22 0;
BA_ "GenSigInvalidValue" SG_ 535 SGU22_ObjRCS_22 0;
BA_ "GenSigTimeoutValue" SG_ 535 SGU22_ObjRCS_22 0;
BA_ "EventCommandSignal" SG_ 535 SGU22_Obj_DistLat_rms 0;
BA_ "GatewayedSignals" SG_ 535 SGU22_Obj_DistLat_rms 0;
BA_ "GenSigInvalidValue" SG_ 535 SGU22_Obj_DistLat_rms 0;
BA_ "GenSigTimeoutValue" SG_ 535 SGU22_Obj_DistLat_rms 0;
BA_ "EventCommandSignal" SG_ 535 SGU22_Obj_VrelLong_rms 0;
BA_ "GatewayedSignals" SG_ 535 SGU22_Obj_VrelLong_rms 0;
BA_ "GenSigInvalidValue" SG_ 535 SGU22_Obj_VrelLong_rms 0;
BA_ "GenSigTimeoutValue" SG_ 535 SGU22_Obj_VrelLong_rms 0;
BA_ "EventCommandSignal" SG_ 535 SGU22_Obj_Vrelat_rms 0;
BA_ "GatewayedSignals" SG_ 535 SGU22_Obj_Vrelat_rms 0;
BA_ "GenSigInvalidValue" SG_ 535 SGU22_Obj_Vrelat_rms 0;
BA_ "GenSigTimeoutValue" SG_ 535 SGU22_Obj_Vrelat_rms 0;
BA_ "EventCommandSignal" SG_ 535 SGU22_Object_DetStatus 0;
BA_ "GatewayedSignals" SG_ 535 SGU22_Object_DetStatus 0;
BA_ "GenSigInvalidValue" SG_ 535 SGU22_Object_DetStatus 0;
BA_ "GenSigTimeoutValue" SG_ 535 SGU22_Object_DetStatus 0;
BA_ "EventCommandSignal" SG_ 535 SGU22_Object_DistLong_rms 0;
BA_ "GatewayedSignals" SG_ 535 SGU22_Object_DistLong_rms 0;
BA_ "GenSigInvalidValue" SG_ 535 SGU22_Object_DistLong_rms 0;
BA_ "GenSigTimeoutValue" SG_ 535 SGU22_Object_DistLong_rms 0;
BA_ "EventCommandSignal" SG_ 535 SGU22_Object_ID 0;
BA_ "GatewayedSignals" SG_ 535 SGU22_Object_ID 0;
BA_ "GenSigInvalidValue" SG_ 535 SGU22_Object_ID 0;
BA_ "GenSigTimeoutValue" SG_ 535 SGU22_Object_ID 0;
BA_ "EventCommandSignal" SG_ 535 SGU22_Object_Motion_Pattern 0;
BA_ "GatewayedSignals" SG_ 535 SGU22_Object_Motion_Pattern 0;
BA_ "GenSigInvalidValue" SG_ 535 SGU22_Object_Motion_Pattern 0;
BA_ "GenSigTimeoutValue" SG_ 535 SGU22_Object_Motion_Pattern 0;
BA_ "EventCommandSignal" SG_ 535 SGU22_Object_Type 0;
BA_ "GatewayedSignals" SG_ 535 SGU22_Object_Type 0;
BA_ "GenSigInvalidValue" SG_ 535 SGU22_Object_Type 0;
BA_ "GenSigTimeoutValue" SG_ 535 SGU22_Object_Type 0;
BA_ "EventCommandSignal" SG_ 535 SGU22_Object_ax 0;
BA_ "GatewayedSignals" SG_ 535 SGU22_Object_ax 0;
BA_ "GenSigInvalidValue" SG_ 535 SGU22_Object_ax 0;
BA_ "GenSigTimeoutValue" SG_ 535 SGU22_Object_ax 0;
BA_ "EventCommandSignal" SG_ 535 SGU22_Object_ay 0;
BA_ "GatewayedSignals" SG_ 535 SGU22_Object_ay 0;
BA_ "GenSigInvalidValue" SG_ 535 SGU22_Object_ay 0;
BA_ "GenSigTimeoutValue" SG_ 535 SGU22_Object_ay 0;
BA_ "EventCommandSignal" SG_ 535 SGU22_Object_dx 0;
BA_ "GatewayedSignals" SG_ 535 SGU22_Object_dx 0;
BA_ "GenSigInvalidValue" SG_ 535 SGU22_Object_dx 0;
BA_ "GenSigTimeoutValue" SG_ 535 SGU22_Object_dx 0;
BA_ "EventCommandSignal" SG_ 535 SGU22_Object_dx_Rear 0;
BA_ "GatewayedSignals" SG_ 535 SGU22_Object_dx_Rear 0;
BA_ "GenSigInvalidValue" SG_ 535 SGU22_Object_dx_Rear 0;
BA_ "GenSigTimeoutValue" SG_ 535 SGU22_Object_dx_Rear 0;
BA_ "EventCommandSignal" SG_ 535 SGU22_Object_dy 0;
BA_ "GatewayedSignals" SG_ 535 SGU22_Object_dy 0;
BA_ "GenSigInvalidValue" SG_ 535 SGU22_Object_dy 0;
BA_ "GenSigTimeoutValue" SG_ 535 SGU22_Object_dy 0;
BA_ "EventCommandSignal" SG_ 535 SGU22_Object_dy_Rear 0;
BA_ "GatewayedSignals" SG_ 535 SGU22_Object_dy_Rear 0;
BA_ "GenSigInvalidValue" SG_ 535 SGU22_Object_dy_Rear 0;
BA_ "GenSigTimeoutValue" SG_ 535 SGU22_Object_dy_Rear 0;
BA_ "EventCommandSignal" SG_ 535 SGU22_Object_vx 0;
BA_ "GatewayedSignals" SG_ 535 SGU22_Object_vx 0;
BA_ "GenSigInvalidValue" SG_ 535 SGU22_Object_vx 0;
BA_ "GenSigTimeoutValue" SG_ 535 SGU22_Object_vx 0;
BA_ "EventCommandSignal" SG_ 535 SGU22_Object_vy 0;
BA_ "GatewayedSignals" SG_ 535 SGU22_Object_vy 0;
BA_ "GenSigInvalidValue" SG_ 535 SGU22_Object_vy 0;
BA_ "GenSigTimeoutValue" SG_ 535 SGU22_Object_vy 0;
BA_ "EventCommandSignal" SG_ 535 SGU22_Object_wExist 0;
BA_ "GatewayedSignals" SG_ 535 SGU22_Object_wExist 0;
BA_ "GenSigInvalidValue" SG_ 535 SGU22_Object_wExist 0;
BA_ "GenSigTimeoutValue" SG_ 535 SGU22_Object_wExist 0;
BA_ "EventCommandSignal" SG_ 535 SGU22_Object_wObstacle 0;
BA_ "GatewayedSignals" SG_ 535 SGU22_Object_wObstacle 0;
BA_ "GenSigInvalidValue" SG_ 535 SGU22_Object_wObstacle 0;
BA_ "GenSigTimeoutValue" SG_ 535 SGU22_Object_wObstacle 0;
BA_ "EventCommandSignal" SG_ 536 SGU23_BlockCounter 0;
BA_ "GatewayedSignals" SG_ 536 SGU23_BlockCounter 0;
BA_ "GenSigInvalidValue" SG_ 536 SGU23_BlockCounter 0;
BA_ "GenSigTimeoutValue" SG_ 536 SGU23_BlockCounter 0;
BA_ "EventCommandSignal" SG_ 536 SGU23_LifeCycles_OBJ 0;
BA_ "GatewayedSignals" SG_ 536 SGU23_LifeCycles_OBJ 0;
BA_ "GenSigInvalidValue" SG_ 536 SGU23_LifeCycles_OBJ 0;
BA_ "GenSigTimeoutValue" SG_ 536 SGU23_LifeCycles_OBJ 0;
BA_ "EventCommandSignal" SG_ 536 SGU23_Msg_AliveCounter 0;
BA_ "GatewayedSignals" SG_ 536 SGU23_Msg_AliveCounter 0;
BA_ "GenSigInvalidValue" SG_ 536 SGU23_Msg_AliveCounter 0;
BA_ "GenSigTimeoutValue" SG_ 536 SGU23_Msg_AliveCounter 0;
BA_ "EventCommandSignal" SG_ 536 SGU23_Msg_CheckSum 0;
BA_ "GatewayedSignals" SG_ 536 SGU23_Msg_CheckSum 0;
BA_ "GenSigInvalidValue" SG_ 536 SGU23_Msg_CheckSum 0;
BA_ "GenSigTimeoutValue" SG_ 536 SGU23_Msg_CheckSum 0;
BA_ "IsCrcSignal" SG_ 536 SGU23_Msg_CheckSum 1;
BA_ "EventCommandSignal" SG_ 536 SGU23_ObjRCS_23 0;
BA_ "GatewayedSignals" SG_ 536 SGU23_ObjRCS_23 0;
BA_ "GenSigInvalidValue" SG_ 536 SGU23_ObjRCS_23 0;
BA_ "GenSigTimeoutValue" SG_ 536 SGU23_ObjRCS_23 0;
BA_ "EventCommandSignal" SG_ 536 SGU23_Obj_DistLat_rms 0;
BA_ "GatewayedSignals" SG_ 536 SGU23_Obj_DistLat_rms 0;
BA_ "GenSigInvalidValue" SG_ 536 SGU23_Obj_DistLat_rms 0;
BA_ "GenSigTimeoutValue" SG_ 536 SGU23_Obj_DistLat_rms 0;
BA_ "EventCommandSignal" SG_ 536 SGU23_Obj_VrelLong_rms 0;
BA_ "GatewayedSignals" SG_ 536 SGU23_Obj_VrelLong_rms 0;
BA_ "GenSigInvalidValue" SG_ 536 SGU23_Obj_VrelLong_rms 0;
BA_ "GenSigTimeoutValue" SG_ 536 SGU23_Obj_VrelLong_rms 0;
BA_ "EventCommandSignal" SG_ 536 SGU23_Obj_Vrelat_rms 0;
BA_ "GatewayedSignals" SG_ 536 SGU23_Obj_Vrelat_rms 0;
BA_ "GenSigInvalidValue" SG_ 536 SGU23_Obj_Vrelat_rms 0;
BA_ "GenSigTimeoutValue" SG_ 536 SGU23_Obj_Vrelat_rms 0;
BA_ "EventCommandSignal" SG_ 536 SGU23_Object_DetStatus 0;
BA_ "GatewayedSignals" SG_ 536 SGU23_Object_DetStatus 0;
BA_ "GenSigInvalidValue" SG_ 536 SGU23_Object_DetStatus 0;
BA_ "GenSigTimeoutValue" SG_ 536 SGU23_Object_DetStatus 0;
BA_ "EventCommandSignal" SG_ 536 SGU23_Object_DistLong_rms 0;
BA_ "GatewayedSignals" SG_ 536 SGU23_Object_DistLong_rms 0;
BA_ "GenSigInvalidValue" SG_ 536 SGU23_Object_DistLong_rms 0;
BA_ "GenSigTimeoutValue" SG_ 536 SGU23_Object_DistLong_rms 0;
BA_ "EventCommandSignal" SG_ 536 SGU23_Object_ID 0;
BA_ "GatewayedSignals" SG_ 536 SGU23_Object_ID 0;
BA_ "GenSigInvalidValue" SG_ 536 SGU23_Object_ID 0;
BA_ "GenSigTimeoutValue" SG_ 536 SGU23_Object_ID 0;
BA_ "EventCommandSignal" SG_ 536 SGU23_Object_Motion_Pattern 0;
BA_ "GatewayedSignals" SG_ 536 SGU23_Object_Motion_Pattern 0;
BA_ "GenSigInvalidValue" SG_ 536 SGU23_Object_Motion_Pattern 0;
BA_ "GenSigTimeoutValue" SG_ 536 SGU23_Object_Motion_Pattern 0;
BA_ "EventCommandSignal" SG_ 536 SGU23_Object_Type 0;
BA_ "GatewayedSignals" SG_ 536 SGU23_Object_Type 0;
BA_ "GenSigInvalidValue" SG_ 536 SGU23_Object_Type 0;
BA_ "GenSigTimeoutValue" SG_ 536 SGU23_Object_Type 0;
BA_ "EventCommandSignal" SG_ 536 SGU23_Object_ax 0;
BA_ "GatewayedSignals" SG_ 536 SGU23_Object_ax 0;
BA_ "GenSigInvalidValue" SG_ 536 SGU23_Object_ax 0;
BA_ "GenSigTimeoutValue" SG_ 536 SGU23_Object_ax 0;
BA_ "EventCommandSignal" SG_ 536 SGU23_Object_ay 0;
BA_ "GatewayedSignals" SG_ 536 SGU23_Object_ay 0;
BA_ "GenSigInvalidValue" SG_ 536 SGU23_Object_ay 0;
BA_ "GenSigTimeoutValue" SG_ 536 SGU23_Object_ay 0;
BA_ "EventCommandSignal" SG_ 536 SGU23_Object_dx 0;
BA_ "GatewayedSignals" SG_ 536 SGU23_Object_dx 0;
BA_ "GenSigInvalidValue" SG_ 536 SGU23_Object_dx 0;
BA_ "GenSigTimeoutValue" SG_ 536 SGU23_Object_dx 0;
BA_ "EventCommandSignal" SG_ 536 SGU23_Object_dx_Rear 0;
BA_ "GatewayedSignals" SG_ 536 SGU23_Object_dx_Rear 0;
BA_ "GenSigInvalidValue" SG_ 536 SGU23_Object_dx_Rear 0;
BA_ "GenSigTimeoutValue" SG_ 536 SGU23_Object_dx_Rear 0;
BA_ "EventCommandSignal" SG_ 536 SGU23_Object_dy 0;
BA_ "GatewayedSignals" SG_ 536 SGU23_Object_dy 0;
BA_ "GenSigInvalidValue" SG_ 536 SGU23_Object_dy 0;
BA_ "GenSigTimeoutValue" SG_ 536 SGU23_Object_dy 0;
BA_ "EventCommandSignal" SG_ 536 SGU23_Object_dy_Rear 0;
BA_ "GatewayedSignals" SG_ 536 SGU23_Object_dy_Rear 0;
BA_ "GenSigInvalidValue" SG_ 536 SGU23_Object_dy_Rear 0;
BA_ "GenSigTimeoutValue" SG_ 536 SGU23_Object_dy_Rear 0;
BA_ "EventCommandSignal" SG_ 536 SGU23_Object_vx 0;
BA_ "GatewayedSignals" SG_ 536 SGU23_Object_vx 0;
BA_ "GenSigInvalidValue" SG_ 536 SGU23_Object_vx 0;
BA_ "GenSigTimeoutValue" SG_ 536 SGU23_Object_vx 0;
BA_ "EventCommandSignal" SG_ 536 SGU23_Object_vy 0;
BA_ "GatewayedSignals" SG_ 536 SGU23_Object_vy 0;
BA_ "GenSigInvalidValue" SG_ 536 SGU23_Object_vy 0;
BA_ "GenSigTimeoutValue" SG_ 536 SGU23_Object_vy 0;
BA_ "EventCommandSignal" SG_ 536 SGU23_Object_wExist 0;
BA_ "GatewayedSignals" SG_ 536 SGU23_Object_wExist 0;
BA_ "GenSigInvalidValue" SG_ 536 SGU23_Object_wExist 0;
BA_ "GenSigTimeoutValue" SG_ 536 SGU23_Object_wExist 0;
BA_ "EventCommandSignal" SG_ 536 SGU23_Object_wObstacle 0;
BA_ "GatewayedSignals" SG_ 536 SGU23_Object_wObstacle 0;
BA_ "GenSigInvalidValue" SG_ 536 SGU23_Object_wObstacle 0;
BA_ "GenSigTimeoutValue" SG_ 536 SGU23_Object_wObstacle 0;
BA_ "EventCommandSignal" SG_ 537 SGU24_BlockCounter 0;
BA_ "GatewayedSignals" SG_ 537 SGU24_BlockCounter 0;
BA_ "GenSigInvalidValue" SG_ 537 SGU24_BlockCounter 0;
BA_ "GenSigTimeoutValue" SG_ 537 SGU24_BlockCounter 0;
BA_ "EventCommandSignal" SG_ 537 SGU24_LifeCycles_OBJ 0;
BA_ "GatewayedSignals" SG_ 537 SGU24_LifeCycles_OBJ 0;
BA_ "GenSigInvalidValue" SG_ 537 SGU24_LifeCycles_OBJ 0;
BA_ "GenSigTimeoutValue" SG_ 537 SGU24_LifeCycles_OBJ 0;
BA_ "EventCommandSignal" SG_ 537 SGU24_Msg_AliveCounter 0;
BA_ "GatewayedSignals" SG_ 537 SGU24_Msg_AliveCounter 0;
BA_ "GenSigInvalidValue" SG_ 537 SGU24_Msg_AliveCounter 0;
BA_ "GenSigTimeoutValue" SG_ 537 SGU24_Msg_AliveCounter 0;
BA_ "EventCommandSignal" SG_ 537 SGU24_Msg_CheckSum 0;
BA_ "GatewayedSignals" SG_ 537 SGU24_Msg_CheckSum 0;
BA_ "GenSigInvalidValue" SG_ 537 SGU24_Msg_CheckSum 0;
BA_ "GenSigTimeoutValue" SG_ 537 SGU24_Msg_CheckSum 0;
BA_ "IsCrcSignal" SG_ 537 SGU24_Msg_CheckSum 1;
BA_ "EventCommandSignal" SG_ 537 SGU24_ObjRCS_24 0;
BA_ "GatewayedSignals" SG_ 537 SGU24_ObjRCS_24 0;
BA_ "GenSigInvalidValue" SG_ 537 SGU24_ObjRCS_24 0;
BA_ "GenSigTimeoutValue" SG_ 537 SGU24_ObjRCS_24 0;
BA_ "EventCommandSignal" SG_ 537 SGU24_Obj_DistLat_rms 0;
BA_ "GatewayedSignals" SG_ 537 SGU24_Obj_DistLat_rms 0;
BA_ "GenSigInvalidValue" SG_ 537 SGU24_Obj_DistLat_rms 0;
BA_ "GenSigTimeoutValue" SG_ 537 SGU24_Obj_DistLat_rms 0;
BA_ "EventCommandSignal" SG_ 537 SGU24_Obj_VrelLong_rms 0;
BA_ "GatewayedSignals" SG_ 537 SGU24_Obj_VrelLong_rms 0;
BA_ "GenSigInvalidValue" SG_ 537 SGU24_Obj_VrelLong_rms 0;
BA_ "GenSigTimeoutValue" SG_ 537 SGU24_Obj_VrelLong_rms 0;
BA_ "EventCommandSignal" SG_ 537 SGU24_Obj_Vrelat_rms 0;
BA_ "GatewayedSignals" SG_ 537 SGU24_Obj_Vrelat_rms 0;
BA_ "GenSigInvalidValue" SG_ 537 SGU24_Obj_Vrelat_rms 0;
BA_ "GenSigTimeoutValue" SG_ 537 SGU24_Obj_Vrelat_rms 0;
BA_ "EventCommandSignal" SG_ 537 SGU24_Object_DetStatus 0;
BA_ "GatewayedSignals" SG_ 537 SGU24_Object_DetStatus 0;
BA_ "GenSigInvalidValue" SG_ 537 SGU24_Object_DetStatus 0;
BA_ "GenSigTimeoutValue" SG_ 537 SGU24_Object_DetStatus 0;
BA_ "EventCommandSignal" SG_ 537 SGU24_Object_DistLong_rms 0;
BA_ "GatewayedSignals" SG_ 537 SGU24_Object_DistLong_rms 0;
BA_ "GenSigInvalidValue" SG_ 537 SGU24_Object_DistLong_rms 0;
BA_ "GenSigTimeoutValue" SG_ 537 SGU24_Object_DistLong_rms 0;
BA_ "EventCommandSignal" SG_ 537 SGU24_Object_ID 0;
BA_ "GatewayedSignals" SG_ 537 SGU24_Object_ID 0;
BA_ "GenSigInvalidValue" SG_ 537 SGU24_Object_ID 0;
BA_ "GenSigTimeoutValue" SG_ 537 SGU24_Object_ID 0;
BA_ "EventCommandSignal" SG_ 537 SGU24_Object_Motion_Pattern 0;
BA_ "GatewayedSignals" SG_ 537 SGU24_Object_Motion_Pattern 0;
BA_ "GenSigInvalidValue" SG_ 537 SGU24_Object_Motion_Pattern 0;
BA_ "GenSigTimeoutValue" SG_ 537 SGU24_Object_Motion_Pattern 0;
BA_ "EventCommandSignal" SG_ 537 SGU24_Object_Type 0;
BA_ "GatewayedSignals" SG_ 537 SGU24_Object_Type 0;
BA_ "GenSigInvalidValue" SG_ 537 SGU24_Object_Type 0;
BA_ "GenSigTimeoutValue" SG_ 537 SGU24_Object_Type 0;
BA_ "EventCommandSignal" SG_ 537 SGU24_Object_ax 0;
BA_ "GatewayedSignals" SG_ 537 SGU24_Object_ax 0;
BA_ "GenSigInvalidValue" SG_ 537 SGU24_Object_ax 0;
BA_ "GenSigTimeoutValue" SG_ 537 SGU24_Object_ax 0;
BA_ "EventCommandSignal" SG_ 537 SGU24_Object_ay 0;
BA_ "GatewayedSignals" SG_ 537 SGU24_Object_ay 0;
BA_ "GenSigInvalidValue" SG_ 537 SGU24_Object_ay 0;
BA_ "GenSigTimeoutValue" SG_ 537 SGU24_Object_ay 0;
BA_ "EventCommandSignal" SG_ 537 SGU24_Object_dx 0;
BA_ "GatewayedSignals" SG_ 537 SGU24_Object_dx 0;
BA_ "GenSigInvalidValue" SG_ 537 SGU24_Object_dx 0;
BA_ "GenSigTimeoutValue" SG_ 537 SGU24_Object_dx 0;
BA_ "EventCommandSignal" SG_ 537 SGU24_Object_dx_Rear 0;
BA_ "GatewayedSignals" SG_ 537 SGU24_Object_dx_Rear 0;
BA_ "GenSigInvalidValue" SG_ 537 SGU24_Object_dx_Rear 0;
BA_ "GenSigTimeoutValue" SG_ 537 SGU24_Object_dx_Rear 0;
BA_ "EventCommandSignal" SG_ 537 SGU24_Object_dy 0;
BA_ "GatewayedSignals" SG_ 537 SGU24_Object_dy 0;
BA_ "GenSigInvalidValue" SG_ 537 SGU24_Object_dy 0;
BA_ "GenSigTimeoutValue" SG_ 537 SGU24_Object_dy 0;
BA_ "EventCommandSignal" SG_ 537 SGU24_Object_dy_Rear 0;
BA_ "GatewayedSignals" SG_ 537 SGU24_Object_dy_Rear 0;
BA_ "GenSigInvalidValue" SG_ 537 SGU24_Object_dy_Rear 0;
BA_ "GenSigTimeoutValue" SG_ 537 SGU24_Object_dy_Rear 0;
BA_ "EventCommandSignal" SG_ 537 SGU24_Object_vx 0;
BA_ "GatewayedSignals" SG_ 537 SGU24_Object_vx 0;
BA_ "GenSigInvalidValue" SG_ 537 SGU24_Object_vx 0;
BA_ "GenSigTimeoutValue" SG_ 537 SGU24_Object_vx 0;
BA_ "EventCommandSignal" SG_ 537 SGU24_Object_vy 0;
BA_ "GatewayedSignals" SG_ 537 SGU24_Object_vy 0;
BA_ "GenSigInvalidValue" SG_ 537 SGU24_Object_vy 0;
BA_ "GenSigTimeoutValue" SG_ 537 SGU24_Object_vy 0;
BA_ "EventCommandSignal" SG_ 537 SGU24_Object_wExist 0;
BA_ "GatewayedSignals" SG_ 537 SGU24_Object_wExist 0;
BA_ "GenSigInvalidValue" SG_ 537 SGU24_Object_wExist 0;
BA_ "GenSigTimeoutValue" SG_ 537 SGU24_Object_wExist 0;
BA_ "EventCommandSignal" SG_ 537 SGU24_Object_wObstacle 0;
BA_ "GatewayedSignals" SG_ 537 SGU24_Object_wObstacle 0;
BA_ "GenSigInvalidValue" SG_ 537 SGU24_Object_wObstacle 0;
BA_ "GenSigTimeoutValue" SG_ 537 SGU24_Object_wObstacle 0;
BA_ "EventCommandSignal" SG_ 538 SGU25_BlockCounter 0;
BA_ "GatewayedSignals" SG_ 538 SGU25_BlockCounter 0;
BA_ "GenSigInvalidValue" SG_ 538 SGU25_BlockCounter 0;
BA_ "GenSigTimeoutValue" SG_ 538 SGU25_BlockCounter 0;
BA_ "EventCommandSignal" SG_ 538 SGU25_LifeCycles_OBJ 0;
BA_ "GatewayedSignals" SG_ 538 SGU25_LifeCycles_OBJ 0;
BA_ "GenSigInvalidValue" SG_ 538 SGU25_LifeCycles_OBJ 0;
BA_ "GenSigTimeoutValue" SG_ 538 SGU25_LifeCycles_OBJ 0;
BA_ "EventCommandSignal" SG_ 538 SGU25_Msg_AliveCounter 0;
BA_ "GatewayedSignals" SG_ 538 SGU25_Msg_AliveCounter 0;
BA_ "GenSigInvalidValue" SG_ 538 SGU25_Msg_AliveCounter 0;
BA_ "GenSigTimeoutValue" SG_ 538 SGU25_Msg_AliveCounter 0;
BA_ "EventCommandSignal" SG_ 538 SGU25_Msg_CheckSum 0;
BA_ "GatewayedSignals" SG_ 538 SGU25_Msg_CheckSum 0;
BA_ "GenSigInvalidValue" SG_ 538 SGU25_Msg_CheckSum 0;
BA_ "GenSigTimeoutValue" SG_ 538 SGU25_Msg_CheckSum 0;
BA_ "IsCrcSignal" SG_ 538 SGU25_Msg_CheckSum 1;
BA_ "EventCommandSignal" SG_ 538 SGU25_ObjRCS_25 0;
BA_ "GatewayedSignals" SG_ 538 SGU25_ObjRCS_25 0;
BA_ "GenSigInvalidValue" SG_ 538 SGU25_ObjRCS_25 0;
BA_ "GenSigTimeoutValue" SG_ 538 SGU25_ObjRCS_25 0;
BA_ "EventCommandSignal" SG_ 538 SGU25_Obj_DistLat_rms 0;
BA_ "GatewayedSignals" SG_ 538 SGU25_Obj_DistLat_rms 0;
BA_ "GenSigInvalidValue" SG_ 538 SGU25_Obj_DistLat_rms 0;
BA_ "GenSigTimeoutValue" SG_ 538 SGU25_Obj_DistLat_rms 0;
BA_ "EventCommandSignal" SG_ 538 SGU25_Obj_VrelLong_rms 0;
BA_ "GatewayedSignals" SG_ 538 SGU25_Obj_VrelLong_rms 0;
BA_ "GenSigInvalidValue" SG_ 538 SGU25_Obj_VrelLong_rms 0;
BA_ "GenSigTimeoutValue" SG_ 538 SGU25_Obj_VrelLong_rms 0;
BA_ "EventCommandSignal" SG_ 538 SGU25_Obj_Vrelat_rms 0;
BA_ "GatewayedSignals" SG_ 538 SGU25_Obj_Vrelat_rms 0;
BA_ "GenSigInvalidValue" SG_ 538 SGU25_Obj_Vrelat_rms 0;
BA_ "GenSigTimeoutValue" SG_ 538 SGU25_Obj_Vrelat_rms 0;
BA_ "EventCommandSignal" SG_ 538 SGU25_Object_DetStatus 0;
BA_ "GatewayedSignals" SG_ 538 SGU25_Object_DetStatus 0;
BA_ "GenSigInvalidValue" SG_ 538 SGU25_Object_DetStatus 0;
BA_ "GenSigTimeoutValue" SG_ 538 SGU25_Object_DetStatus 0;
BA_ "EventCommandSignal" SG_ 538 SGU25_Object_DistLong_rms 0;
BA_ "GatewayedSignals" SG_ 538 SGU25_Object_DistLong_rms 0;
BA_ "GenSigInvalidValue" SG_ 538 SGU25_Object_DistLong_rms 0;
BA_ "GenSigTimeoutValue" SG_ 538 SGU25_Object_DistLong_rms 0;
BA_ "EventCommandSignal" SG_ 538 SGU25_Object_ID 0;
BA_ "GatewayedSignals" SG_ 538 SGU25_Object_ID 0;
BA_ "GenSigInvalidValue" SG_ 538 SGU25_Object_ID 0;
BA_ "GenSigTimeoutValue" SG_ 538 SGU25_Object_ID 0;
BA_ "EventCommandSignal" SG_ 538 SGU25_Object_Motion_Pattern 0;
BA_ "GatewayedSignals" SG_ 538 SGU25_Object_Motion_Pattern 0;
BA_ "GenSigInvalidValue" SG_ 538 SGU25_Object_Motion_Pattern 0;
BA_ "GenSigTimeoutValue" SG_ 538 SGU25_Object_Motion_Pattern 0;
BA_ "EventCommandSignal" SG_ 538 SGU25_Object_Type 0;
BA_ "GatewayedSignals" SG_ 538 SGU25_Object_Type 0;
BA_ "GenSigInvalidValue" SG_ 538 SGU25_Object_Type 0;
BA_ "GenSigTimeoutValue" SG_ 538 SGU25_Object_Type 0;
BA_ "EventCommandSignal" SG_ 538 SGU25_Object_ax 0;
BA_ "GatewayedSignals" SG_ 538 SGU25_Object_ax 0;
BA_ "GenSigInvalidValue" SG_ 538 SGU25_Object_ax 0;
BA_ "GenSigTimeoutValue" SG_ 538 SGU25_Object_ax 0;
BA_ "EventCommandSignal" SG_ 538 SGU25_Object_ay 0;
BA_ "GatewayedSignals" SG_ 538 SGU25_Object_ay 0;
BA_ "GenSigInvalidValue" SG_ 538 SGU25_Object_ay 0;
BA_ "GenSigTimeoutValue" SG_ 538 SGU25_Object_ay 0;
BA_ "EventCommandSignal" SG_ 538 SGU25_Object_dx 0;
BA_ "GatewayedSignals" SG_ 538 SGU25_Object_dx 0;
BA_ "GenSigInvalidValue" SG_ 538 SGU25_Object_dx 0;
BA_ "GenSigTimeoutValue" SG_ 538 SGU25_Object_dx 0;
BA_ "EventCommandSignal" SG_ 538 SGU25_Object_dx_Rear 0;
BA_ "GatewayedSignals" SG_ 538 SGU25_Object_dx_Rear 0;
BA_ "GenSigInvalidValue" SG_ 538 SGU25_Object_dx_Rear 0;
BA_ "GenSigTimeoutValue" SG_ 538 SGU25_Object_dx_Rear 0;
BA_ "EventCommandSignal" SG_ 538 SGU25_Object_dy 0;
BA_ "GatewayedSignals" SG_ 538 SGU25_Object_dy 0;
BA_ "GenSigInvalidValue" SG_ 538 SGU25_Object_dy 0;
BA_ "GenSigTimeoutValue" SG_ 538 SGU25_Object_dy 0;
BA_ "EventCommandSignal" SG_ 538 SGU25_Object_dy_Rear 0;
BA_ "GatewayedSignals" SG_ 538 SGU25_Object_dy_Rear 0;
BA_ "GenSigInvalidValue" SG_ 538 SGU25_Object_dy_Rear 0;
BA_ "GenSigTimeoutValue" SG_ 538 SGU25_Object_dy_Rear 0;
BA_ "EventCommandSignal" SG_ 538 SGU25_Object_vx 0;
BA_ "GatewayedSignals" SG_ 538 SGU25_Object_vx 0;
BA_ "GenSigInvalidValue" SG_ 538 SGU25_Object_vx 0;
BA_ "GenSigTimeoutValue" SG_ 538 SGU25_Object_vx 0;
BA_ "EventCommandSignal" SG_ 538 SGU25_Object_vy 0;
BA_ "GatewayedSignals" SG_ 538 SGU25_Object_vy 0;
BA_ "GenSigInvalidValue" SG_ 538 SGU25_Object_vy 0;
BA_ "GenSigTimeoutValue" SG_ 538 SGU25_Object_vy 0;
BA_ "EventCommandSignal" SG_ 538 SGU25_Object_wExist 0;
BA_ "GatewayedSignals" SG_ 538 SGU25_Object_wExist 0;
BA_ "GenSigInvalidValue" SG_ 538 SGU25_Object_wExist 0;
BA_ "GenSigTimeoutValue" SG_ 538 SGU25_Object_wExist 0;
BA_ "EventCommandSignal" SG_ 538 SGU25_Object_wObstacle 0;
BA_ "GatewayedSignals" SG_ 538 SGU25_Object_wObstacle 0;
BA_ "GenSigInvalidValue" SG_ 538 SGU25_Object_wObstacle 0;
BA_ "GenSigTimeoutValue" SG_ 538 SGU25_Object_wObstacle 0;
BA_ "EventCommandSignal" SG_ 539 SGU26_BlockCounter 0;
BA_ "GatewayedSignals" SG_ 539 SGU26_BlockCounter 0;
BA_ "GenSigInvalidValue" SG_ 539 SGU26_BlockCounter 0;
BA_ "GenSigTimeoutValue" SG_ 539 SGU26_BlockCounter 0;
BA_ "EventCommandSignal" SG_ 539 SGU26_LifeCycles_OBJ 0;
BA_ "GatewayedSignals" SG_ 539 SGU26_LifeCycles_OBJ 0;
BA_ "GenSigInvalidValue" SG_ 539 SGU26_LifeCycles_OBJ 0;
BA_ "GenSigTimeoutValue" SG_ 539 SGU26_LifeCycles_OBJ 0;
BA_ "EventCommandSignal" SG_ 539 SGU26_Msg_AliveCounter 0;
BA_ "GatewayedSignals" SG_ 539 SGU26_Msg_AliveCounter 0;
BA_ "GenSigInvalidValue" SG_ 539 SGU26_Msg_AliveCounter 0;
BA_ "GenSigTimeoutValue" SG_ 539 SGU26_Msg_AliveCounter 0;
BA_ "EventCommandSignal" SG_ 539 SGU26_Msg_CheckSum 0;
BA_ "GatewayedSignals" SG_ 539 SGU26_Msg_CheckSum 0;
BA_ "GenSigInvalidValue" SG_ 539 SGU26_Msg_CheckSum 0;
BA_ "GenSigTimeoutValue" SG_ 539 SGU26_Msg_CheckSum 0;
BA_ "IsCrcSignal" SG_ 539 SGU26_Msg_CheckSum 1;
BA_ "EventCommandSignal" SG_ 539 SGU26_ObjRCS_26 0;
BA_ "GatewayedSignals" SG_ 539 SGU26_ObjRCS_26 0;
BA_ "GenSigInvalidValue" SG_ 539 SGU26_ObjRCS_26 0;
BA_ "GenSigTimeoutValue" SG_ 539 SGU26_ObjRCS_26 0;
BA_ "EventCommandSignal" SG_ 539 SGU26_Obj_DistLat_rms 0;
BA_ "GatewayedSignals" SG_ 539 SGU26_Obj_DistLat_rms 0;
BA_ "GenSigInvalidValue" SG_ 539 SGU26_Obj_DistLat_rms 0;
BA_ "GenSigTimeoutValue" SG_ 539 SGU26_Obj_DistLat_rms 0;
BA_ "EventCommandSignal" SG_ 539 SGU26_Obj_VrelLong_rms 0;
BA_ "GatewayedSignals" SG_ 539 SGU26_Obj_VrelLong_rms 0;
BA_ "GenSigInvalidValue" SG_ 539 SGU26_Obj_VrelLong_rms 0;
BA_ "GenSigTimeoutValue" SG_ 539 SGU26_Obj_VrelLong_rms 0;
BA_ "EventCommandSignal" SG_ 539 SGU26_Obj_Vrelat_rms 0;
BA_ "GatewayedSignals" SG_ 539 SGU26_Obj_Vrelat_rms 0;
BA_ "GenSigInvalidValue" SG_ 539 SGU26_Obj_Vrelat_rms 0;
BA_ "GenSigTimeoutValue" SG_ 539 SGU26_Obj_Vrelat_rms 0;
BA_ "EventCommandSignal" SG_ 539 SGU26_Object_DetStatus 0;
BA_ "GatewayedSignals" SG_ 539 SGU26_Object_DetStatus 0;
BA_ "GenSigInvalidValue" SG_ 539 SGU26_Object_DetStatus 0;
BA_ "GenSigTimeoutValue" SG_ 539 SGU26_Object_DetStatus 0;
BA_ "EventCommandSignal" SG_ 539 SGU26_Object_DistLong_rms 0;
BA_ "GatewayedSignals" SG_ 539 SGU26_Object_DistLong_rms 0;
BA_ "GenSigInvalidValue" SG_ 539 SGU26_Object_DistLong_rms 0;
BA_ "GenSigTimeoutValue" SG_ 539 SGU26_Object_DistLong_rms 0;
BA_ "EventCommandSignal" SG_ 539 SGU26_Object_ID 0;
BA_ "GatewayedSignals" SG_ 539 SGU26_Object_ID 0;
BA_ "GenSigInvalidValue" SG_ 539 SGU26_Object_ID 0;
BA_ "GenSigTimeoutValue" SG_ 539 SGU26_Object_ID 0;
BA_ "EventCommandSignal" SG_ 539 SGU26_Object_Motion_Pattern 0;
BA_ "GatewayedSignals" SG_ 539 SGU26_Object_Motion_Pattern 0;
BA_ "GenSigInvalidValue" SG_ 539 SGU26_Object_Motion_Pattern 0;
BA_ "GenSigTimeoutValue" SG_ 539 SGU26_Object_Motion_Pattern 0;
BA_ "EventCommandSignal" SG_ 539 SGU26_Object_Type 0;
BA_ "GatewayedSignals" SG_ 539 SGU26_Object_Type 0;
BA_ "GenSigInvalidValue" SG_ 539 SGU26_Object_Type 0;
BA_ "GenSigTimeoutValue" SG_ 539 SGU26_Object_Type 0;
BA_ "EventCommandSignal" SG_ 539 SGU26_Object_ax 0;
BA_ "GatewayedSignals" SG_ 539 SGU26_Object_ax 0;
BA_ "GenSigInvalidValue" SG_ 539 SGU26_Object_ax 0;
BA_ "GenSigTimeoutValue" SG_ 539 SGU26_Object_ax 0;
BA_ "EventCommandSignal" SG_ 539 SGU26_Object_ay 0;
BA_ "GatewayedSignals" SG_ 539 SGU26_Object_ay 0;
BA_ "GenSigInvalidValue" SG_ 539 SGU26_Object_ay 0;
BA_ "GenSigTimeoutValue" SG_ 539 SGU26_Object_ay 0;
BA_ "EventCommandSignal" SG_ 539 SGU26_Object_dx 0;
BA_ "GatewayedSignals" SG_ 539 SGU26_Object_dx 0;
BA_ "GenSigInvalidValue" SG_ 539 SGU26_Object_dx 0;
BA_ "GenSigTimeoutValue" SG_ 539 SGU26_Object_dx 0;
BA_ "EventCommandSignal" SG_ 539 SGU26_Object_dx_Rear 0;
BA_ "GatewayedSignals" SG_ 539 SGU26_Object_dx_Rear 0;
BA_ "GenSigInvalidValue" SG_ 539 SGU26_Object_dx_Rear 0;
BA_ "GenSigTimeoutValue" SG_ 539 SGU26_Object_dx_Rear 0;
BA_ "EventCommandSignal" SG_ 539 SGU26_Object_dy 0;
BA_ "GatewayedSignals" SG_ 539 SGU26_Object_dy 0;
BA_ "GenSigInvalidValue" SG_ 539 SGU26_Object_dy 0;
BA_ "GenSigTimeoutValue" SG_ 539 SGU26_Object_dy 0;
BA_ "EventCommandSignal" SG_ 539 SGU26_Object_dy_Rear 0;
BA_ "GatewayedSignals" SG_ 539 SGU26_Object_dy_Rear 0;
BA_ "GenSigInvalidValue" SG_ 539 SGU26_Object_dy_Rear 0;
BA_ "GenSigTimeoutValue" SG_ 539 SGU26_Object_dy_Rear 0;
BA_ "EventCommandSignal" SG_ 539 SGU26_Object_vx 0;
BA_ "GatewayedSignals" SG_ 539 SGU26_Object_vx 0;
BA_ "GenSigInvalidValue" SG_ 539 SGU26_Object_vx 0;
BA_ "GenSigTimeoutValue" SG_ 539 SGU26_Object_vx 0;
BA_ "EventCommandSignal" SG_ 539 SGU26_Object_vy 0;
BA_ "GatewayedSignals" SG_ 539 SGU26_Object_vy 0;
BA_ "GenSigInvalidValue" SG_ 539 SGU26_Object_vy 0;
BA_ "GenSigTimeoutValue" SG_ 539 SGU26_Object_vy 0;
BA_ "EventCommandSignal" SG_ 539 SGU26_Object_wExist 0;
BA_ "GatewayedSignals" SG_ 539 SGU26_Object_wExist 0;
BA_ "GenSigInvalidValue" SG_ 539 SGU26_Object_wExist 0;
BA_ "GenSigTimeoutValue" SG_ 539 SGU26_Object_wExist 0;
BA_ "EventCommandSignal" SG_ 539 SGU26_Object_wObstacle 0;
BA_ "GatewayedSignals" SG_ 539 SGU26_Object_wObstacle 0;
BA_ "GenSigInvalidValue" SG_ 539 SGU26_Object_wObstacle 0;
BA_ "GenSigTimeoutValue" SG_ 539 SGU26_Object_wObstacle 0;
BA_ "EventCommandSignal" SG_ 540 SGU27_BlockCounter 0;
BA_ "GatewayedSignals" SG_ 540 SGU27_BlockCounter 0;
BA_ "GenSigInvalidValue" SG_ 540 SGU27_BlockCounter 0;
BA_ "GenSigTimeoutValue" SG_ 540 SGU27_BlockCounter 0;
BA_ "EventCommandSignal" SG_ 540 SGU27_LifeCycles_OBJ 0;
BA_ "GatewayedSignals" SG_ 540 SGU27_LifeCycles_OBJ 0;
BA_ "GenSigInvalidValue" SG_ 540 SGU27_LifeCycles_OBJ 0;
BA_ "GenSigTimeoutValue" SG_ 540 SGU27_LifeCycles_OBJ 0;
BA_ "EventCommandSignal" SG_ 540 SGU27_Msg_AliveCounter 0;
BA_ "GatewayedSignals" SG_ 540 SGU27_Msg_AliveCounter 0;
BA_ "GenSigInvalidValue" SG_ 540 SGU27_Msg_AliveCounter 0;
BA_ "GenSigTimeoutValue" SG_ 540 SGU27_Msg_AliveCounter 0;
BA_ "EventCommandSignal" SG_ 540 SGU27_Msg_CheckSum 0;
BA_ "GatewayedSignals" SG_ 540 SGU27_Msg_CheckSum 0;
BA_ "GenSigInvalidValue" SG_ 540 SGU27_Msg_CheckSum 0;
BA_ "GenSigTimeoutValue" SG_ 540 SGU27_Msg_CheckSum 0;
BA_ "IsCrcSignal" SG_ 540 SGU27_Msg_CheckSum 1;
BA_ "EventCommandSignal" SG_ 540 SGU27_ObjRCS_27 0;
BA_ "GatewayedSignals" SG_ 540 SGU27_ObjRCS_27 0;
BA_ "GenSigInvalidValue" SG_ 540 SGU27_ObjRCS_27 0;
BA_ "GenSigTimeoutValue" SG_ 540 SGU27_ObjRCS_27 0;
BA_ "EventCommandSignal" SG_ 540 SGU27_Obj_DistLat_rms 0;
BA_ "GatewayedSignals" SG_ 540 SGU27_Obj_DistLat_rms 0;
BA_ "GenSigInvalidValue" SG_ 540 SGU27_Obj_DistLat_rms 0;
BA_ "GenSigTimeoutValue" SG_ 540 SGU27_Obj_DistLat_rms 0;
BA_ "EventCommandSignal" SG_ 540 SGU27_Obj_VrelLong_rms 0;
BA_ "GatewayedSignals" SG_ 540 SGU27_Obj_VrelLong_rms 0;
BA_ "GenSigInvalidValue" SG_ 540 SGU27_Obj_VrelLong_rms 0;
BA_ "GenSigTimeoutValue" SG_ 540 SGU27_Obj_VrelLong_rms 0;
BA_ "EventCommandSignal" SG_ 540 SGU27_Obj_Vrelat_rms 0;
BA_ "GatewayedSignals" SG_ 540 SGU27_Obj_Vrelat_rms 0;
BA_ "GenSigInvalidValue" SG_ 540 SGU27_Obj_Vrelat_rms 0;
BA_ "GenSigTimeoutValue" SG_ 540 SGU27_Obj_Vrelat_rms 0;
BA_ "EventCommandSignal" SG_ 540 SGU27_Object_DetStatus 0;
BA_ "GatewayedSignals" SG_ 540 SGU27_Object_DetStatus 0;
BA_ "GenSigInvalidValue" SG_ 540 SGU27_Object_DetStatus 0;
BA_ "GenSigTimeoutValue" SG_ 540 SGU27_Object_DetStatus 0;
BA_ "EventCommandSignal" SG_ 540 SGU27_Object_DistLong_rms 0;
BA_ "GatewayedSignals" SG_ 540 SGU27_Object_DistLong_rms 0;
BA_ "GenSigInvalidValue" SG_ 540 SGU27_Object_DistLong_rms 0;
BA_ "GenSigTimeoutValue" SG_ 540 SGU27_Object_DistLong_rms 0;
BA_ "EventCommandSignal" SG_ 540 SGU27_Object_ID 0;
BA_ "GatewayedSignals" SG_ 540 SGU27_Object_ID 0;
BA_ "GenSigInvalidValue" SG_ 540 SGU27_Object_ID 0;
BA_ "GenSigTimeoutValue" SG_ 540 SGU27_Object_ID 0;
BA_ "EventCommandSignal" SG_ 540 SGU27_Object_Motion_Pattern 0;
BA_ "GatewayedSignals" SG_ 540 SGU27_Object_Motion_Pattern 0;
BA_ "GenSigInvalidValue" SG_ 540 SGU27_Object_Motion_Pattern 0;
BA_ "GenSigTimeoutValue" SG_ 540 SGU27_Object_Motion_Pattern 0;
BA_ "EventCommandSignal" SG_ 540 SGU27_Object_Type 0;
BA_ "GatewayedSignals" SG_ 540 SGU27_Object_Type 0;
BA_ "GenSigInvalidValue" SG_ 540 SGU27_Object_Type 0;
BA_ "GenSigTimeoutValue" SG_ 540 SGU27_Object_Type 0;
BA_ "EventCommandSignal" SG_ 540 SGU27_Object_ax 0;
BA_ "GatewayedSignals" SG_ 540 SGU27_Object_ax 0;
BA_ "GenSigInvalidValue" SG_ 540 SGU27_Object_ax 0;
BA_ "GenSigTimeoutValue" SG_ 540 SGU27_Object_ax 0;
BA_ "EventCommandSignal" SG_ 540 SGU27_Object_ay 0;
BA_ "GatewayedSignals" SG_ 540 SGU27_Object_ay 0;
BA_ "GenSigInvalidValue" SG_ 540 SGU27_Object_ay 0;
BA_ "GenSigTimeoutValue" SG_ 540 SGU27_Object_ay 0;
BA_ "EventCommandSignal" SG_ 540 SGU27_Object_dx 0;
BA_ "GatewayedSignals" SG_ 540 SGU27_Object_dx 0;
BA_ "GenSigInvalidValue" SG_ 540 SGU27_Object_dx 0;
BA_ "GenSigTimeoutValue" SG_ 540 SGU27_Object_dx 0;
BA_ "EventCommandSignal" SG_ 540 SGU27_Object_dx_Rear 0;
BA_ "GatewayedSignals" SG_ 540 SGU27_Object_dx_Rear 0;
BA_ "GenSigInvalidValue" SG_ 540 SGU27_Object_dx_Rear 0;
BA_ "GenSigTimeoutValue" SG_ 540 SGU27_Object_dx_Rear 0;
BA_ "EventCommandSignal" SG_ 540 SGU27_Object_dy 0;
BA_ "GatewayedSignals" SG_ 540 SGU27_Object_dy 0;
BA_ "GenSigInvalidValue" SG_ 540 SGU27_Object_dy 0;
BA_ "GenSigTimeoutValue" SG_ 540 SGU27_Object_dy 0;
BA_ "EventCommandSignal" SG_ 540 SGU27_Object_dy_Rear 0;
BA_ "GatewayedSignals" SG_ 540 SGU27_Object_dy_Rear 0;
BA_ "GenSigInvalidValue" SG_ 540 SGU27_Object_dy_Rear 0;
BA_ "GenSigTimeoutValue" SG_ 540 SGU27_Object_dy_Rear 0;
BA_ "EventCommandSignal" SG_ 540 SGU27_Object_vx 0;
BA_ "GatewayedSignals" SG_ 540 SGU27_Object_vx 0;
BA_ "GenSigInvalidValue" SG_ 540 SGU27_Object_vx 0;
BA_ "GenSigTimeoutValue" SG_ 540 SGU27_Object_vx 0;
BA_ "EventCommandSignal" SG_ 540 SGU27_Object_vy 0;
BA_ "GatewayedSignals" SG_ 540 SGU27_Object_vy 0;
BA_ "GenSigInvalidValue" SG_ 540 SGU27_Object_vy 0;
BA_ "GenSigTimeoutValue" SG_ 540 SGU27_Object_vy 0;
BA_ "EventCommandSignal" SG_ 540 SGU27_Object_wExist 0;
BA_ "GatewayedSignals" SG_ 540 SGU27_Object_wExist 0;
BA_ "GenSigInvalidValue" SG_ 540 SGU27_Object_wExist 0;
BA_ "GenSigTimeoutValue" SG_ 540 SGU27_Object_wExist 0;
BA_ "EventCommandSignal" SG_ 540 SGU27_Object_wObstacle 0;
BA_ "GatewayedSignals" SG_ 540 SGU27_Object_wObstacle 0;
BA_ "GenSigInvalidValue" SG_ 540 SGU27_Object_wObstacle 0;
BA_ "GenSigTimeoutValue" SG_ 540 SGU27_Object_wObstacle 0;
BA_ "EventCommandSignal" SG_ 541 SGU28_BlockCounter 0;
BA_ "GatewayedSignals" SG_ 541 SGU28_BlockCounter 0;
BA_ "GenSigInvalidValue" SG_ 541 SGU28_BlockCounter 0;
BA_ "GenSigTimeoutValue" SG_ 541 SGU28_BlockCounter 0;
BA_ "EventCommandSignal" SG_ 541 SGU28_LifeCycles_OBJ 0;
BA_ "GatewayedSignals" SG_ 541 SGU28_LifeCycles_OBJ 0;
BA_ "GenSigInvalidValue" SG_ 541 SGU28_LifeCycles_OBJ 0;
BA_ "GenSigTimeoutValue" SG_ 541 SGU28_LifeCycles_OBJ 0;
BA_ "EventCommandSignal" SG_ 541 SGU28_Msg_AliveCounter 0;
BA_ "GatewayedSignals" SG_ 541 SGU28_Msg_AliveCounter 0;
BA_ "GenSigInvalidValue" SG_ 541 SGU28_Msg_AliveCounter 0;
BA_ "GenSigTimeoutValue" SG_ 541 SGU28_Msg_AliveCounter 0;
BA_ "EventCommandSignal" SG_ 541 SGU28_Msg_CheckSum 0;
BA_ "GatewayedSignals" SG_ 541 SGU28_Msg_CheckSum 0;
BA_ "GenSigInvalidValue" SG_ 541 SGU28_Msg_CheckSum 0;
BA_ "GenSigTimeoutValue" SG_ 541 SGU28_Msg_CheckSum 0;
BA_ "IsCrcSignal" SG_ 541 SGU28_Msg_CheckSum 1;
BA_ "EventCommandSignal" SG_ 541 SGU28_ObjRCS_28 0;
BA_ "GatewayedSignals" SG_ 541 SGU28_ObjRCS_28 0;
BA_ "GenSigInvalidValue" SG_ 541 SGU28_ObjRCS_28 0;
BA_ "GenSigTimeoutValue" SG_ 541 SGU28_ObjRCS_28 0;
BA_ "EventCommandSignal" SG_ 541 SGU28_Obj_DistLat_rms 0;
BA_ "GatewayedSignals" SG_ 541 SGU28_Obj_DistLat_rms 0;
BA_ "GenSigInvalidValue" SG_ 541 SGU28_Obj_DistLat_rms 0;
BA_ "GenSigTimeoutValue" SG_ 541 SGU28_Obj_DistLat_rms 0;
BA_ "EventCommandSignal" SG_ 541 SGU28_Obj_VrelLong_rms 0;
BA_ "GatewayedSignals" SG_ 541 SGU28_Obj_VrelLong_rms 0;
BA_ "GenSigInvalidValue" SG_ 541 SGU28_Obj_VrelLong_rms 0;
BA_ "GenSigTimeoutValue" SG_ 541 SGU28_Obj_VrelLong_rms 0;
BA_ "EventCommandSignal" SG_ 541 SGU28_Obj_Vrelat_rms 0;
BA_ "GatewayedSignals" SG_ 541 SGU28_Obj_Vrelat_rms 0;
BA_ "GenSigInvalidValue" SG_ 541 SGU28_Obj_Vrelat_rms 0;
BA_ "GenSigTimeoutValue" SG_ 541 SGU28_Obj_Vrelat_rms 0;
BA_ "EventCommandSignal" SG_ 541 SGU28_Object_DetStatus 0;
BA_ "GatewayedSignals" SG_ 541 SGU28_Object_DetStatus 0;
BA_ "GenSigInvalidValue" SG_ 541 SGU28_Object_DetStatus 0;
BA_ "GenSigTimeoutValue" SG_ 541 SGU28_Object_DetStatus 0;
BA_ "EventCommandSignal" SG_ 541 SGU28_Object_DistLong_rms 0;
BA_ "GatewayedSignals" SG_ 541 SGU28_Object_DistLong_rms 0;
BA_ "GenSigInvalidValue" SG_ 541 SGU28_Object_DistLong_rms 0;
BA_ "GenSigTimeoutValue" SG_ 541 SGU28_Object_DistLong_rms 0;
BA_ "EventCommandSignal" SG_ 541 SGU28_Object_ID 0;
BA_ "GatewayedSignals" SG_ 541 SGU28_Object_ID 0;
BA_ "GenSigInvalidValue" SG_ 541 SGU28_Object_ID 0;
BA_ "GenSigTimeoutValue" SG_ 541 SGU28_Object_ID 0;
BA_ "EventCommandSignal" SG_ 541 SGU28_Object_Motion_Pattern 0;
BA_ "GatewayedSignals" SG_ 541 SGU28_Object_Motion_Pattern 0;
BA_ "GenSigInvalidValue" SG_ 541 SGU28_Object_Motion_Pattern 0;
BA_ "GenSigTimeoutValue" SG_ 541 SGU28_Object_Motion_Pattern 0;
BA_ "EventCommandSignal" SG_ 541 SGU28_Object_Type 0;
BA_ "GatewayedSignals" SG_ 541 SGU28_Object_Type 0;
BA_ "GenSigInvalidValue" SG_ 541 SGU28_Object_Type 0;
BA_ "GenSigTimeoutValue" SG_ 541 SGU28_Object_Type 0;
BA_ "EventCommandSignal" SG_ 541 SGU28_Object_ax 0;
BA_ "GatewayedSignals" SG_ 541 SGU28_Object_ax 0;
BA_ "GenSigInvalidValue" SG_ 541 SGU28_Object_ax 0;
BA_ "GenSigTimeoutValue" SG_ 541 SGU28_Object_ax 0;
BA_ "EventCommandSignal" SG_ 541 SGU28_Object_ay 0;
BA_ "GatewayedSignals" SG_ 541 SGU28_Object_ay 0;
BA_ "GenSigInvalidValue" SG_ 541 SGU28_Object_ay 0;
BA_ "GenSigTimeoutValue" SG_ 541 SGU28_Object_ay 0;
BA_ "EventCommandSignal" SG_ 541 SGU28_Object_dx 0;
BA_ "GatewayedSignals" SG_ 541 SGU28_Object_dx 0;
BA_ "GenSigInvalidValue" SG_ 541 SGU28_Object_dx 0;
BA_ "GenSigTimeoutValue" SG_ 541 SGU28_Object_dx 0;
BA_ "EventCommandSignal" SG_ 541 SGU28_Object_dx_Rear 0;
BA_ "GatewayedSignals" SG_ 541 SGU28_Object_dx_Rear 0;
BA_ "GenSigInvalidValue" SG_ 541 SGU28_Object_dx_Rear 0;
BA_ "GenSigTimeoutValue" SG_ 541 SGU28_Object_dx_Rear 0;
BA_ "EventCommandSignal" SG_ 541 SGU28_Object_dy 0;
BA_ "GatewayedSignals" SG_ 541 SGU28_Object_dy 0;
BA_ "GenSigInvalidValue" SG_ 541 SGU28_Object_dy 0;
BA_ "GenSigTimeoutValue" SG_ 541 SGU28_Object_dy 0;
BA_ "EventCommandSignal" SG_ 541 SGU28_Object_dy_Rear 0;
BA_ "GatewayedSignals" SG_ 541 SGU28_Object_dy_Rear 0;
BA_ "GenSigInvalidValue" SG_ 541 SGU28_Object_dy_Rear 0;
BA_ "GenSigTimeoutValue" SG_ 541 SGU28_Object_dy_Rear 0;
BA_ "EventCommandSignal" SG_ 541 SGU28_Object_vx 0;
BA_ "GatewayedSignals" SG_ 541 SGU28_Object_vx 0;
BA_ "GenSigInvalidValue" SG_ 541 SGU28_Object_vx 0;
BA_ "GenSigTimeoutValue" SG_ 541 SGU28_Object_vx 0;
BA_ "EventCommandSignal" SG_ 541 SGU28_Object_vy 0;
BA_ "GatewayedSignals" SG_ 541 SGU28_Object_vy 0;
BA_ "GenSigInvalidValue" SG_ 541 SGU28_Object_vy 0;
BA_ "GenSigTimeoutValue" SG_ 541 SGU28_Object_vy 0;
BA_ "EventCommandSignal" SG_ 541 SGU28_Object_wExist 0;
BA_ "GatewayedSignals" SG_ 541 SGU28_Object_wExist 0;
BA_ "GenSigInvalidValue" SG_ 541 SGU28_Object_wExist 0;
BA_ "GenSigTimeoutValue" SG_ 541 SGU28_Object_wExist 0;
BA_ "EventCommandSignal" SG_ 541 SGU28_Object_wObstacle 0;
BA_ "GatewayedSignals" SG_ 541 SGU28_Object_wObstacle 0;
BA_ "GenSigInvalidValue" SG_ 541 SGU28_Object_wObstacle 0;
BA_ "GenSigTimeoutValue" SG_ 541 SGU28_Object_wObstacle 0;
BA_ "EventCommandSignal" SG_ 542 SGU29_BlockCounter 0;
BA_ "GatewayedSignals" SG_ 542 SGU29_BlockCounter 0;
BA_ "GenSigInvalidValue" SG_ 542 SGU29_BlockCounter 0;
BA_ "GenSigTimeoutValue" SG_ 542 SGU29_BlockCounter 0;
BA_ "EventCommandSignal" SG_ 542 SGU29_LifeCycles_OBJ 0;
BA_ "GatewayedSignals" SG_ 542 SGU29_LifeCycles_OBJ 0;
BA_ "GenSigInvalidValue" SG_ 542 SGU29_LifeCycles_OBJ 0;
BA_ "GenSigTimeoutValue" SG_ 542 SGU29_LifeCycles_OBJ 0;
BA_ "EventCommandSignal" SG_ 542 SGU29_Msg_AliveCounter 0;
BA_ "GatewayedSignals" SG_ 542 SGU29_Msg_AliveCounter 0;
BA_ "GenSigInvalidValue" SG_ 542 SGU29_Msg_AliveCounter 0;
BA_ "GenSigTimeoutValue" SG_ 542 SGU29_Msg_AliveCounter 0;
BA_ "EventCommandSignal" SG_ 542 SGU29_Msg_CheckSum 0;
BA_ "GatewayedSignals" SG_ 542 SGU29_Msg_CheckSum 0;
BA_ "GenSigInvalidValue" SG_ 542 SGU29_Msg_CheckSum 0;
BA_ "GenSigTimeoutValue" SG_ 542 SGU29_Msg_CheckSum 0;
BA_ "IsCrcSignal" SG_ 542 SGU29_Msg_CheckSum 1;
BA_ "EventCommandSignal" SG_ 542 SGU29_ObjRCS_29 0;
BA_ "GatewayedSignals" SG_ 542 SGU29_ObjRCS_29 0;
BA_ "GenSigInvalidValue" SG_ 542 SGU29_ObjRCS_29 0;
BA_ "GenSigTimeoutValue" SG_ 542 SGU29_ObjRCS_29 0;
BA_ "EventCommandSignal" SG_ 542 SGU29_Obj_DistLat_rms 0;
BA_ "GatewayedSignals" SG_ 542 SGU29_Obj_DistLat_rms 0;
BA_ "GenSigInvalidValue" SG_ 542 SGU29_Obj_DistLat_rms 0;
BA_ "GenSigTimeoutValue" SG_ 542 SGU29_Obj_DistLat_rms 0;
BA_ "EventCommandSignal" SG_ 542 SGU29_Obj_VrelLong_rms 0;
BA_ "GatewayedSignals" SG_ 542 SGU29_Obj_VrelLong_rms 0;
BA_ "GenSigInvalidValue" SG_ 542 SGU29_Obj_VrelLong_rms 0;
BA_ "GenSigTimeoutValue" SG_ 542 SGU29_Obj_VrelLong_rms 0;
BA_ "EventCommandSignal" SG_ 542 SGU29_Obj_Vrelat_rms 0;
BA_ "GatewayedSignals" SG_ 542 SGU29_Obj_Vrelat_rms 0;
BA_ "GenSigInvalidValue" SG_ 542 SGU29_Obj_Vrelat_rms 0;
BA_ "GenSigTimeoutValue" SG_ 542 SGU29_Obj_Vrelat_rms 0;
BA_ "EventCommandSignal" SG_ 542 SGU29_Object_DetStatus 0;
BA_ "GatewayedSignals" SG_ 542 SGU29_Object_DetStatus 0;
BA_ "GenSigInvalidValue" SG_ 542 SGU29_Object_DetStatus 0;
BA_ "GenSigTimeoutValue" SG_ 542 SGU29_Object_DetStatus 0;
BA_ "EventCommandSignal" SG_ 542 SGU29_Object_DistLong_rms 0;
BA_ "GatewayedSignals" SG_ 542 SGU29_Object_DistLong_rms 0;
BA_ "GenSigInvalidValue" SG_ 542 SGU29_Object_DistLong_rms 0;
BA_ "GenSigTimeoutValue" SG_ 542 SGU29_Object_DistLong_rms 0;
BA_ "EventCommandSignal" SG_ 542 SGU29_Object_ID 0;
BA_ "GatewayedSignals" SG_ 542 SGU29_Object_ID 0;
BA_ "GenSigInvalidValue" SG_ 542 SGU29_Object_ID 0;
BA_ "GenSigTimeoutValue" SG_ 542 SGU29_Object_ID 0;
BA_ "EventCommandSignal" SG_ 542 SGU29_Object_Motion_Pattern 0;
BA_ "GatewayedSignals" SG_ 542 SGU29_Object_Motion_Pattern 0;
BA_ "GenSigInvalidValue" SG_ 542 SGU29_Object_Motion_Pattern 0;
BA_ "GenSigTimeoutValue" SG_ 542 SGU29_Object_Motion_Pattern 0;
BA_ "EventCommandSignal" SG_ 542 SGU29_Object_Type 0;
BA_ "GatewayedSignals" SG_ 542 SGU29_Object_Type 0;
BA_ "GenSigInvalidValue" SG_ 542 SGU29_Object_Type 0;
BA_ "GenSigTimeoutValue" SG_ 542 SGU29_Object_Type 0;
BA_ "EventCommandSignal" SG_ 542 SGU29_Object_ax 0;
BA_ "GatewayedSignals" SG_ 542 SGU29_Object_ax 0;
BA_ "GenSigInvalidValue" SG_ 542 SGU29_Object_ax 0;
BA_ "GenSigTimeoutValue" SG_ 542 SGU29_Object_ax 0;
BA_ "EventCommandSignal" SG_ 542 SGU29_Object_ay 0;
BA_ "GatewayedSignals" SG_ 542 SGU29_Object_ay 0;
BA_ "GenSigInvalidValue" SG_ 542 SGU29_Object_ay 0;
BA_ "GenSigTimeoutValue" SG_ 542 SGU29_Object_ay 0;
BA_ "EventCommandSignal" SG_ 542 SGU29_Object_dx 0;
BA_ "GatewayedSignals" SG_ 542 SGU29_Object_dx 0;
BA_ "GenSigInvalidValue" SG_ 542 SGU29_Object_dx 0;
BA_ "GenSigTimeoutValue" SG_ 542 SGU29_Object_dx 0;
BA_ "EventCommandSignal" SG_ 542 SGU29_Object_dx_Rear 0;
BA_ "GatewayedSignals" SG_ 542 SGU29_Object_dx_Rear 0;
BA_ "GenSigInvalidValue" SG_ 542 SGU29_Object_dx_Rear 0;
BA_ "GenSigTimeoutValue" SG_ 542 SGU29_Object_dx_Rear 0;
BA_ "EventCommandSignal" SG_ 542 SGU29_Object_dy 0;
BA_ "GatewayedSignals" SG_ 542 SGU29_Object_dy 0;
BA_ "GenSigInvalidValue" SG_ 542 SGU29_Object_dy 0;
BA_ "GenSigTimeoutValue" SG_ 542 SGU29_Object_dy 0;
BA_ "EventCommandSignal" SG_ 542 SGU29_Object_dy_Rear 0;
BA_ "GatewayedSignals" SG_ 542 SGU29_Object_dy_Rear 0;
BA_ "GenSigInvalidValue" SG_ 542 SGU29_Object_dy_Rear 0;
BA_ "GenSigTimeoutValue" SG_ 542 SGU29_Object_dy_Rear 0;
BA_ "EventCommandSignal" SG_ 542 SGU29_Object_vx 0;
BA_ "GatewayedSignals" SG_ 542 SGU29_Object_vx 0;
BA_ "GenSigInvalidValue" SG_ 542 SGU29_Object_vx 0;
BA_ "GenSigTimeoutValue" SG_ 542 SGU29_Object_vx 0;
BA_ "EventCommandSignal" SG_ 542 SGU29_Object_vy 0;
BA_ "GatewayedSignals" SG_ 542 SGU29_Object_vy 0;
BA_ "GenSigInvalidValue" SG_ 542 SGU29_Object_vy 0;
BA_ "GenSigTimeoutValue" SG_ 542 SGU29_Object_vy 0;
BA_ "EventCommandSignal" SG_ 542 SGU29_Object_wExist 0;
BA_ "GatewayedSignals" SG_ 542 SGU29_Object_wExist 0;
BA_ "GenSigInvalidValue" SG_ 542 SGU29_Object_wExist 0;
BA_ "GenSigTimeoutValue" SG_ 542 SGU29_Object_wExist 0;
BA_ "EventCommandSignal" SG_ 542 SGU29_Object_wObstacle 0;
BA_ "GatewayedSignals" SG_ 542 SGU29_Object_wObstacle 0;
BA_ "GenSigInvalidValue" SG_ 542 SGU29_Object_wObstacle 0;
BA_ "GenSigTimeoutValue" SG_ 542 SGU29_Object_wObstacle 0;
BA_ "EventCommandSignal" SG_ 543 SGU30_BlockCounter 0;
BA_ "GatewayedSignals" SG_ 543 SGU30_BlockCounter 0;
BA_ "GenSigInvalidValue" SG_ 543 SGU30_BlockCounter 0;
BA_ "GenSigTimeoutValue" SG_ 543 SGU30_BlockCounter 0;
BA_ "EventCommandSignal" SG_ 543 SGU30_LifeCycles_OBJ 0;
BA_ "GatewayedSignals" SG_ 543 SGU30_LifeCycles_OBJ 0;
BA_ "GenSigInvalidValue" SG_ 543 SGU30_LifeCycles_OBJ 0;
BA_ "GenSigTimeoutValue" SG_ 543 SGU30_LifeCycles_OBJ 0;
BA_ "EventCommandSignal" SG_ 543 SGU30_Msg_AliveCounter 0;
BA_ "GatewayedSignals" SG_ 543 SGU30_Msg_AliveCounter 0;
BA_ "GenSigInvalidValue" SG_ 543 SGU30_Msg_AliveCounter 0;
BA_ "GenSigTimeoutValue" SG_ 543 SGU30_Msg_AliveCounter 0;
BA_ "EventCommandSignal" SG_ 543 SGU30_Msg_CheckSum 0;
BA_ "GatewayedSignals" SG_ 543 SGU30_Msg_CheckSum 0;
BA_ "GenSigInvalidValue" SG_ 543 SGU30_Msg_CheckSum 0;
BA_ "GenSigTimeoutValue" SG_ 543 SGU30_Msg_CheckSum 0;
BA_ "IsCrcSignal" SG_ 543 SGU30_Msg_CheckSum 1;
BA_ "EventCommandSignal" SG_ 543 SGU30_ObjRCS_30 0;
BA_ "GatewayedSignals" SG_ 543 SGU30_ObjRCS_30 0;
BA_ "GenSigInvalidValue" SG_ 543 SGU30_ObjRCS_30 0;
BA_ "GenSigTimeoutValue" SG_ 543 SGU30_ObjRCS_30 0;
BA_ "EventCommandSignal" SG_ 543 SGU30_Obj_DistLat_rms 0;
BA_ "GatewayedSignals" SG_ 543 SGU30_Obj_DistLat_rms 0;
BA_ "GenSigInvalidValue" SG_ 543 SGU30_Obj_DistLat_rms 0;
BA_ "GenSigTimeoutValue" SG_ 543 SGU30_Obj_DistLat_rms 0;
BA_ "EventCommandSignal" SG_ 543 SGU30_Obj_VrelLong_rms 0;
BA_ "GatewayedSignals" SG_ 543 SGU30_Obj_VrelLong_rms 0;
BA_ "GenSigInvalidValue" SG_ 543 SGU30_Obj_VrelLong_rms 0;
BA_ "GenSigTimeoutValue" SG_ 543 SGU30_Obj_VrelLong_rms 0;
BA_ "EventCommandSignal" SG_ 543 SGU30_Obj_Vrelat_rms 0;
BA_ "GatewayedSignals" SG_ 543 SGU30_Obj_Vrelat_rms 0;
BA_ "GenSigInvalidValue" SG_ 543 SGU30_Obj_Vrelat_rms 0;
BA_ "GenSigTimeoutValue" SG_ 543 SGU30_Obj_Vrelat_rms 0;
BA_ "EventCommandSignal" SG_ 543 SGU30_Object_DetStatus 0;
BA_ "GatewayedSignals" SG_ 543 SGU30_Object_DetStatus 0;
BA_ "GenSigInvalidValue" SG_ 543 SGU30_Object_DetStatus 0;
BA_ "GenSigTimeoutValue" SG_ 543 SGU30_Object_DetStatus 0;
BA_ "EventCommandSignal" SG_ 543 SGU30_Object_DistLong_rms 0;
BA_ "GatewayedSignals" SG_ 543 SGU30_Object_DistLong_rms 0;
BA_ "GenSigInvalidValue" SG_ 543 SGU30_Object_DistLong_rms 0;
BA_ "GenSigTimeoutValue" SG_ 543 SGU30_Object_DistLong_rms 0;
BA_ "EventCommandSignal" SG_ 543 SGU30_Object_ID 0;
BA_ "GatewayedSignals" SG_ 543 SGU30_Object_ID 0;
BA_ "GenSigInvalidValue" SG_ 543 SGU30_Object_ID 0;
BA_ "GenSigTimeoutValue" SG_ 543 SGU30_Object_ID 0;
BA_ "EventCommandSignal" SG_ 543 SGU30_Object_Motion_Pattern 0;
BA_ "GatewayedSignals" SG_ 543 SGU30_Object_Motion_Pattern 0;
BA_ "GenSigInvalidValue" SG_ 543 SGU30_Object_Motion_Pattern 0;
BA_ "GenSigTimeoutValue" SG_ 543 SGU30_Object_Motion_Pattern 0;
BA_ "EventCommandSignal" SG_ 543 SGU30_Object_Type 0;
BA_ "GatewayedSignals" SG_ 543 SGU30_Object_Type 0;
BA_ "GenSigInvalidValue" SG_ 543 SGU30_Object_Type 0;
BA_ "GenSigTimeoutValue" SG_ 543 SGU30_Object_Type 0;
BA_ "EventCommandSignal" SG_ 543 SGU30_Object_ax 0;
BA_ "GatewayedSignals" SG_ 543 SGU30_Object_ax 0;
BA_ "GenSigInvalidValue" SG_ 543 SGU30_Object_ax 0;
BA_ "GenSigTimeoutValue" SG_ 543 SGU30_Object_ax 0;
BA_ "EventCommandSignal" SG_ 543 SGU30_Object_ay 0;
BA_ "GatewayedSignals" SG_ 543 SGU30_Object_ay 0;
BA_ "GenSigInvalidValue" SG_ 543 SGU30_Object_ay 0;
BA_ "GenSigTimeoutValue" SG_ 543 SGU30_Object_ay 0;
BA_ "EventCommandSignal" SG_ 543 SGU30_Object_dx 0;
BA_ "GatewayedSignals" SG_ 543 SGU30_Object_dx 0;
BA_ "GenSigInvalidValue" SG_ 543 SGU30_Object_dx 0;
BA_ "GenSigTimeoutValue" SG_ 543 SGU30_Object_dx 0;
BA_ "EventCommandSignal" SG_ 543 SGU30_Object_dx_Rear 0;
BA_ "GatewayedSignals" SG_ 543 SGU30_Object_dx_Rear 0;
BA_ "GenSigInvalidValue" SG_ 543 SGU30_Object_dx_Rear 0;
BA_ "GenSigTimeoutValue" SG_ 543 SGU30_Object_dx_Rear 0;
BA_ "EventCommandSignal" SG_ 543 SGU30_Object_dy 0;
BA_ "GatewayedSignals" SG_ 543 SGU30_Object_dy 0;
BA_ "GenSigInvalidValue" SG_ 543 SGU30_Object_dy 0;
BA_ "GenSigTimeoutValue" SG_ 543 SGU30_Object_dy 0;
BA_ "EventCommandSignal" SG_ 543 SGU30_Object_dy_Rear 0;
BA_ "GatewayedSignals" SG_ 543 SGU30_Object_dy_Rear 0;
BA_ "GenSigInvalidValue" SG_ 543 SGU30_Object_dy_Rear 0;
BA_ "GenSigTimeoutValue" SG_ 543 SGU30_Object_dy_Rear 0;
BA_ "EventCommandSignal" SG_ 543 SGU30_Object_vx 0;
BA_ "GatewayedSignals" SG_ 543 SGU30_Object_vx 0;
BA_ "GenSigInvalidValue" SG_ 543 SGU30_Object_vx 0;
BA_ "GenSigTimeoutValue" SG_ 543 SGU30_Object_vx 0;
BA_ "EventCommandSignal" SG_ 543 SGU30_Object_vy 0;
BA_ "GatewayedSignals" SG_ 543 SGU30_Object_vy 0;
BA_ "GenSigInvalidValue" SG_ 543 SGU30_Object_vy 0;
BA_ "GenSigTimeoutValue" SG_ 543 SGU30_Object_vy 0;
BA_ "EventCommandSignal" SG_ 543 SGU30_Object_wExist 0;
BA_ "GatewayedSignals" SG_ 543 SGU30_Object_wExist 0;
BA_ "GenSigInvalidValue" SG_ 543 SGU30_Object_wExist 0;
BA_ "GenSigTimeoutValue" SG_ 543 SGU30_Object_wExist 0;
BA_ "EventCommandSignal" SG_ 543 SGU30_Object_wObstacle 0;
BA_ "GatewayedSignals" SG_ 543 SGU30_Object_wObstacle 0;
BA_ "GenSigInvalidValue" SG_ 543 SGU30_Object_wObstacle 0;
BA_ "GenSigTimeoutValue" SG_ 543 SGU30_Object_wObstacle 0;
BA_ "EventCommandSignal" SG_ 544 SGU31_BlockCounter 0;
BA_ "GatewayedSignals" SG_ 544 SGU31_BlockCounter 0;
BA_ "GenSigInvalidValue" SG_ 544 SGU31_BlockCounter 0;
BA_ "GenSigTimeoutValue" SG_ 544 SGU31_BlockCounter 0;
BA_ "EventCommandSignal" SG_ 544 SGU31_LifeCycles_OBJ 0;
BA_ "GatewayedSignals" SG_ 544 SGU31_LifeCycles_OBJ 0;
BA_ "GenSigInvalidValue" SG_ 544 SGU31_LifeCycles_OBJ 0;
BA_ "GenSigTimeoutValue" SG_ 544 SGU31_LifeCycles_OBJ 0;
BA_ "EventCommandSignal" SG_ 544 SGU31_Msg_AliveCounter 0;
BA_ "GatewayedSignals" SG_ 544 SGU31_Msg_AliveCounter 0;
BA_ "GenSigInvalidValue" SG_ 544 SGU31_Msg_AliveCounter 0;
BA_ "GenSigTimeoutValue" SG_ 544 SGU31_Msg_AliveCounter 0;
BA_ "EventCommandSignal" SG_ 544 SGU31_Msg_CheckSum 0;
BA_ "GatewayedSignals" SG_ 544 SGU31_Msg_CheckSum 0;
BA_ "GenSigInvalidValue" SG_ 544 SGU31_Msg_CheckSum 0;
BA_ "GenSigTimeoutValue" SG_ 544 SGU31_Msg_CheckSum 0;
BA_ "IsCrcSignal" SG_ 544 SGU31_Msg_CheckSum 1;
BA_ "EventCommandSignal" SG_ 544 SGU31_ObjRCS_31 0;
BA_ "GatewayedSignals" SG_ 544 SGU31_ObjRCS_31 0;
BA_ "GenSigInvalidValue" SG_ 544 SGU31_ObjRCS_31 0;
BA_ "GenSigTimeoutValue" SG_ 544 SGU31_ObjRCS_31 0;
BA_ "EventCommandSignal" SG_ 544 SGU31_Obj_DistLat_rms 0;
BA_ "GatewayedSignals" SG_ 544 SGU31_Obj_DistLat_rms 0;
BA_ "GenSigInvalidValue" SG_ 544 SGU31_Obj_DistLat_rms 0;
BA_ "GenSigTimeoutValue" SG_ 544 SGU31_Obj_DistLat_rms 0;
BA_ "EventCommandSignal" SG_ 544 SGU31_Obj_VrelLong_rms 0;
BA_ "GatewayedSignals" SG_ 544 SGU31_Obj_VrelLong_rms 0;
BA_ "GenSigInvalidValue" SG_ 544 SGU31_Obj_VrelLong_rms 0;
BA_ "GenSigTimeoutValue" SG_ 544 SGU31_Obj_VrelLong_rms 0;
BA_ "EventCommandSignal" SG_ 544 SGU31_Obj_Vrelat_rms 0;
BA_ "GatewayedSignals" SG_ 544 SGU31_Obj_Vrelat_rms 0;
BA_ "GenSigInvalidValue" SG_ 544 SGU31_Obj_Vrelat_rms 0;
BA_ "GenSigTimeoutValue" SG_ 544 SGU31_Obj_Vrelat_rms 0;
BA_ "EventCommandSignal" SG_ 544 SGU31_Object_DetStatus 0;
BA_ "GatewayedSignals" SG_ 544 SGU31_Object_DetStatus 0;
BA_ "GenSigInvalidValue" SG_ 544 SGU31_Object_DetStatus 0;
BA_ "GenSigTimeoutValue" SG_ 544 SGU31_Object_DetStatus 0;
BA_ "EventCommandSignal" SG_ 544 SGU31_Object_DistLong_rms 0;
BA_ "GatewayedSignals" SG_ 544 SGU31_Object_DistLong_rms 0;
BA_ "GenSigInvalidValue" SG_ 544 SGU31_Object_DistLong_rms 0;
BA_ "GenSigTimeoutValue" SG_ 544 SGU31_Object_DistLong_rms 0;
BA_ "EventCommandSignal" SG_ 544 SGU31_Object_ID 0;
BA_ "GatewayedSignals" SG_ 544 SGU31_Object_ID 0;
BA_ "GenSigInvalidValue" SG_ 544 SGU31_Object_ID 0;
BA_ "GenSigTimeoutValue" SG_ 544 SGU31_Object_ID 0;
BA_ "EventCommandSignal" SG_ 544 SGU31_Object_Motion_Pattern 0;
BA_ "GatewayedSignals" SG_ 544 SGU31_Object_Motion_Pattern 0;
BA_ "GenSigInvalidValue" SG_ 544 SGU31_Object_Motion_Pattern 0;
BA_ "GenSigTimeoutValue" SG_ 544 SGU31_Object_Motion_Pattern 0;
BA_ "EventCommandSignal" SG_ 544 SGU31_Object_Type 0;
BA_ "GatewayedSignals" SG_ 544 SGU31_Object_Type 0;
BA_ "GenSigInvalidValue" SG_ 544 SGU31_Object_Type 0;
BA_ "GenSigTimeoutValue" SG_ 544 SGU31_Object_Type 0;
BA_ "EventCommandSignal" SG_ 544 SGU31_Object_ax 0;
BA_ "GatewayedSignals" SG_ 544 SGU31_Object_ax 0;
BA_ "GenSigInvalidValue" SG_ 544 SGU31_Object_ax 0;
BA_ "GenSigTimeoutValue" SG_ 544 SGU31_Object_ax 0;
BA_ "EventCommandSignal" SG_ 544 SGU31_Object_ay 0;
BA_ "GatewayedSignals" SG_ 544 SGU31_Object_ay 0;
BA_ "GenSigInvalidValue" SG_ 544 SGU31_Object_ay 0;
BA_ "GenSigTimeoutValue" SG_ 544 SGU31_Object_ay 0;
BA_ "EventCommandSignal" SG_ 544 SGU31_Object_dx 0;
BA_ "GatewayedSignals" SG_ 544 SGU31_Object_dx 0;
BA_ "GenSigInvalidValue" SG_ 544 SGU31_Object_dx 0;
BA_ "GenSigTimeoutValue" SG_ 544 SGU31_Object_dx 0;
BA_ "EventCommandSignal" SG_ 544 SGU31_Object_dx_Rear 0;
BA_ "GatewayedSignals" SG_ 544 SGU31_Object_dx_Rear 0;
BA_ "GenSigInvalidValue" SG_ 544 SGU31_Object_dx_Rear 0;
BA_ "GenSigTimeoutValue" SG_ 544 SGU31_Object_dx_Rear 0;
BA_ "EventCommandSignal" SG_ 544 SGU31_Object_dy 0;
BA_ "GatewayedSignals" SG_ 544 SGU31_Object_dy 0;
BA_ "GenSigInvalidValue" SG_ 544 SGU31_Object_dy 0;
BA_ "GenSigTimeoutValue" SG_ 544 SGU31_Object_dy 0;
BA_ "EventCommandSignal" SG_ 544 SGU31_Object_dy_Rear 0;
BA_ "GatewayedSignals" SG_ 544 SGU31_Object_dy_Rear 0;
BA_ "GenSigInvalidValue" SG_ 544 SGU31_Object_dy_Rear 0;
BA_ "GenSigTimeoutValue" SG_ 544 SGU31_Object_dy_Rear 0;
BA_ "EventCommandSignal" SG_ 544 SGU31_Object_vx 0;
BA_ "GatewayedSignals" SG_ 544 SGU31_Object_vx 0;
BA_ "GenSigInvalidValue" SG_ 544 SGU31_Object_vx 0;
BA_ "GenSigTimeoutValue" SG_ 544 SGU31_Object_vx 0;
BA_ "EventCommandSignal" SG_ 544 SGU31_Object_vy 0;
BA_ "GatewayedSignals" SG_ 544 SGU31_Object_vy 0;
BA_ "GenSigInvalidValue" SG_ 544 SGU31_Object_vy 0;
BA_ "GenSigTimeoutValue" SG_ 544 SGU31_Object_vy 0;
BA_ "EventCommandSignal" SG_ 544 SGU31_Object_wExist 0;
BA_ "GatewayedSignals" SG_ 544 SGU31_Object_wExist 0;
BA_ "GenSigInvalidValue" SG_ 544 SGU31_Object_wExist 0;
BA_ "GenSigTimeoutValue" SG_ 544 SGU31_Object_wExist 0;
BA_ "EventCommandSignal" SG_ 544 SGU31_Object_wObstacle 0;
BA_ "GatewayedSignals" SG_ 544 SGU31_Object_wObstacle 0;
BA_ "GenSigInvalidValue" SG_ 544 SGU31_Object_wObstacle 0;
BA_ "GenSigTimeoutValue" SG_ 544 SGU31_Object_wObstacle 0;
BA_ "EventCommandSignal" SG_ 545 SGU32_BlockCounter 0;
BA_ "GatewayedSignals" SG_ 545 SGU32_BlockCounter 0;
BA_ "GenSigInvalidValue" SG_ 545 SGU32_BlockCounter 0;
BA_ "GenSigTimeoutValue" SG_ 545 SGU32_BlockCounter 0;
BA_ "EventCommandSignal" SG_ 545 SGU32_LifeCycles_OBJ 0;
BA_ "GatewayedSignals" SG_ 545 SGU32_LifeCycles_OBJ 0;
BA_ "GenSigInvalidValue" SG_ 545 SGU32_LifeCycles_OBJ 0;
BA_ "GenSigTimeoutValue" SG_ 545 SGU32_LifeCycles_OBJ 0;
BA_ "EventCommandSignal" SG_ 545 SGU32_Msg_AliveCounter 0;
BA_ "GatewayedSignals" SG_ 545 SGU32_Msg_AliveCounter 0;
BA_ "GenSigInvalidValue" SG_ 545 SGU32_Msg_AliveCounter 0;
BA_ "GenSigTimeoutValue" SG_ 545 SGU32_Msg_AliveCounter 0;
BA_ "EventCommandSignal" SG_ 545 SGU32_Msg_CheckSum 0;
BA_ "GatewayedSignals" SG_ 545 SGU32_Msg_CheckSum 0;
BA_ "GenSigInvalidValue" SG_ 545 SGU32_Msg_CheckSum 0;
BA_ "GenSigTimeoutValue" SG_ 545 SGU32_Msg_CheckSum 0;
BA_ "IsCrcSignal" SG_ 545 SGU32_Msg_CheckSum 1;
BA_ "EventCommandSignal" SG_ 545 SGU32_ObjRCS_32 0;
BA_ "GatewayedSignals" SG_ 545 SGU32_ObjRCS_32 0;
BA_ "GenSigInvalidValue" SG_ 545 SGU32_ObjRCS_32 0;
BA_ "GenSigTimeoutValue" SG_ 545 SGU32_ObjRCS_32 0;
BA_ "EventCommandSignal" SG_ 545 SGU32_Obj_DistLat_rms 0;
BA_ "GatewayedSignals" SG_ 545 SGU32_Obj_DistLat_rms 0;
BA_ "GenSigInvalidValue" SG_ 545 SGU32_Obj_DistLat_rms 0;
BA_ "GenSigTimeoutValue" SG_ 545 SGU32_Obj_DistLat_rms 0;
BA_ "EventCommandSignal" SG_ 545 SGU32_Obj_VrelLong_rms 0;
BA_ "GatewayedSignals" SG_ 545 SGU32_Obj_VrelLong_rms 0;
BA_ "GenSigInvalidValue" SG_ 545 SGU32_Obj_VrelLong_rms 0;
BA_ "GenSigTimeoutValue" SG_ 545 SGU32_Obj_VrelLong_rms 0;
BA_ "EventCommandSignal" SG_ 545 SGU32_Obj_Vrelat_rms 0;
BA_ "GatewayedSignals" SG_ 545 SGU32_Obj_Vrelat_rms 0;
BA_ "GenSigInvalidValue" SG_ 545 SGU32_Obj_Vrelat_rms 0;
BA_ "GenSigTimeoutValue" SG_ 545 SGU32_Obj_Vrelat_rms 0;
BA_ "EventCommandSignal" SG_ 545 SGU32_Object_DetStatus 0;
BA_ "GatewayedSignals" SG_ 545 SGU32_Object_DetStatus 0;
BA_ "GenSigInvalidValue" SG_ 545 SGU32_Object_DetStatus 0;
BA_ "GenSigTimeoutValue" SG_ 545 SGU32_Object_DetStatus 0;
BA_ "EventCommandSignal" SG_ 545 SGU32_Object_DistLong_rms 0;
BA_ "GatewayedSignals" SG_ 545 SGU32_Object_DistLong_rms 0;
BA_ "GenSigInvalidValue" SG_ 545 SGU32_Object_DistLong_rms 0;
BA_ "GenSigTimeoutValue" SG_ 545 SGU32_Object_DistLong_rms 0;
BA_ "EventCommandSignal" SG_ 545 SGU32_Object_ID 0;
BA_ "GatewayedSignals" SG_ 545 SGU32_Object_ID 0;
BA_ "GenSigInvalidValue" SG_ 545 SGU32_Object_ID 0;
BA_ "GenSigTimeoutValue" SG_ 545 SGU32_Object_ID 0;
BA_ "EventCommandSignal" SG_ 545 SGU32_Object_Motion_Pattern 0;
BA_ "GatewayedSignals" SG_ 545 SGU32_Object_Motion_Pattern 0;
BA_ "GenSigInvalidValue" SG_ 545 SGU32_Object_Motion_Pattern 0;
BA_ "GenSigTimeoutValue" SG_ 545 SGU32_Object_Motion_Pattern 0;
BA_ "EventCommandSignal" SG_ 545 SGU32_Object_Type 0;
BA_ "GatewayedSignals" SG_ 545 SGU32_Object_Type 0;
BA_ "GenSigInvalidValue" SG_ 545 SGU32_Object_Type 0;
BA_ "GenSigTimeoutValue" SG_ 545 SGU32_Object_Type 0;
BA_ "EventCommandSignal" SG_ 545 SGU32_Object_ax 0;
BA_ "GatewayedSignals" SG_ 545 SGU32_Object_ax 0;
BA_ "GenSigInvalidValue" SG_ 545 SGU32_Object_ax 0;
BA_ "GenSigTimeoutValue" SG_ 545 SGU32_Object_ax 0;
BA_ "EventCommandSignal" SG_ 545 SGU32_Object_ay 0;
BA_ "GatewayedSignals" SG_ 545 SGU32_Object_ay 0;
BA_ "GenSigInvalidValue" SG_ 545 SGU32_Object_ay 0;
BA_ "GenSigTimeoutValue" SG_ 545 SGU32_Object_ay 0;
BA_ "EventCommandSignal" SG_ 545 SGU32_Object_dx 0;
BA_ "GatewayedSignals" SG_ 545 SGU32_Object_dx 0;
BA_ "GenSigInvalidValue" SG_ 545 SGU32_Object_dx 0;
BA_ "GenSigTimeoutValue" SG_ 545 SGU32_Object_dx 0;
BA_ "EventCommandSignal" SG_ 545 SGU32_Object_dx_Rear 0;
BA_ "GatewayedSignals" SG_ 545 SGU32_Object_dx_Rear 0;
BA_ "GenSigInvalidValue" SG_ 545 SGU32_Object_dx_Rear 0;
BA_ "GenSigTimeoutValue" SG_ 545 SGU32_Object_dx_Rear 0;
BA_ "EventCommandSignal" SG_ 545 SGU32_Object_dy 0;
BA_ "GatewayedSignals" SG_ 545 SGU32_Object_dy 0;
BA_ "GenSigInvalidValue" SG_ 545 SGU32_Object_dy 0;
BA_ "GenSigTimeoutValue" SG_ 545 SGU32_Object_dy 0;
BA_ "EventCommandSignal" SG_ 545 SGU32_Object_dy_Rear 0;
BA_ "GatewayedSignals" SG_ 545 SGU32_Object_dy_Rear 0;
BA_ "GenSigInvalidValue" SG_ 545 SGU32_Object_dy_Rear 0;
BA_ "GenSigTimeoutValue" SG_ 545 SGU32_Object_dy_Rear 0;
BA_ "EventCommandSignal" SG_ 545 SGU32_Object_vx 0;
BA_ "GatewayedSignals" SG_ 545 SGU32_Object_vx 0;
BA_ "GenSigInvalidValue" SG_ 545 SGU32_Object_vx 0;
BA_ "GenSigTimeoutValue" SG_ 545 SGU32_Object_vx 0;
BA_ "EventCommandSignal" SG_ 545 SGU32_Object_vy 0;
BA_ "GatewayedSignals" SG_ 545 SGU32_Object_vy 0;
BA_ "GenSigInvalidValue" SG_ 545 SGU32_Object_vy 0;
BA_ "GenSigTimeoutValue" SG_ 545 SGU32_Object_vy 0;
BA_ "EventCommandSignal" SG_ 545 SGU32_Object_wExist 0;
BA_ "GatewayedSignals" SG_ 545 SGU32_Object_wExist 0;
BA_ "GenSigInvalidValue" SG_ 545 SGU32_Object_wExist 0;
BA_ "GenSigTimeoutValue" SG_ 545 SGU32_Object_wExist 0;
BA_ "EventCommandSignal" SG_ 545 SGU32_Object_wObstacle 0;
BA_ "GatewayedSignals" SG_ 545 SGU32_Object_wObstacle 0;
BA_ "GenSigInvalidValue" SG_ 545 SGU32_Object_wObstacle 0;
BA_ "GenSigTimeoutValue" SG_ 545 SGU32_Object_wObstacle 0;
BA_ "EventCommandSignal" SG_ 546 AngleEMEIndicatorAz 0;
BA_ "GatewayedSignals" SG_ 546 AngleEMEIndicatorAz 0;
BA_ "GenSigInvalidValue" SG_ 546 AngleEMEIndicatorAz 0;
BA_ "GenSigTimeoutValue" SG_ 546 AngleEMEIndicatorAz 0;
BA_ "EventCommandSignal" SG_ 546 AngleEMEIndicatorEl 0;
BA_ "GatewayedSignals" SG_ 546 AngleEMEIndicatorEl 0;
BA_ "GenSigInvalidValue" SG_ 546 AngleEMEIndicatorEl 0;
BA_ "GenSigTimeoutValue" SG_ 546 AngleEMEIndicatorEl 0;
BA_ "EventCommandSignal" SG_ 546 Fault_MAL_HOR_ABS_EVENT 0;
BA_ "GatewayedSignals" SG_ 546 Fault_MAL_HOR_ABS_EVENT 0;
BA_ "GenSigInvalidValue" SG_ 546 Fault_MAL_HOR_ABS_EVENT 0;
BA_ "GenSigTimeoutValue" SG_ 546 Fault_MAL_HOR_ABS_EVENT 0;
BA_ "EventCommandSignal" SG_ 546 Fault_MAL_HOR_REL_EVENT 0;
BA_ "GatewayedSignals" SG_ 546 Fault_MAL_HOR_REL_EVENT 0;
BA_ "GenSigInvalidValue" SG_ 546 Fault_MAL_HOR_REL_EVENT 0;
BA_ "GenSigTimeoutValue" SG_ 546 Fault_MAL_HOR_REL_EVENT 0;
BA_ "EventCommandSignal" SG_ 546 Fault_MAL_VER_ABS_EVENT 0;
BA_ "GatewayedSignals" SG_ 546 Fault_MAL_VER_ABS_EVENT 0;
BA_ "GenSigInvalidValue" SG_ 546 Fault_MAL_VER_ABS_EVENT 0;
BA_ "GenSigTimeoutValue" SG_ 546 Fault_MAL_VER_ABS_EVENT 0;
BA_ "EventCommandSignal" SG_ 546 Fault_MAL_VER_REL_EVENT 0;
BA_ "GatewayedSignals" SG_ 546 Fault_MAL_VER_REL_EVENT 0;
BA_ "GenSigInvalidValue" SG_ 546 Fault_MAL_VER_REL_EVENT 0;
BA_ "GenSigTimeoutValue" SG_ 546 Fault_MAL_VER_REL_EVENT 0;
BA_ "EventCommandSignal" SG_ 546 FilteredPhiSpread 0;
BA_ "GatewayedSignals" SG_ 546 FilteredPhiSpread 0;
BA_ "GenSigInvalidValue" SG_ 546 FilteredPhiSpread 0;
BA_ "GenSigTimeoutValue" SG_ 546 FilteredPhiSpread 0;
BA_ "EventCommandSignal" SG_ 546 RLR_Blindness_FaultSts 0;
BA_ "GatewayedSignals" SG_ 546 RLR_Blindness_FaultSts 0;
BA_ "GenSigInvalidValue" SG_ 546 RLR_Blindness_FaultSts 0;
BA_ "GenSigTimeoutValue" SG_ 546 RLR_Blindness_FaultSts 0;
BA_ "EventCommandSignal" SG_ 546 RLR_DTC_ALIGNMENT_NOT_DONE 0;
BA_ "GatewayedSignals" SG_ 546 RLR_DTC_ALIGNMENT_NOT_DONE 0;
BA_ "GenSigInvalidValue" SG_ 546 RLR_DTC_ALIGNMENT_NOT_DONE 0;
BA_ "GenSigTimeoutValue" SG_ 546 RLR_DTC_ALIGNMENT_NOT_DONE 0;
BA_ "EventCommandSignal" SG_ 546 RLR_DTC_CORNER_RADAR_BLIND 0;
BA_ "GatewayedSignals" SG_ 546 RLR_DTC_CORNER_RADAR_BLIND 0;
BA_ "GenSigInvalidValue" SG_ 546 RLR_DTC_CORNER_RADAR_BLIND 0;
BA_ "GenSigTimeoutValue" SG_ 546 RLR_DTC_CORNER_RADAR_BLIND 0;
BA_ "EventCommandSignal" SG_ 546 RLR_DTC_CORNER_RADAR_MISALIGNED 0;
BA_ "GatewayedSignals" SG_ 546 RLR_DTC_CORNER_RADAR_MISALIGNED 0;
BA_ "GenSigInvalidValue" SG_ 546 RLR_DTC_CORNER_RADAR_MISALIGNED 0;
BA_ "GenSigTimeoutValue" SG_ 546 RLR_DTC_CORNER_RADAR_MISALIGNED 0;
BA_ "EventCommandSignal" SG_ 546 RLR_DTC_DACORE_OOS 0;
BA_ "GatewayedSignals" SG_ 546 RLR_DTC_DACORE_OOS 0;
BA_ "GenSigInvalidValue" SG_ 546 RLR_DTC_DACORE_OOS 0;
BA_ "GenSigTimeoutValue" SG_ 546 RLR_DTC_DACORE_OOS 0;
BA_ "EventCommandSignal" SG_ 546 RLR_DTC_DSP_FAILURE 0;
BA_ "GatewayedSignals" SG_ 546 RLR_DTC_DSP_FAILURE 0;
BA_ "GenSigInvalidValue" SG_ 546 RLR_DTC_DSP_FAILURE 0;
BA_ "GenSigTimeoutValue" SG_ 546 RLR_DTC_DSP_FAILURE 0;
BA_ "EventCommandSignal" SG_ 546 RLR_DTC_HARDWARE_FAILURE 0;
BA_ "GatewayedSignals" SG_ 546 RLR_DTC_HARDWARE_FAILURE 0;
BA_ "GenSigInvalidValue" SG_ 546 RLR_DTC_HARDWARE_FAILURE 0;
BA_ "GenSigTimeoutValue" SG_ 546 RLR_DTC_HARDWARE_FAILURE 0;
BA_ "EventCommandSignal" SG_ 546 RLR_DTC_INVALID_DATA_BCS 0;
BA_ "GatewayedSignals" SG_ 546 RLR_DTC_INVALID_DATA_BCS 0;
BA_ "GenSigInvalidValue" SG_ 546 RLR_DTC_INVALID_DATA_BCS 0;
BA_ "GenSigTimeoutValue" SG_ 546 RLR_DTC_INVALID_DATA_BCS 0;
BA_ "EventCommandSignal" SG_ 546 RLR_DTC_INVALID_DATA_EPS 0;
BA_ "GatewayedSignals" SG_ 546 RLR_DTC_INVALID_DATA_EPS 0;
BA_ "GenSigInvalidValue" SG_ 546 RLR_DTC_INVALID_DATA_EPS 0;
BA_ "GenSigTimeoutValue" SG_ 546 RLR_DTC_INVALID_DATA_EPS 0;
BA_ "EventCommandSignal" SG_ 546 RLR_DTC_INVALID_DATA_SOC 0;
BA_ "GatewayedSignals" SG_ 546 RLR_DTC_INVALID_DATA_SOC 0;
BA_ "GenSigInvalidValue" SG_ 546 RLR_DTC_INVALID_DATA_SOC 0;
BA_ "GenSigTimeoutValue" SG_ 546 RLR_DTC_INVALID_DATA_SOC 0;
BA_ "EventCommandSignal" SG_ 546 RLR_DTC_LOST_COMM_BCS 0;
BA_ "GatewayedSignals" SG_ 546 RLR_DTC_LOST_COMM_BCS 0;
BA_ "GenSigInvalidValue" SG_ 546 RLR_DTC_LOST_COMM_BCS 0;
BA_ "GenSigTimeoutValue" SG_ 546 RLR_DTC_LOST_COMM_BCS 0;
BA_ "EventCommandSignal" SG_ 546 RLR_DTC_LOST_COMM_EPS 0;
BA_ "GatewayedSignals" SG_ 546 RLR_DTC_LOST_COMM_EPS 0;
BA_ "GenSigInvalidValue" SG_ 546 RLR_DTC_LOST_COMM_EPS 0;
BA_ "GenSigTimeoutValue" SG_ 546 RLR_DTC_LOST_COMM_EPS 0;
BA_ "EventCommandSignal" SG_ 546 RLR_DTC_LOST_COMM_SOC 0;
BA_ "GatewayedSignals" SG_ 546 RLR_DTC_LOST_COMM_SOC 0;
BA_ "GenSigInvalidValue" SG_ 546 RLR_DTC_LOST_COMM_SOC 0;
BA_ "GenSigTimeoutValue" SG_ 546 RLR_DTC_LOST_COMM_SOC 0;
BA_ "EventCommandSignal" SG_ 546 RLR_DTC_PUBLIC_CAN_BUSOFF 0;
BA_ "GatewayedSignals" SG_ 546 RLR_DTC_PUBLIC_CAN_BUSOFF 0;
BA_ "GenSigInvalidValue" SG_ 546 RLR_DTC_PUBLIC_CAN_BUSOFF 0;
BA_ "GenSigTimeoutValue" SG_ 546 RLR_DTC_PUBLIC_CAN_BUSOFF 0;
BA_ "EventCommandSignal" SG_ 546 RLR_DTC_RADAR_OVER_TEMPERATURE 0;
BA_ "GatewayedSignals" SG_ 546 RLR_DTC_RADAR_OVER_TEMPERATURE 0;
BA_ "GenSigInvalidValue" SG_ 546 RLR_DTC_RADAR_OVER_TEMPERATURE 0;
BA_ "GenSigTimeoutValue" SG_ 546 RLR_DTC_RADAR_OVER_TEMPERATURE 0;
BA_ "EventCommandSignal" SG_ 546 RLR_DTC_RADAR_SIDE_MISMATCH 0;
BA_ "GatewayedSignals" SG_ 546 RLR_DTC_RADAR_SIDE_MISMATCH 0;
BA_ "GenSigInvalidValue" SG_ 546 RLR_DTC_RADAR_SIDE_MISMATCH 0;
BA_ "GenSigTimeoutValue" SG_ 546 RLR_DTC_RADAR_SIDE_MISMATCH 0;
BA_ "EventCommandSignal" SG_ 546 RLR_DTC_SOC_Time_SYNC_FAIL 0;
BA_ "GatewayedSignals" SG_ 546 RLR_DTC_SOC_Time_SYNC_FAIL 0;
BA_ "GenSigInvalidValue" SG_ 546 RLR_DTC_SOC_Time_SYNC_FAIL 0;
BA_ "GenSigTimeoutValue" SG_ 546 RLR_DTC_SOC_Time_SYNC_FAIL 0;
BA_ "EventCommandSignal" SG_ 546 RLR_DTC_VARIANT_SELECTION_NOT_DONE 0;
BA_ "GatewayedSignals" SG_ 546 RLR_DTC_VARIANT_SELECTION_NOT_DONE 0;
BA_ "GenSigInvalidValue" SG_ 546 RLR_DTC_VARIANT_SELECTION_NOT_DONE 0;
BA_ "GenSigSendType" SG_ 546 RLR_DTC_VARIANT_SELECTION_NOT_DONE 1;
BA_ "GenSigTimeoutValue" SG_ 546 RLR_DTC_VARIANT_SELECTION_NOT_DONE 0;
BA_ "EventCommandSignal" SG_ 546 RLR_DTC_VBAT_HIGH 0;
BA_ "GatewayedSignals" SG_ 546 RLR_DTC_VBAT_HIGH 0;
BA_ "GenSigInvalidValue" SG_ 546 RLR_DTC_VBAT_HIGH 0;
BA_ "GenSigTimeoutValue" SG_ 546 RLR_DTC_VBAT_HIGH 0;
BA_ "EventCommandSignal" SG_ 546 RLR_DTC_VBAT_LOW 0;
BA_ "GatewayedSignals" SG_ 546 RLR_DTC_VBAT_LOW 0;
BA_ "GenSigInvalidValue" SG_ 546 RLR_DTC_VBAT_LOW 0;
BA_ "GenSigTimeoutValue" SG_ 546 RLR_DTC_VBAT_LOW 0;
BA_ "EventCommandSignal" SG_ 546 RLR_EOL_CalibrationSts 0;
BA_ "GatewayedSignals" SG_ 546 RLR_EOL_CalibrationSts 0;
BA_ "GenSigInvalidValue" SG_ 546 RLR_EOL_CalibrationSts 0;
BA_ "GenSigStartValue" SG_ 546 RLR_EOL_CalibrationSts 255;
BA_ "GenSigTimeoutValue" SG_ 546 RLR_EOL_CalibrationSts 0;
BA_ "EventCommandSignal" SG_ 546 RLR_Misalignment_FaultSts 0;
BA_ "GatewayedSignals" SG_ 546 RLR_Misalignment_FaultSts 0;
BA_ "GenSigInvalidValue" SG_ 546 RLR_Misalignment_FaultSts 0;
BA_ "GenSigTimeoutValue" SG_ 546 RLR_Misalignment_FaultSts 0;
BA_ "EventCommandSignal" SG_ 546 RLR_ModulationSts 0;
BA_ "GatewayedSignals" SG_ 546 RLR_ModulationSts 0;
BA_ "GenSigInvalidValue" SG_ 546 RLR_ModulationSts 0;
BA_ "GenSigTimeoutValue" SG_ 546 RLR_ModulationSts 0;
BA_ "EventCommandSignal" SG_ 546 RLR_RadarInfor_AliveCounter 0;
BA_ "GatewayedSignals" SG_ 546 RLR_RadarInfor_AliveCounter 0;
BA_ "GenSigInvalidValue" SG_ 546 RLR_RadarInfor_AliveCounter 0;
BA_ "GenSigTimeoutValue" SG_ 546 RLR_RadarInfor_AliveCounter 0;
BA_ "EventCommandSignal" SG_ 546 RLR_RadarInfor_Checksum 0;
BA_ "GatewayedSignals" SG_ 546 RLR_RadarInfor_Checksum 0;
BA_ "GenSigInvalidValue" SG_ 546 RLR_RadarInfor_Checksum 0;
BA_ "GenSigTimeoutValue" SG_ 546 RLR_RadarInfor_Checksum 0;
BA_ "IsCrcSignal" SG_ 546 RLR_RadarInfor_Checksum 1;
BA_ "EventCommandSignal" SG_ 546 RLR_Radar_FaultSts 0;
BA_ "GatewayedSignals" SG_ 546 RLR_Radar_FaultSts 0;
BA_ "GenSigInvalidValue" SG_ 546 RLR_Radar_FaultSts 0;
BA_ "GenSigTimeoutValue" SG_ 546 RLR_Radar_FaultSts 0;
BA_ "EventCommandSignal" SG_ 546 RLR_SDA_CalibrationSts 0;
BA_ "GatewayedSignals" SG_ 546 RLR_SDA_CalibrationSts 0;
BA_ "GenSigInvalidValue" SG_ 546 RLR_SDA_CalibrationSts 0;
BA_ "GenSigStartValue" SG_ 546 RLR_SDA_CalibrationSts 255;
BA_ "GenSigTimeoutValue" SG_ 546 RLR_SDA_CalibrationSts 0;
BA_ "EventCommandSignal" SG_ 546 RLR_SW_Baseline 0;
BA_ "GatewayedSignals" SG_ 546 RLR_SW_Baseline 0;
BA_ "GenSigInvalidValue" SG_ 546 RLR_SW_Baseline 0;
BA_ "GenSigTimeoutValue" SG_ 546 RLR_SW_Baseline 0;
BA_ "EventCommandSignal" SG_ 546 RLR_SW_MajorVersion 0;
BA_ "GatewayedSignals" SG_ 546 RLR_SW_MajorVersion 0;
BA_ "GenSigInvalidValue" SG_ 546 RLR_SW_MajorVersion 0;
BA_ "GenSigTimeoutValue" SG_ 546 RLR_SW_MajorVersion 0;
BA_ "EventCommandSignal" SG_ 546 RLR_SW_MinorVersion 0;
BA_ "GatewayedSignals" SG_ 546 RLR_SW_MinorVersion 0;
BA_ "GenSigInvalidValue" SG_ 546 RLR_SW_MinorVersion 0;
BA_ "GenSigTimeoutValue" SG_ 546 RLR_SW_MinorVersion 0;
BA_ "EventCommandSignal" SG_ 546 RLR_SW_ReleaseType 0;
BA_ "GatewayedSignals" SG_ 546 RLR_SW_ReleaseType 0;
BA_ "GenSigInvalidValue" SG_ 546 RLR_SW_ReleaseType 0;
BA_ "GenSigTimeoutValue" SG_ 546 RLR_SW_ReleaseType 0;
BA_ "EventCommandSignal" SG_ 546 azOutOfProfileCause 0;
BA_ "GatewayedSignals" SG_ 546 azOutOfProfileCause 0;
BA_ "GenSigInvalidValue" SG_ 546 azOutOfProfileCause 0;
BA_ "GenSigTimeoutValue" SG_ 546 azOutOfProfileCause 0;
BA_ "EventCommandSignal" SG_ 546 azOutOfSpecCause 0;
BA_ "GatewayedSignals" SG_ 546 azOutOfSpecCause 0;
BA_ "GenSigInvalidValue" SG_ 546 azOutOfSpecCause 0;
BA_ "GenSigTimeoutValue" SG_ 546 azOutOfSpecCause 0;
BA_ "EventCommandSignal" SG_ 546 elOutOfProfileCause 0;
BA_ "GatewayedSignals" SG_ 546 elOutOfProfileCause 0;
BA_ "GenSigInvalidValue" SG_ 546 elOutOfProfileCause 0;
BA_ "GenSigTimeoutValue" SG_ 546 elOutOfProfileCause 0;
BA_ "EventCommandSignal" SG_ 546 elOutOfSpecCause 0;
BA_ "GatewayedSignals" SG_ 546 elOutOfSpecCause 0;
BA_ "GenSigInvalidValue" SG_ 546 elOutOfSpecCause 0;
BA_ "GenSigTimeoutValue" SG_ 546 elOutOfSpecCause 0;
BA_ "EventCommandSignal" SG_ 546 highSpreadIndicator_az 0;
BA_ "GatewayedSignals" SG_ 546 highSpreadIndicator_az 0;
BA_ "GenSigInvalidValue" SG_ 546 highSpreadIndicator_az 0;
BA_ "GenSigTimeoutValue" SG_ 546 highSpreadIndicator_az 0;
BA_ "EventCommandSignal" SG_ 546 highSpreadIndicator_el 0;
BA_ "GatewayedSignals" SG_ 546 highSpreadIndicator_el 0;
BA_ "GenSigInvalidValue" SG_ 546 highSpreadIndicator_el 0;
BA_ "GenSigTimeoutValue" SG_ 546 highSpreadIndicator_el 0;
BA_ "EventCommandSignal" SG_ 546 malStablePosAz 0;
BA_ "GatewayedSignals" SG_ 546 malStablePosAz 0;
BA_ "GenSigInvalidValue" SG_ 546 malStablePosAz 0;
BA_ "GenSigTimeoutValue" SG_ 546 malStablePosAz 0;
BA_ "EventCommandSignal" SG_ 546 malStablePosEl 0;
BA_ "GatewayedSignals" SG_ 546 malStablePosEl 0;
BA_ "GenSigInvalidValue" SG_ 546 malStablePosEl 0;
BA_ "GenSigTimeoutValue" SG_ 546 malStablePosEl 0;
BA_ "EventCommandSignal" SG_ 546 mountAngleCurrent_az 0;
BA_ "GatewayedSignals" SG_ 546 mountAngleCurrent_az 0;
BA_ "GenSigInvalidValue" SG_ 546 mountAngleCurrent_az 0;
BA_ "GenSigTimeoutValue" SG_ 546 mountAngleCurrent_az 0;
BA_ "EventCommandSignal" SG_ 546 mountAngleCurrent_el 0;
BA_ "GatewayedSignals" SG_ 546 mountAngleCurrent_el 0;
BA_ "GenSigInvalidValue" SG_ 546 mountAngleCurrent_el 0;
BA_ "GenSigTimeoutValue" SG_ 546 mountAngleCurrent_el 0;
BA_ "EventCommandSignal" SG_ 546 mountAngleIndicator_az 0;
BA_ "GatewayedSignals" SG_ 546 mountAngleIndicator_az 0;
BA_ "GenSigInvalidValue" SG_ 546 mountAngleIndicator_az 0;
BA_ "GenSigTimeoutValue" SG_ 546 mountAngleIndicator_az 0;
BA_ "EventCommandSignal" SG_ 546 mountAngleIndicator_el 0;
BA_ "GatewayedSignals" SG_ 546 mountAngleIndicator_el 0;
BA_ "GenSigInvalidValue" SG_ 546 mountAngleIndicator_el 0;
BA_ "GenSigTimeoutValue" SG_ 546 mountAngleIndicator_el 0;
BA_ "EventCommandSignal" SG_ 616 Time_Day 0;
BA_ "GatewayedSignals" SG_ 616 Time_Day 0;
BA_ "GenSigInvalidValue" SG_ 616 Time_Day 0;
BA_ "GenSigSendType" SG_ 616 Time_Day 1;
BA_ "GenSigStartValue" SG_ 616 Time_Day 1;
BA_ "GenSigTimeoutValue" SG_ 616 Time_Day 0;
BA_ "EventCommandSignal" SG_ 616 Time_Hour 0;
BA_ "GatewayedSignals" SG_ 616 Time_Hour 0;
BA_ "GenSigInvalidValue" SG_ 616 Time_Hour 0;
BA_ "GenSigSendType" SG_ 616 Time_Hour 1;
BA_ "GenSigStartValue" SG_ 616 Time_Hour 1;
BA_ "GenSigTimeoutValue" SG_ 616 Time_Hour 0;
BA_ "EventCommandSignal" SG_ 616 Time_Min 0;
BA_ "GatewayedSignals" SG_ 616 Time_Min 0;
BA_ "GenSigInvalidValue" SG_ 616 Time_Min 0;
BA_ "GenSigSendType" SG_ 616 Time_Min 1;
BA_ "GenSigStartValue" SG_ 616 Time_Min 1;
BA_ "GenSigTimeoutValue" SG_ 616 Time_Min 0;
BA_ "EventCommandSignal" SG_ 616 Time_Month 0;
BA_ "GatewayedSignals" SG_ 616 Time_Month 0;
BA_ "GenSigInvalidValue" SG_ 616 Time_Month 0;
BA_ "GenSigSendType" SG_ 616 Time_Month 1;
BA_ "GenSigTimeoutValue" SG_ 616 Time_Month 0;
BA_ "EventCommandSignal" SG_ 616 Time_Sec 0;
BA_ "GatewayedSignals" SG_ 616 Time_Sec 0;
BA_ "GenSigInvalidValue" SG_ 616 Time_Sec 0;
BA_ "GenSigSendType" SG_ 616 Time_Sec 1;
BA_ "GenSigStartValue" SG_ 616 Time_Sec 1;
BA_ "GenSigTimeoutValue" SG_ 616 Time_Sec 0;
BA_ "EventCommandSignal" SG_ 616 Time_Year 0;
BA_ "GatewayedSignals" SG_ 616 Time_Year 0;
BA_ "GenSigInvalidValue" SG_ 616 Time_Year 0;
BA_ "GenSigSendType" SG_ 616 Time_Year 1;
BA_ "GenSigTimeoutValue" SG_ 616 Time_Year 0;
BA_ "EventCommandSignal" SG_ 616 UMM_UsageModeSt 0;
BA_ "GatewayedSignals" SG_ 616 UMM_UsageModeSt 0;
BA_ "GenSigInvalidValue" SG_ 616 UMM_UsageModeSt 0;
BA_ "GenSigSendType" SG_ 616 UMM_UsageModeSt 1;
BA_ "GenSigStartValue" SG_ 616 UMM_UsageModeSt 7;
BA_ "GenSigTimeoutValue" SG_ 616 UMM_UsageModeSt 0;
BA_ "EventCommandSignal" SG_ 616 VMM_OTAModeSt 0;
BA_ "GatewayedSignals" SG_ 616 VMM_OTAModeSt 0;
BA_ "GenSigInvalidValue" SG_ 616 VMM_OTAModeSt 2;
BA_ "GenSigSendType" SG_ 616 VMM_OTAModeSt 1;
BA_ "GenSigStartValue" SG_ 616 VMM_OTAModeSt 2;
BA_ "GenSigTimeoutValue" SG_ 616 VMM_OTAModeSt 2;
BA_ "EventCommandSignal" SG_ 768 SYNC_FC_CRC 0;
BA_ "GatewayedSignals" SG_ 768 SYNC_FC_CRC 0;
BA_ "GenSigInvalidValue" SG_ 768 SYNC_FC_CRC 0;
BA_ "GenSigSendType" SG_ 768 SYNC_FC_CRC 1;
BA_ "GenSigTimeoutValue" SG_ 768 SYNC_FC_CRC 0;
BA_ "EventCommandSignal" SG_ 768 SYNC_FC_OVS 0;
BA_ "GatewayedSignals" SG_ 768 SYNC_FC_OVS 0;
BA_ "GenSigInvalidValue" SG_ 768 SYNC_FC_OVS 0;
BA_ "GenSigSendType" SG_ 768 SYNC_FC_OVS 1;
BA_ "GenSigTimeoutValue" SG_ 768 SYNC_FC_OVS 0;
BA_ "EventCommandSignal" SG_ 768 SYNC_FC_Reserved 0;
BA_ "GatewayedSignals" SG_ 768 SYNC_FC_Reserved 0;
BA_ "GenSigInvalidValue" SG_ 768 SYNC_FC_Reserved 0;
BA_ "GenSigSendType" SG_ 768 SYNC_FC_Reserved 1;
BA_ "GenSigTimeoutValue" SG_ 768 SYNC_FC_Reserved 0;
BA_ "EventCommandSignal" SG_ 768 SYNC_FC_SGW 0;
BA_ "GatewayedSignals" SG_ 768 SYNC_FC_SGW 0;
BA_ "GenSigInvalidValue" SG_ 768 SYNC_FC_SGW 0;
BA_ "GenSigSendType" SG_ 768 SYNC_FC_SGW 1;
BA_ "GenSigTimeoutValue" SG_ 768 SYNC_FC_SGW 0;
BA_ "EventCommandSignal" SG_ 768 SYNC_FC_Sequencecnt 0;
BA_ "GatewayedSignals" SG_ 768 SYNC_FC_Sequencecnt 0;
BA_ "GenSigInvalidValue" SG_ 768 SYNC_FC_Sequencecnt 0;
BA_ "GenSigSendType" SG_ 768 SYNC_FC_Sequencecnt 1;
BA_ "GenSigTimeoutValue" SG_ 768 SYNC_FC_Sequencecnt 0;
BA_ "EventCommandSignal" SG_ 768 SYNC_FC_SyncTime 0;
BA_ "GatewayedSignals" SG_ 768 SYNC_FC_SyncTime 0;
BA_ "GenSigInvalidValue" SG_ 768 SYNC_FC_SyncTime 0;
BA_ "GenSigSendType" SG_ 768 SYNC_FC_SyncTime 1;
BA_ "GenSigTimeoutValue" SG_ 768 SYNC_FC_SyncTime 0;
BA_ "EventCommandSignal" SG_ 768 SYNC_FC_TimeDomain 0;
BA_ "GatewayedSignals" SG_ 768 SYNC_FC_TimeDomain 0;
BA_ "GenSigInvalidValue" SG_ 768 SYNC_FC_TimeDomain 0;
BA_ "GenSigSendType" SG_ 768 SYNC_FC_TimeDomain 1;
BA_ "GenSigTimeoutValue" SG_ 768 SYNC_FC_TimeDomain 0;
BA_ "EventCommandSignal" SG_ 768 SYNC_FC_Type 0;
BA_ "GatewayedSignals" SG_ 768 SYNC_FC_Type 0;
BA_ "GenSigInvalidValue" SG_ 768 SYNC_FC_Type 0;
BA_ "GenSigSendType" SG_ 768 SYNC_FC_Type 1;
BA_ "GenSigTimeoutValue" SG_ 768 SYNC_FC_Type 0;
BA_ "VFrameFormat" BO_ 1234 14;
BA_ "VFrameFormat" BO_ 1866 14;
BA_ "VFrameFormat" BO_ 1994 14;
BA_ "VFrameFormat" BO_ 2015 14;
BA_ "VFrameFormat" BO_ 530 14;
BA_ "VFrameFormat" BO_ 531 14;
BA_ "VFrameFormat" BO_ 532 14;
BA_ "VFrameFormat" BO_ 533 14;
BA_ "VFrameFormat" BO_ 534 14;
BA_ "VFrameFormat" BO_ 535 14;
BA_ "VFrameFormat" BO_ 536 14;
BA_ "VFrameFormat" BO_ 537 14;
BA_ "VFrameFormat" BO_ 538 14;
BA_ "VFrameFormat" BO_ 539 14;
BA_ "VFrameFormat" BO_ 540 14;
BA_ "VFrameFormat" BO_ 541 14;
BA_ "VFrameFormat" BO_ 542 14;
BA_ "VFrameFormat" BO_ 543 14;
BA_ "VFrameFormat" BO_ 544 14;
BA_ "VFrameFormat" BO_ 545 14;
BA_ "VFrameFormat" BO_ 546 14;
BA_ "VFrameFormat" BO_ 616 14;
BA_ "VFrameFormat" BO_ 768 14;
VAL_ 530 SGU17_Object_DetStatus 0 "deleted" 1 "new" 2 "measured" 3 "predicted" 4 "deleted for merge" 5 "new from  merge"  ;
VAL_ 530 SGU17_Object_Motion_Pattern 0 "Unknown" 1 "Stationary" 2 "Stopped" 3 "Moving"  ;
VAL_ 530 SGU17_Object_Type 0 "Unknown" 1 "4 wheeler" 2 "2 wheeler" 3 "Pedestrian"  ;
VAL_ 531 SGU18_Object_DetStatus 0 "deleted" 1 "new" 2 "measured" 3 "predicted" 4 "deleted for merge" 5 "new from  merge"  ;
VAL_ 531 SGU18_Object_Motion_Pattern 0 "Unknown" 1 "Stationary" 2 "Stopped" 3 "Moving"  ;
VAL_ 531 SGU18_Object_Type 0 "Unknown" 1 "4 wheeler" 2 "2 wheeler" 3 "Pedestrian"  ;
VAL_ 532 SGU19_Object_DetStatus 0 "deleted" 1 "new" 2 "measured" 3 "predicted" 4 "deleted for merge" 5 "new from  merge"  ;
VAL_ 532 SGU19_Object_Motion_Pattern 0 "Unknown" 1 "Stationary" 2 "Stopped" 3 "Moving"  ;
VAL_ 532 SGU19_Object_Type 0 "Unknown" 1 "4 wheeler" 2 "2 wheeler" 3 "Pedestrian"  ;
VAL_ 533 SGU20_Object_DetStatus 0 "deleted" 1 "new" 2 "measured" 3 "predicted" 4 "deleted for merge" 5 "new from  merge"  ;
VAL_ 533 SGU20_Object_Motion_Pattern 0 "Unknown" 1 "Stationary" 2 "Stopped" 3 "Moving"  ;
VAL_ 533 SGU20_Object_Type 0 "Unknown" 1 "4 wheeler" 2 "2 wheeler" 3 "Pedestrian"  ;
VAL_ 534 SGU21_Object_DetStatus 0 "deleted" 1 "new" 2 "measured" 3 "predicted" 4 "deleted for merge" 5 "new from  merge"  ;
VAL_ 534 SGU21_Object_Motion_Pattern 0 "Unknown" 1 "Stationary" 2 "Stopped" 3 "Moving"  ;
VAL_ 534 SGU21_Object_Type 0 "Unknown" 1 "4 wheeler" 2 "2 wheeler" 3 "Pedestrian"  ;
VAL_ 535 SGU22_Object_DetStatus 0 "deleted" 1 "new" 2 "measured" 3 "predicted" 4 "deleted for merge" 5 "new from  merge"  ;
VAL_ 535 SGU22_Object_Motion_Pattern 0 "Unknown" 1 "Stationary" 2 "Stopped" 3 "Moving"  ;
VAL_ 535 SGU22_Object_Type 0 "Unknown" 1 "4 wheeler" 2 "2 wheeler" 3 "Pedestrian"  ;
VAL_ 536 SGU23_Object_DetStatus 0 "deleted" 1 "new" 2 "measured" 3 "predicted" 4 "deleted for merge" 5 "new from  merge"  ;
VAL_ 536 SGU23_Object_Motion_Pattern 0 "Unknown" 1 "Stationary" 2 "Stopped" 3 "Moving"  ;
VAL_ 536 SGU23_Object_Type 0 "Unknown" 1 "4 wheeler" 2 "2 wheeler" 3 "Pedestrian"  ;
VAL_ 537 SGU24_Object_DetStatus 0 "deleted" 1 "new" 2 "measured" 3 "predicted" 4 "deleted for merge" 5 "new from  merge"  ;
VAL_ 537 SGU24_Object_Motion_Pattern 0 "Unknown" 1 "Stationary" 2 "Stopped" 3 "Moving"  ;
VAL_ 537 SGU24_Object_Type 0 "Unknown" 1 "4 wheeler" 2 "2 wheeler" 3 "Pedestrian"  ;
VAL_ 538 SGU25_Object_DetStatus 0 "deleted" 1 "new" 2 "measured" 3 "predicted" 4 "deleted for merge" 5 "new from  merge"  ;
VAL_ 538 SGU25_Object_Motion_Pattern 0 "Unknown" 1 "Stationary" 2 "Stopped" 3 "Moving"  ;
VAL_ 538 SGU25_Object_Type 0 "Unknown" 1 "4 wheeler" 2 "2 wheeler" 3 "Pedestrian"  ;
VAL_ 539 SGU26_Object_DetStatus 0 "deleted" 1 "new" 2 "measured" 3 "predicted" 4 "deleted for merge" 5 "new from  merge"  ;
VAL_ 539 SGU26_Object_Motion_Pattern 0 "Unknown" 1 "Stationary" 2 "Stopped" 3 "Moving"  ;
VAL_ 539 SGU26_Object_Type 0 "Unknown" 1 "4 wheeler" 2 "2 wheeler" 3 "Pedestrian"  ;
VAL_ 540 SGU27_Object_DetStatus 0 "deleted" 1 "new" 2 "measured" 3 "predicted" 4 "deleted for merge" 5 "new from  merge"  ;
VAL_ 540 SGU27_Object_Motion_Pattern 0 "Unknown" 1 "Stationary" 2 "Stopped" 3 "Moving"  ;
VAL_ 540 SGU27_Object_Type 0 "Unknown" 1 "4 wheeler" 2 "2 wheeler" 3 "Pedestrian"  ;
VAL_ 541 SGU28_Object_DetStatus 0 "deleted" 1 "new" 2 "measured" 3 "predicted" 4 "deleted for merge" 5 "new from  merge"  ;
VAL_ 541 SGU28_Object_Motion_Pattern 0 "Unknown" 1 "Stationary" 2 "Stopped" 3 "Moving"  ;
VAL_ 541 SGU28_Object_Type 0 "Unknown" 1 "4 wheeler" 2 "2 wheeler" 3 "Pedestrian"  ;
VAL_ 542 SGU29_Object_DetStatus 0 "deleted" 1 "new" 2 "measured" 3 "predicted" 4 "deleted for merge" 5 "new from  merge"  ;
VAL_ 542 SGU29_Object_Motion_Pattern 0 "Unknown" 1 "Stationary" 2 "Stopped" 3 "Moving"  ;
VAL_ 542 SGU29_Object_Type 0 "Unknown" 1 "4 wheeler" 2 "2 wheeler" 3 "Pedestrian"  ;
VAL_ 543 SGU30_Object_DetStatus 0 "deleted" 1 "new" 2 "measured" 3 "predicted" 4 "deleted for merge" 5 "new from  merge"  ;
VAL_ 543 SGU30_Object_Motion_Pattern 0 "Unknown" 1 "Stationary" 2 "Stopped" 3 "Moving"  ;
VAL_ 543 SGU30_Object_Type 0 "Unknown" 1 "4 wheeler" 2 "2 wheeler" 3 "Pedestrian"  ;
VAL_ 544 SGU31_Object_DetStatus 0 "deleted" 1 "new" 2 "measured" 3 "predicted" 4 "deleted for merge" 5 "new from  merge"  ;
VAL_ 544 SGU31_Object_Motion_Pattern 0 "Unknown" 1 "Stationary" 2 "Stopped" 3 "Moving"  ;
VAL_ 544 SGU31_Object_Type 0 "Unknown" 1 "4 wheeler" 2 "2 wheeler" 3 "Pedestrian"  ;
VAL_ 545 SGU32_Object_DetStatus 0 "deleted" 1 "new" 2 "measured" 3 "predicted" 4 "deleted for merge" 5 "new from  merge"  ;
VAL_ 545 SGU32_Object_Motion_Pattern 0 "Unknown" 1 "Stationary" 2 "Stopped" 3 "Moving"  ;
VAL_ 545 SGU32_Object_Type 0 "Unknown" 1 "4 wheeler" 2 "2 wheeler" 3 "Pedestrian"  ;
VAL_ 546 Fault_MAL_HOR_ABS_EVENT 0 "Not Fault" 1 "Fault"  ;
VAL_ 546 Fault_MAL_HOR_REL_EVENT 0 "Not Fault" 1 "Fault"  ;
VAL_ 546 Fault_MAL_VER_ABS_EVENT 0 "Not Fault" 1 "Fault"  ;
VAL_ 546 Fault_MAL_VER_REL_EVENT 0 "Not Fault" 1 "Fault"  ;
VAL_ 546 RLR_Blindness_FaultSts 0 "No Blindness" 1 "Blindness"  ;
VAL_ 546 RLR_DTC_ALIGNMENT_NOT_DONE 0 "No Fail" 1 "Fail"  ;
VAL_ 546 RLR_DTC_CORNER_RADAR_BLIND 0 "No Fail" 1 "Fail"  ;
VAL_ 546 RLR_DTC_CORNER_RADAR_MISALIGNED 0 "No Fail" 1 "Fail"  ;
VAL_ 546 RLR_DTC_DACORE_OOS 0 "No Fail" 1 "Fail"  ;
VAL_ 546 RLR_DTC_DSP_FAILURE 0 "No Fail" 1 "Fail"  ;
VAL_ 546 RLR_DTC_HARDWARE_FAILURE 0 "No Fail" 1 "Fail"  ;
VAL_ 546 RLR_DTC_INVALID_DATA_BCS 0 "No Fail" 1 "Fail"  ;
VAL_ 546 RLR_DTC_INVALID_DATA_EPS 0 "No Fail" 1 "Fail"  ;
VAL_ 546 RLR_DTC_INVALID_DATA_SOC 0 "No Fail" 1 "Fail"  ;
VAL_ 546 RLR_DTC_LOST_COMM_BCS 0 "No Fail" 1 "Fail"  ;
VAL_ 546 RLR_DTC_LOST_COMM_EPS 0 "No Fail" 1 "Fail"  ;
VAL_ 546 RLR_DTC_LOST_COMM_SOC 0 "No Fail" 1 "Fail"  ;
VAL_ 546 RLR_DTC_PUBLIC_CAN_BUSOFF 0 "No Fail" 1 "Fail"  ;
VAL_ 546 RLR_DTC_RADAR_OVER_TEMPERATURE 0 "No Fail" 1 "Fail"  ;
VAL_ 546 RLR_DTC_RADAR_SIDE_MISMATCH 0 "No Fail" 1 "Fail"  ;
VAL_ 546 RLR_DTC_SOC_Time_SYNC_FAIL 0 "No Fail" 1 "Fail"  ;
VAL_ 546 RLR_DTC_VARIANT_SELECTION_NOT_DONE 0 "No Fail" 1 "Fail"  ;
VAL_ 546 RLR_DTC_VBAT_HIGH 0 "No Fail" 1 "Fail"  ;
VAL_ 546 RLR_DTC_VBAT_LOW 0 "No Fail" 1 "Fail"  ;
VAL_ 546 RLR_EOL_CalibrationSts 0 "successfully calibrated" 1 "time out" 2 "target is missing" 3 "target distance is not correct" 4 "Horizontal bad angle" 5 "Vertical bad angle" 6 "NVM error" 7 "Cancelled by user" 255 "Not done calibration"  ;
VAL_ 546 RLR_Misalignment_FaultSts 0 "Aligned" 1 "Misaligned"  ;
VAL_ 546 RLR_ModulationSts 0 "ON" 1 "OFF"  ;
VAL_ 546 RLR_Radar_FaultSts 0 "No Fail" 1 "Fail" 0 "No Fail" 1 "Fail" 0 "No Fail" 1 "Fail" 0 "No Fail" 1 "Fail" 0 "No Fail" 1 "Fail"  ;
VAL_ 546 RLR_SDA_CalibrationSts 0 "successfully calibrated" 1 "calibration is processing" 2 "calibration is failed" 3 "cancelled by user" 255 "routine not started"  ;
VAL_ 546 RLR_SW_ReleaseType 0 "V(Version)" 1 "RC(Release Candidate)" 2 "LC (Local Release)"  ;
VAL_ 546 azOutOfProfileCause 0 "No Out" 1 "Out"  ;
VAL_ 546 azOutOfSpecCause 0 "No Out" 1 "Out"  ;
VAL_ 546 elOutOfProfileCause 0 "No Out" 1 "Out"  ;
VAL_ 546 elOutOfSpecCause 0 "No Out" 1 "Out"  ;
VAL_ 616 UMM_UsageModeSt 0 "Standby" 1 "Comfort" 2 "ToBeDRV(Reserved)" 3 "DRV" 7 "Invalid"  ;
VAL_ 616 VMM_OTAModeSt 0 "NonOTA Mode" 1 "OTA Mode" 2 "Invalid Value" 3 "reserved"  ;
